VERSION ""

NS_ :

BS_:

BU_: ECM

BO_ 2566834691 DM1_s3: 22 Vector__XXX
 SG_ FailureModeIdentifier5 : 160|5@1+ (1,0) [0|0] "" Vector__XXX
 SG_ FailureModeIdentifier4 : 128|5@1+ (1,0) [0|0] "" Vector__XXX
 SG_ FailureModeIdentifier3 : 96|5@1+ (1,0) [0|0] "" Vector__XXX
 SG_ FailureModeIdentifier2 : 64|5@1+ (1,0) [0|0] "" Vector__XXX
 SG_ FailureModeIdentifier1 : 32|5@1+ (1,0) [0|0] "" Vector__XXX
 SG_ SPN5 : 144|16@1+ (1,0) [0|65536] "" Vector__XXX
 SG_ SPN4 : 112|16@1+ (1,0) [0|65536] "" Vector__XXX
 SG_ SPN3 : 80|16@1+ (1,0) [0|65536] "" Vector__XXX
 SG_ SPN2 : 48|16@1+ (1,0) [0|65536] "" Vector__XXX
 SG_ SPN1 : 16|16@1+ (1,0) [0|65536] "" Vector__XXX
 SG_ RedStopLampStatus : 4|2@1+ (1,0) [0|3] "" Vector__XXX
 SG_ ProtectLampStatus : 0|2@1+ (1,0) [0|3] "" Vector__XXX
 SG_ AmberWarningLampStatus : 2|2@1+ (1,0) [0|3] "" Vector__XXX
 SG_ MalfunctionIndicatorLampStatus : 6|2@1+ (1,0) [0|3] "" Vector__XXX
 SG_ FlashRedStopLamp : 12|2@1+ (1,0) [0|3] "" Vector__XXX
 SG_ FlashProtectLamp : 8|2@1+ (1,0) [0|3] "" Vector__XXX
 SG_ FlashMalfuncIndicatorLamp : 14|2@1+ (1,0) [0|3] "" Vector__XXX
 SG_ FlashAmberWarningLamp : 10|2@1+ (1,0) [0|3] "" Vector__XXX
 SG_ OccurenceCount1 : 40|7@1+ (1,0) [0|126] "" Vector__XXX
 SG_ SPNConversionMethod1 : 47|1@1+ (1,0) [0|1] "" Vector__XXX
 SG_ SPNConversionMethod5 : 175|1@1+ (1,0) [0|1] "" Vector__XXX
 SG_ SPNConversionMethod4 : 143|1@1+ (1,0) [0|1] "" Vector__XXX
 SG_ SPNConversionMethod3 : 111|1@1+ (1,0) [0|1] "" Vector__XXX
 SG_ SPNConversionMethod2 : 79|1@1+ (1,0) [0|1] "" Vector__XXX
 SG_ OccurenceCount5 : 168|7@1+ (1,0) [0|126] "" Vector__XXX
 SG_ OccurenceCount4 : 136|7@1+ (1,0) [0|126] "" Vector__XXX
 SG_ OccurenceCount3 : 104|7@1+ (1,0) [0|126] "" Vector__XXX
 SG_ OccurenceCount2 : 72|7@1+ (1,0) [0|126] "" Vector__XXX
 SG_ SPN5High : 165|3@1+ (1,0) [0|7] "" Vector__XXX
 SG_ SPN4High : 133|3@1+ (1,0) [0|7] "" Vector__XXX
 SG_ SPN3High : 101|3@1+ (1,0) [0|7] "" Vector__XXX
 SG_ SPN2High : 69|3@1+ (1,0) [0|7] "" Vector__XXX
 SG_ SPN1High : 37|3@1+ (1,0) [0|7] "" Vector__XXX

BO_ 2566834711 DM1_s23: 22 Vector__XXX
 SG_ FailureModeIdentifier5 : 160|5@1+ (1,0) [0|0] "" Vector__XXX
 SG_ FailureModeIdentifier4 : 128|5@1+ (1,0) [0|0] "" Vector__XXX
 SG_ FailureModeIdentifier3 : 96|5@1+ (1,0) [0|0] "" Vector__XXX
 SG_ FailureModeIdentifier2 : 64|5@1+ (1,0) [0|0] "" Vector__XXX
 SG_ FailureModeIdentifier1 : 32|5@1+ (1,0) [0|0] "" Vector__XXX
 SG_ SPN5 : 144|16@1+ (1,0) [0|65536] "" Vector__XXX
 SG_ SPN4 : 112|16@1+ (1,0) [0|65536] "" Vector__XXX
 SG_ SPN3 : 80|16@1+ (1,0) [0|65536] "" Vector__XXX
 SG_ SPN2 : 48|16@1+ (1,0) [0|65536] "" Vector__XXX
 SG_ SPN1 : 16|16@1+ (1,0) [0|65536] "" Vector__XXX
 SG_ RedStopLampStatus : 4|2@1+ (1,0) [0|3] "" Vector__XXX
 SG_ ProtectLampStatus : 0|2@1+ (1,0) [0|3] "" Vector__XXX
 SG_ AmberWarningLampStatus : 2|2@1+ (1,0) [0|3] "" Vector__XXX
 SG_ MalfunctionIndicatorLampStatus : 6|2@1+ (1,0) [0|3] "" Vector__XXX
 SG_ FlashRedStopLamp : 12|2@1+ (1,0) [0|3] "" Vector__XXX
 SG_ FlashProtectLamp : 8|2@1+ (1,0) [0|3] "" Vector__XXX
 SG_ FlashMalfuncIndicatorLamp : 14|2@1+ (1,0) [0|3] "" Vector__XXX
 SG_ FlashAmberWarningLamp : 10|2@1+ (1,0) [0|3] "" Vector__XXX
 SG_ OccurenceCount1 : 40|7@1+ (1,0) [0|126] "" Vector__XXX
 SG_ SPNConversionMethod1 : 47|1@1+ (1,0) [0|1] "" Vector__XXX
 SG_ SPNConversionMethod5 : 175|1@1+ (1,0) [0|1] "" Vector__XXX
 SG_ SPNConversionMethod4 : 143|1@1+ (1,0) [0|1] "" Vector__XXX
 SG_ SPNConversionMethod3 : 111|1@1+ (1,0) [0|1] "" Vector__XXX
 SG_ SPNConversionMethod2 : 79|1@1+ (1,0) [0|1] "" Vector__XXX
 SG_ OccurenceCount5 : 168|7@1+ (1,0) [0|126] "" Vector__XXX
 SG_ OccurenceCount4 : 136|7@1+ (1,0) [0|126] "" Vector__XXX
 SG_ OccurenceCount3 : 104|7@1+ (1,0) [0|126] "" Vector__XXX
 SG_ OccurenceCount2 : 72|7@1+ (1,0) [0|126] "" Vector__XXX
 SG_ SPN5High : 165|3@1+ (1,0) [0|7] "" Vector__XXX
 SG_ SPN4High : 133|3@1+ (1,0) [0|7] "" Vector__XXX
 SG_ SPN3High : 101|3@1+ (1,0) [0|7] "" Vector__XXX
 SG_ SPN2High : 69|3@1+ (1,0) [0|7] "" Vector__XXX
 SG_ SPN1High : 37|3@1+ (1,0) [0|7] "" Vector__XXX

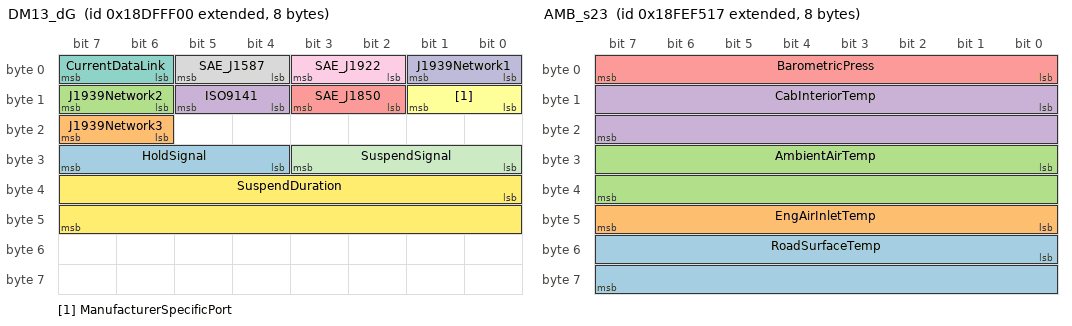
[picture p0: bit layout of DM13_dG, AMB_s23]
BO_ 2564816640 DM13_dG: 8 Vector__XXX
 SG_ HoldSignal : 28|4@1+ (1,0) [0|15] "" Vector__XXX
 SG_ J1939Network3 : 22|2@1+ (1,0) [0|3] "" Vector__XXX
 SG_ J1939Network2 : 14|2@1+ (1,0) [0|3] "" Vector__XXX
 SG_ ISO9141 : 12|2@1+ (1,0) [0|3] "" Vector__XXX
 SG_ SAE_J1850 : 10|2@1+ (1,0) [0|3] "" Vector__XXX
 SG_ ManufacturerSpecificPort : 8|2@1+ (1,0) [0|3] "" Vector__XXX
 SG_ CurrentDataLink : 6|2@1+ (1,0) [0|3] "" Vector__XXX
 SG_ SAE_J1587 : 4|2@1+ (1,0) [0|3] "" Vector__XXX
 SG_ SAE_J1922 : 2|2@1+ (1,0) [0|3] "" Vector__XXX
 SG_ J1939Network1 : 0|2@1+ (1,0) [0|3] "" Vector__XXX
 SG_ SuspendSignal : 24|4@1+ (1,0) [0|15] "" Vector__XXX
 SG_ SuspendDuration : 32|16@1+ (1,0) [0|64255] "seconds" Vector__XXX

BO_ 2566844705 CCVS_s33: 8 Vector__XXX
 SG_ EngIdleIncrementSwitch : 56|2@1+ (1,0) [0|3] "" Vector__XXX
 SG_ EngIdleDecrementSwitch : 58|2@1+ (1,0) [0|3] "" Vector__XXX
 SG_ EngShutdownOverrideSwitch : 62|2@1+ (1,0) [0|3] "" Vector__XXX
 SG_ EngTestModeSwitch : 60|2@1+ (1,0) [0|3] "" Vector__XXX
 SG_ CruiseCtrlStates : 53|3@1+ (1,0) [0|7] "" Vector__XXX
 SG_ PTOState : 48|5@1+ (1,0) [0|31] "" Vector__XXX
 SG_ CruiseCtrlSetSpeed : 40|8@1+ (1,0) [0|250] "km/h" Vector__XXX
 SG_ CruiseCtrlAccelerateSwitch : 38|2@1+ (1,0) [0|3] "" Vector__XXX
 SG_ CruiseCtrlResumeSwitch : 36|2@1+ (1,0) [0|3] "" Vector__XXX
 SG_ CruiseCtrlCoastSwitch : 34|2@1+ (1,0) [0|3] "" Vector__XXX
 SG_ CruiseCtrlSetSwitch : 32|2@1+ (1,0) [0|3] "" Vector__XXX
 SG_ ClutchSwitch : 30|2@1+ (1,0) [0|3] "" Vector__XXX
 SG_ BrakeSwitch : 28|2@1+ (1,0) [0|3] "" Vector__XXX
 SG_ CruiseCtrlEnableSwitch : 26|2@1+ (1,0) [0|3] "" Vector__XXX
 SG_ CruiseCtrlActive : 24|2@1+ (1,0) [0|3] "" Vector__XXX
 SG_ WheelBasedVehicleSpeed : 8|16@1+ (0.00390625,0) [0|250.996] "km/h" Vector__XXX
 SG_ CruiseCtrlPauseSwitch : 4|2@1+ (1,0) [0|3] "" Vector__XXX
 SG_ ParkingBrakeSwitch : 2|2@1+ (1,0) [0|3] "" Vector__XXX
 SG_ TwoSpeedAxleSwitch : 0|2@1+ (1,0) [0|3] "" Vector__XXX

BO_ 2566845719 AMB_s23: 8 Vector__XXX
 SG_ RoadSurfaceTemp : 48|16@1+ (0.03125,-273) [-273|1735] "°C" Vector__XXX
 SG_ EngAirInletTemp : 40|8@1+ (1,-40) [-40|210] "°C" Vector__XXX
 SG_ AmbientAirTemp : 24|16@1+ (0.03125,-273) [-273|1735] "°C" Vector__XXX
 SG_ CabInteriorTemp : 8|16@1+ (0.03125,-273) [-273|1735] "°C" Vector__XXX
 SG_ BarometricPress : 0|8@1+ (0.5,0) [0|125] "kPa" Vector__XXX

BO_ 2565347072 ACKM_d23: 8 Vector__XXX
 SG_ AddressBusy m3 : 32|8@1+ (1,0) [0|255] "" Vector__XXX
 SG_ ParameterGroupNumber : 40|24@1+ (1,0) [0|16777215] "" Vector__XXX
 SG_ GroupFunctionValue : 8|8@1+ (1,0) [0|255] "" Vector__XXX
 SG_ ControlByte M : 0|8@1+ (1,0) [0|255] "" Vector__XXX
 SG_ AddressAccessDenied m2 : 32|8@1+ (1,0) [0|255] "" Vector__XXX
 SG_ AddressNegativeAcknowledgement m1 : 32|8@1+ (1,0) [0|255] "" Vector__XXX
 SG_ AddressAcknowledged m0 : 32|8@1+ (1,0) [0|255] "" Vector__XXX

BO_ 2565480727 RQST_d33: 3 Vector__XXX
 SG_ ParameterGroupNumber : 0|24@1+ (1,0) [0|16777215] "" Vector__XXX

BO_ 2565537785 RQST_S249_dall: 3 Vector__XXX
 SG_ ParameterGroupNumber : 0|24@1+ (1,0) [0|16777215] "" Vector__XXX

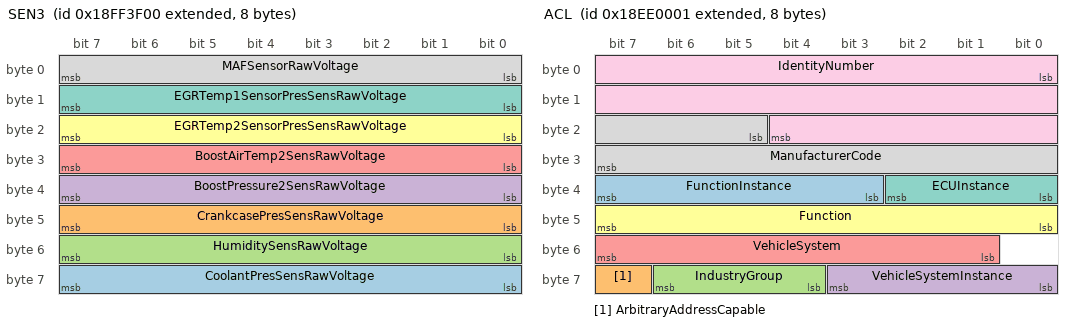
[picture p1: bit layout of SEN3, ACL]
BO_ 2566864640 SEN3: 8 Vector__XXX
 SG_ CoolantPresSensRawVoltage : 56|8@1+ (20,0) [0|5000] "mV" Vector__XXX
 SG_ CrankcasePresSensRawVoltage : 40|8@1+ (20,0) [0|5000] "mV" Vector__XXX
 SG_ HumiditySensRawVoltage : 48|8@1+ (20,0) [0|5000] "mV" Vector__XXX
 SG_ BoostPressure2SensRawVoltage : 32|8@1+ (20,0) [0|5000] "mV" Vector__XXX
 SG_ BoostAirTemp2SensRawVoltage : 24|8@1+ (20,0) [0|5000] "mV" Vector__XXX
 SG_ EGRTemp2SensorPresSensRawVoltage : 16|8@1+ (20,0) [0|5000] "mV" Vector__XXX
 SG_ EGRTemp1SensorPresSensRawVoltage : 8|8@1+ (20,0) [0|5000] "mV" Vector__XXX
 SG_ MAFSensorRawVoltage : 0|8@1+ (20,0) [0|5000] "mV" Vector__XXX

BO_ 2566750208 DM28: 22 Vector__XXX
 SG_ FailureModeIdentifier5 : 160|5@1+ (1,0) [0|0] "" Vector__XXX
 SG_ FailureModeIdentifier4 : 128|5@1+ (1,0) [0|0] "" Vector__XXX
 SG_ FailureModeIdentifier3 : 96|5@1+ (1,0) [0|0] "" Vector__XXX
 SG_ FailureModeIdentifier2 : 64|5@1+ (1,0) [0|0] "" Vector__XXX
 SG_ FailureModeIdentifier1 : 32|5@1+ (1,0) [0|0] "" Vector__XXX
 SG_ FlashRedStopLamp : 12|2@1+ (1,0) [0|3] "" Vector__XXX
 SG_ FlashProtectLamp : 8|2@1+ (1,0) [0|3] "" Vector__XXX
 SG_ FlashMalfuncIndicatorLamp : 14|2@1+ (1,0) [0|3] "" Vector__XXX
 SG_ FlashAmberWarningLamp : 10|2@1+ (1,0) [0|3] "" Vector__XXX
 SG_ OccurenceCount5 : 168|7@1+ (1,0) [0|126] "" Vector__XXX
 SG_ OccurenceCount4 : 136|7@1+ (1,0) [0|126] "" Vector__XXX
 SG_ OccurenceCount3 : 104|7@1+ (1,0) [0|126] "" Vector__XXX
 SG_ OccurenceCount2 : 72|7@1+ (1,0) [0|126] "" Vector__XXX
 SG_ SPNConversionMethod5 : 175|1@1+ (1,0) [0|1] "" Vector__XXX
 SG_ SPNConversionMethod4 : 143|1@1+ (1,0) [0|1] "" Vector__XXX
 SG_ SPNConversionMethod3 : 111|1@1+ (1,0) [0|1] "" Vector__XXX
 SG_ SPNConversionMethod2 : 79|1@1+ (1,0) [0|1] "" Vector__XXX
 SG_ SPNConversionMethod1 : 47|1@1+ (1,0) [0|1] "" Vector__XXX
 SG_ SPN5High : 165|3@1+ (1,0) [0|7] "" Vector__XXX
 SG_ SPN5 : 144|16@1+ (1,0) [0|65536] "" Vector__XXX
 SG_ SPN4High : 133|3@1+ (1,0) [0|7] "" Vector__XXX
 SG_ SPN4 : 112|16@1+ (1,0) [0|65536] "" Vector__XXX
 SG_ SPN3High : 101|3@1+ (1,0) [0|7] "" Vector__XXX
 SG_ SPN3 : 80|16@1+ (1,0) [0|65536] "" Vector__XXX
 SG_ SPN2High : 69|3@1+ (1,0) [0|7] "" Vector__XXX
 SG_ SPN2 : 48|16@1+ (1,0) [0|65536] "" Vector__XXX
 SG_ SPN1High : 37|3@1+ (1,0) [0|7] "" Vector__XXX
 SG_ SPN1 : 16|16@1+ (1,0) [0|65536] "" Vector__XXX
 SG_ RedStopLampStatus : 4|2@1+ (1,0) [0|3] "" Vector__XXX
 SG_ ProtectLampStatus : 0|2@1+ (1,0) [0|3] "" Vector__XXX
 SG_ AmberWarningLampStatus : 2|2@1+ (1,0) [0|3] "" Vector__XXX
 SG_ MalfunctionIndicatorLampStatus : 6|2@1+ (1,0) [0|3] "" Vector__XXX
 SG_ OccurenceCount1 : 40|7@1+ (1,0) [0|126] "" Vector__XXX

BO_ 2566750720 DM27: 22 Vector__XXX
 SG_ OccurenceCount5 : 168|7@1+ (1,0) [0|126] "" Vector__XXX
 SG_ OccurenceCount4 : 136|7@1+ (1,0) [0|126] "" Vector__XXX
 SG_ OccurenceCount3 : 104|7@1+ (1,0) [0|126] "" Vector__XXX
 SG_ OccurenceCount2 : 72|7@1+ (1,0) [0|126] "" Vector__XXX
 SG_ SPNConversionMethod5 : 175|1@1+ (1,0) [0|1] "" Vector__XXX
 SG_ SPNConversionMethod4 : 143|1@1+ (1,0) [0|1] "" Vector__XXX
 SG_ SPNConversionMethod3 : 111|1@1+ (1,0) [0|1] "" Vector__XXX
 SG_ SPNConversionMethod2 : 79|1@1+ (1,0) [0|1] "" Vector__XXX
 SG_ SPN5High : 165|3@1+ (1,0) [0|7] "" Vector__XXX
 SG_ SPN5 : 144|16@1+ (1,0) [0|65536] "" Vector__XXX
 SG_ SPN4High : 133|3@1+ (1,0) [0|7] "" Vector__XXX
 SG_ SPN4 : 112|16@1+ (1,0) [0|65536] "" Vector__XXX
 SG_ SPN3High : 101|3@1+ (1,0) [0|7] "" Vector__XXX
 SG_ SPN3 : 80|16@1+ (1,0) [0|65536] "" Vector__XXX
 SG_ SPN2High : 69|3@1+ (1,0) [0|7] "" Vector__XXX
 SG_ SPN2 : 48|16@1+ (1,0) [0|65536] "" Vector__XXX
 SG_ SPN1High : 37|3@1+ (1,0) [0|7] "" Vector__XXX
 SG_ SPN1 : 16|16@1+ (1,0) [0|65536] "" Vector__XXX
 SG_ FailureModeIdentifier5 : 160|5@1+ (1,0) [0|0] "" Vector__XXX
 SG_ FailureModeIdentifier4 : 128|5@1+ (1,0) [0|0] "" Vector__XXX
 SG_ FailureModeIdentifier3 : 96|5@1+ (1,0) [0|0] "" Vector__XXX
 SG_ FailureModeIdentifier2 : 64|5@1+ (1,0) [0|0] "" Vector__XXX
 SG_ FailureModeIdentifier1 : 32|5@1+ (1,0) [0|0] "" Vector__XXX
 SG_ FlashRedStopLamp : 12|2@1+ (1,0) [0|3] "" Vector__XXX
 SG_ FlashProtectLamp : 8|2@1+ (1,0) [0|3] "" Vector__XXX
 SG_ FlashMalfuncIndicatorLamp : 14|2@1+ (1,0) [0|3] "" Vector__XXX
 SG_ FlashAmberWarningLamp : 10|2@1+ (1,0) [0|3] "" Vector__XXX
 SG_ RedStopLampStatus : 4|2@1+ (1,0) [0|3] "" Vector__XXX
 SG_ ProtectLampStatus : 0|2@1+ (1,0) [0|3] "" Vector__XXX
 SG_ AmberWarningLampStatus : 2|2@1+ (1,0) [0|3] "" Vector__XXX
 SG_ MalfunctionIndicatorLampStatus : 6|2@1+ (1,0) [0|3] "" Vector__XXX
 SG_ OccurenceCount1 : 40|7@1+ (1,0) [0|126] "" Vector__XXX
 SG_ SPNConversionMethod1 : 47|1@1+ (1,0) [0|1] "" Vector__XXX

BO_ 2566886393 DTHM: 8 Vector__XXX

BO_ 2565734401 ACL: 8 Vector__XXX
 SG_ FunctionInstance : 35|5@1- (1,0) [0|31] "" Vector__XXX
 SG_ ArbitraryAddressCapable : 63|1@1+ (1,0) [0|1] "" Vector__XXX
 SG_ IndustryGroup : 60|3@1+ (1,0) [0|7] "" Vector__XXX
 SG_ VehicleSystemInstance : 56|4@1+ (1,0) [0|15] "" Vector__XXX
 SG_ VehicleSystem : 49|7@1+ (1,0) [0|127] "" Vector__XXX
 SG_ Function : 40|8@1+ (1,0) [0|255] "" Vector__XXX
 SG_ ECUInstance : 32|3@1+ (1,0) [0|7] "" Vector__XXX
 SG_ ManufacturerCode : 21|11@1- (1,0) [0|2047] "" Vector__XXX
 SG_ IdentityNumber : 0|21@1- (1,0) [0|2097152] "" Vector__XXX

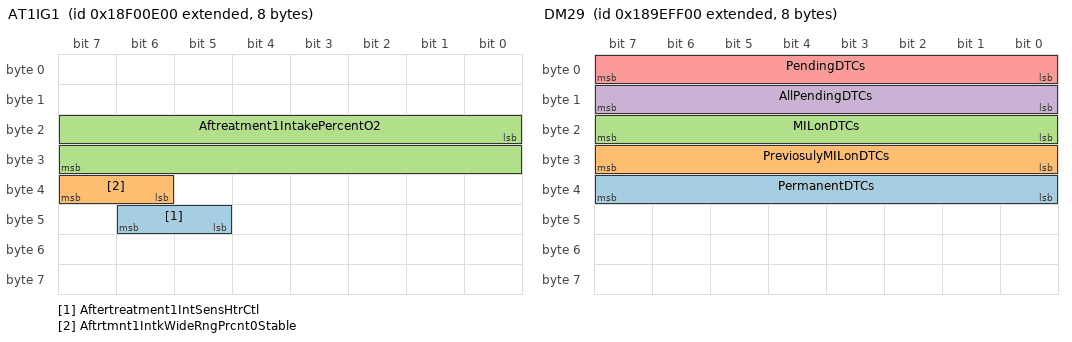
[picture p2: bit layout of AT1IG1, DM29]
BO_ 2565869056 AT1IG1: 8 Vector__XXX
 SG_ Aftertreatment1IntSensHtrCtl : 45|2@1+ (1,0) [0|3] "" Vector__XXX
 SG_ Aftrtmnt1IntkWideRngPrcnt0Stable : 38|2@1+ (1,0) [0|3] "" Vector__XXX
 SG_ Aftreatment1IntakePercentO2 : 16|16@1+ (0.000514,-12) [-12|21.68499] "%" Vector__XXX

BO_ 2566770688 IC2: 8 Vector__XXX
 SG_ EngineIntakeManifold1AbsPress : 32|8@1+ (2,0) [0|500] "kPa" Vector__XXX

BO_ 2560556800 DM29: 8 Vector__XXX
 SG_ PermanentDTCs : 32|8@1- (1,0) [0|250] "" Vector__XXX
 SG_ PreviosulyMILonDTCs : 24|8@1- (1,0) [0|250] "" Vector__XXX
 SG_ MILonDTCs : 16|8@1- (1,0) [0|250] "" Vector__XXX
 SG_ AllPendingDTCs : 8|8@1- (1,0) [0|250] "" Vector__XXX
 SG_ PendingDTCs : 0|8@1- (1,0) [0|250] "" Vector__XXX

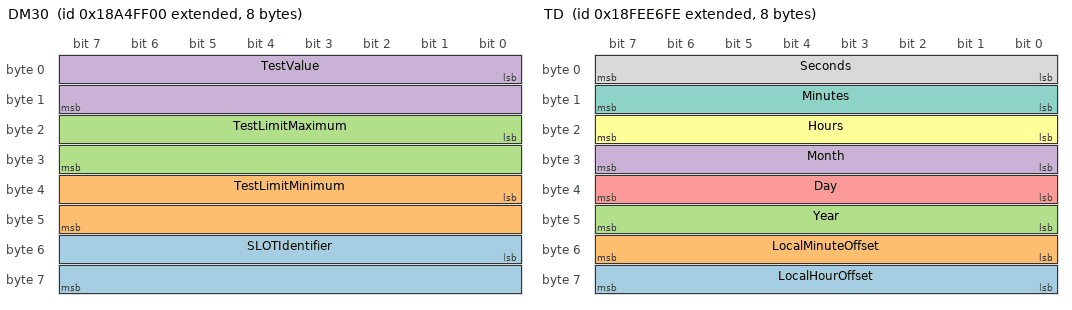
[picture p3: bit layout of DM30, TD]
BO_ 2560950016 DM30: 8 Vector__XXX
 SG_ SLOTIdentifier : 48|16@1+ (1,0) [0|64255] "" Vector__XXX
 SG_ TestLimitMinimum : 32|16@1+ (1,0) [0|64255] "" Vector__XXX
 SG_ TestLimitMaximum : 16|16@1+ (1,0) [0|64255] "" Vector__XXX
 SG_ TestValue : 0|16@1+ (1,0) [0|64255] "" Vector__XXX

BO_ 2566842110 TD: 8 Vector__XXX
 SG_ LocalHourOffset : 56|8@1- (1,-125) [-125|125] "hour" Vector__XXX
 SG_ LocalMinuteOffset : 48|8@1- (1,-125) [-125|125] "min" Vector__XXX
 SG_ Year : 40|8@1+ (1,1985) [1985|2240] "" Vector__XXX
 SG_ Month : 24|8@1+ (1,0) [0|250] "" Vector__XXX
 SG_ Day : 32|8@1+ (0.25,0) [0|62.5] "days" Vector__XXX
 SG_ Hours : 16|8@1+ (1,0) [0|255] "" Vector__XXX
 SG_ Minutes : 8|8@1+ (1,0) [0|256] "min" Vector__XXX
 SG_ Seconds : 0|8@1+ (0.25,0) [0|63.75] "sec" Vector__XXX

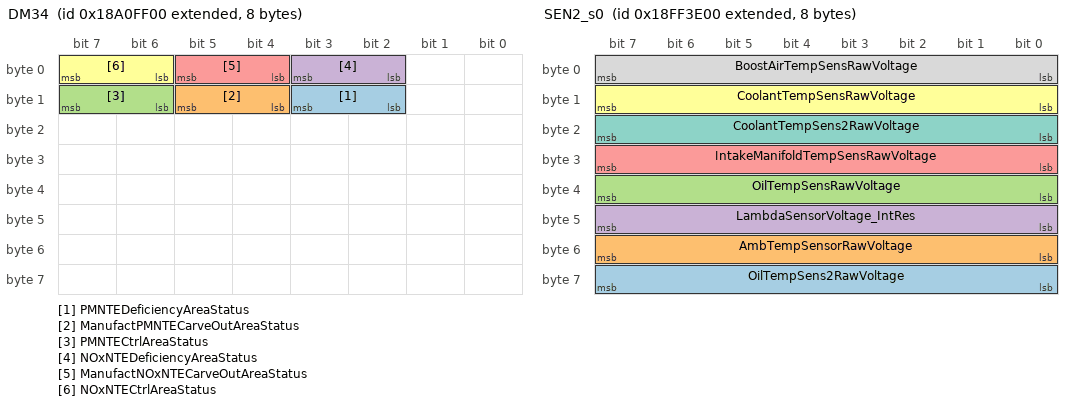
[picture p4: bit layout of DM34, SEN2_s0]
BO_ 2560687872 DM34: 8 Vector__XXX
 SG_ PMNTEDeficiencyAreaStatus : 10|2@1+ (1,0) [0|3] "" Vector__XXX
 SG_ ManufactPMNTECarveOutAreaStatus : 12|2@1+ (1,0) [0|3] "" Vector__XXX
 SG_ PMNTECtrlAreaStatus : 14|2@1+ (1,0) [0|3] "" Vector__XXX
 SG_ NOxNTEDeficiencyAreaStatus : 2|2@1+ (1,0) [0|3] "" Vector__XXX
 SG_ ManufactNOxNTECarveOutAreaStatus : 4|2@1+ (1,0) [0|3] "" Vector__XXX
 SG_ NOxNTECtrlAreaStatus : 6|2@1+ (1,0) [0|3] "" Vector__XXX

BO_ 2566755328 EEC7: 8 Vector__XXX
 SG_ Breather_Sep_Speed : 32|16@1+ (1,0) [0|64255] "rpm" Vector__XXX
 SG_ EGRVlvPosition : 0|16@1+ (0.0025,0) [0|160.6375] "%" Vector__XXX

BO_ 2566743552 ET4: 8 Vector__XXX
 SG_ EngCoolantTemp2 : 0|8@1+ (1,-40) [-40|210] "°C" Vector__XXX

BO_ 2566822144 TCI3: 8 Vector__XXX
 SG_ EngTurbo2CompressorInletPress : 16|16@1+ (0.0078125,-250) [-250|261.9921875] "kPa" Vector__XXX

BO_ 2566864384 SEN2_s0: 8 Vector__XXX
 SG_ OilTempSens2RawVoltage : 56|8@1+ (20,0) [0|5000] "mV" Vector__XXX
 SG_ AmbTempSensorRawVoltage : 48|8@1+ (19.608,0) [0|5000] "mV" Vector__XXX
 SG_ OilTempSensRawVoltage : 32|8@1+ (20,0) [0|5000] "mV" Vector__XXX
 SG_ LambdaSensorVoltage_IntRes : 40|8@1+ (20,0) [0|5000] "mV" Vector__XXX
 SG_ IntakeManifoldTempSensRawVoltage : 24|8@1+ (20,0) [0|5000] "mV" Vector__XXX
 SG_ CoolantTempSensRawVoltage : 8|8@1+ (20,0) [0|5000] "mV" Vector__XXX
 SG_ CoolantTempSens2RawVoltage : 16|8@1+ (20,0) [0|5000] "mV" Vector__XXX
 SG_ BoostAirTempSensRawVoltage : 0|8@1+ (20,0) [0|5000] "mV" Vector__XXX

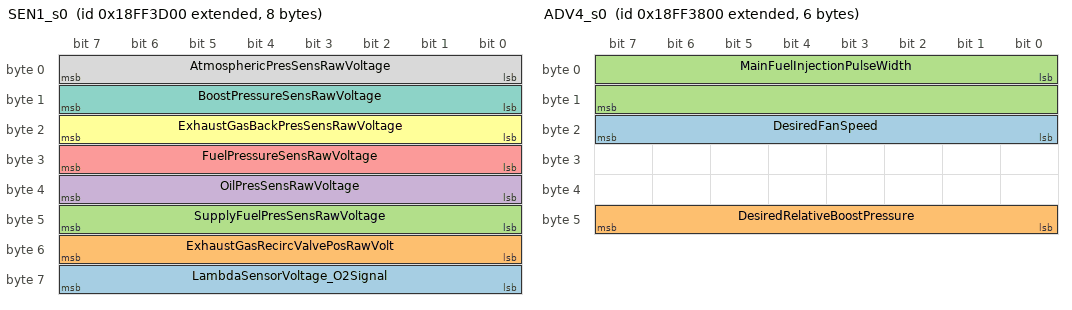
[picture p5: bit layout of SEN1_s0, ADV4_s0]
BO_ 2566864128 SEN1_s0: 8 Vector__XXX
 SG_ LambdaSensorVoltage_O2Signal : 56|8@1+ (20,0) [0|5000] "mV" Vector__XXX
 SG_ ExhaustGasRecircValvePosRawVolt : 48|8@1+ (20,0) [0|5000] "mV" Vector__XXX
 SG_ SupplyFuelPresSensRawVoltage : 40|8@1+ (20,0) [0|5000] "mV" Vector__XXX
 SG_ OilPresSensRawVoltage : 32|8@1+ (20,0) [0|5000] "mV" Vector__XXX
 SG_ FuelPressureSensRawVoltage : 24|8@1+ (20,0) [0|5000] "mV" Vector__XXX
 SG_ ExhaustGasBackPresSensRawVoltage : 16|8@1+ (20,0) [0|5000] "mV" Vector__XXX
 SG_ BoostPressureSensRawVoltage : 8|8@1+ (20,0) [0|5000] "mV" Vector__XXX
 SG_ AtmosphericPresSensRawVoltage : 0|8@1+ (20,0) [0|5000] "mV" Vector__XXX

BO_ 2566862848 ADV4_s0: 6 Vector__XXX
 SG_ DesiredFanSpeed : 16|8@1+ (14,0) [0|3570] "rpm" Vector__XXX
 SG_ DesiredRelativeBoostPressure : 40|8@1+ (2,0) [0|500] "kPa" Vector__XXX
 SG_ MainFuelInjectionPulseWidth : 0|16@1+ (0.58,0) [0|37448] "microsec" Vector__XXX

BO_ 2566862080 ADV1_s0: 8 Vector__XXX
 SG_ LambdaSensorMeasuredValue : 40|8@1+ (0.1,0) [0|25] "" Vector__XXX
 SG_ LambdaSensorTemperatureValue : 24|8@1+ (1,600) [600|850] "C" Vector__XXX

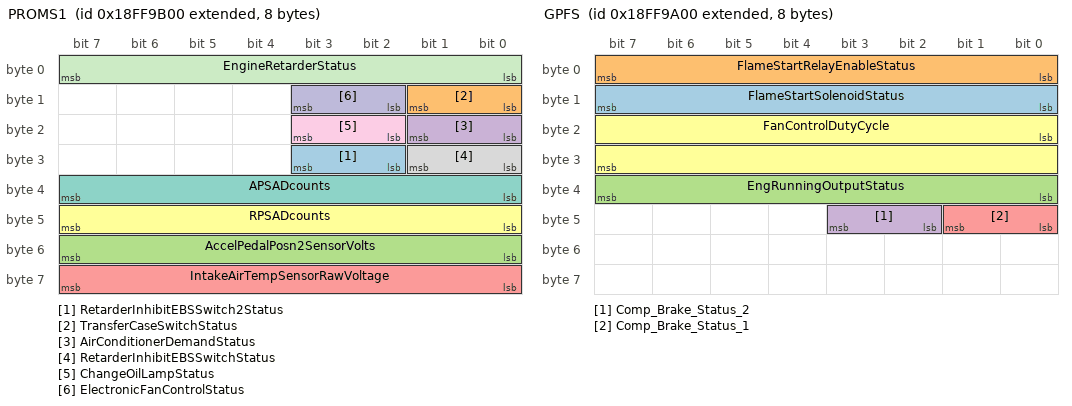
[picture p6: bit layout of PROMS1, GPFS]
BO_ 2566888192 PROMS1: 8 Vector__XXX
 SG_ RetarderInhibitEBSSwitch2Status : 26|2@1+ (1,0) [0|3] "flag" Vector__XXX
 SG_ TransferCaseSwitchStatus : 8|2@1+ (1,0) [0|3] "flag" Vector__XXX
 SG_ AccelPedalPosn2SensorVolts : 48|8@1+ (0.0196,0) [0|4.91764] "Volts" Vector__XXX
 SG_ AirConditionerDemandStatus : 16|2@1+ (1,0) [0|3] "flag" Vector__XXX
 SG_ IntakeAirTempSensorRawVoltage : 56|8@1+ (19.608,0) [0|5000] "mV" Vector__XXX
 SG_ RPSADcounts : 40|8@1+ (0.0196,0) [0|4.91764] "Volts" Vector__XXX
 SG_ APSADcounts : 32|8@1+ (0.0196,0) [0|4.91764] "Volts" Vector__XXX
 SG_ RetarderInhibitEBSSwitchStatus : 24|2@1+ (1,0) [0|3] "flag" Vector__XXX
 SG_ ChangeOilLampStatus : 18|2@1+ (1,0) [0|3] "flag" Vector__XXX
 SG_ ElectronicFanControlStatus : 10|2@1+ (1,0) [0|3] "flag" Vector__XXX
 SG_ EngineRetarderStatus : 0|8@1+ (1,0) [0|255] "flag" Vector__XXX

BO_ 2566887936 GPFS: 8 Vector__XXX
 SG_ FlameStartSolenoidStatus : 8|8@1+ (1,0) [0|255] "" Vector__XXX
 SG_ FlameStartRelayEnableStatus : 0|8@1+ (1,0) [0|255] "" Vector__XXX
 SG_ EngRunningOutputStatus : 32|8@1+ (1,0) [0|255] "" Vector__XXX
 SG_ Comp_Brake_Status_2 : 42|2@1+ (1,0) [0|3] "" Vector__XXX
 SG_ Comp_Brake_Status_1 : 40|2@1+ (1,0) [0|3] "" Vector__XXX
 SG_ FanControlDutyCycle : 16|16@1+ (1.556E-005,0) [0|1.0197246] "" Vector__XXX

BO_ 2566888448 PROID1: 70 Vector__XXX
 SG_ VEH_MOD_10 : 552|8@1+ (1,0) [0|255] "ASCII" Vector__XXX
 SG_ VEH_MOD_09 : 544|8@1+ (1,0) [0|255] "ASCII" Vector__XXX
 SG_ VEH_MOD_08 : 536|8@1+ (1,0) [0|255] "ASCII" Vector__XXX
 SG_ VEH_MOD_07 : 528|8@1+ (1,0) [0|255] "ASCII" Vector__XXX
 SG_ VEH_MOD_06 : 520|8@1+ (1,0) [0|255] "ASCII" Vector__XXX
 SG_ VEH_MOD_05 : 512|8@1+ (1,0) [0|255] "ASCII" Vector__XXX
 SG_ VEH_MOD_04 : 504|8@1+ (1,0) [0|255] "ASCII" Vector__XXX
 SG_ VEH_MOD_03 : 496|8@1+ (1,0) [0|255] "ASCII" Vector__XXX
 SG_ VEH_MOD_02 : 488|8@1+ (1,0) [0|255] "ASCII" Vector__XXX
 SG_ VEH_MOD_01 : 480|8@1+ (1,0) [0|255] "ASCII" Vector__XXX
 SG_ ENG_TYPE_ID_20 : 472|8@1+ (1,0) [0|255] "ASCII" Vector__XXX
 SG_ ENG_TYPE_ID_19 : 464|8@1+ (1,0) [0|255] "ASCII" Vector__XXX
 SG_ ENG_TYPE_ID_18 : 456|8@1+ (1,0) [0|255] "ASCII" Vector__XXX
 SG_ ENG_TYPE_ID_17 : 448|8@1+ (1,0) [0|255] "ASCII" Vector__XXX
 SG_ ENG_TYPE_ID_16 : 440|8@1+ (1,0) [0|255] "ASCII" Vector__XXX
 SG_ ENG_TYPE_ID_15 : 432|8@1+ (1,0) [0|255] "ASCII" Vector__XXX
 SG_ ENG_TYPE_ID_14 : 424|8@1+ (1,0) [0|255] "ASCII" Vector__XXX
 SG_ ENG_TYPE_ID_13 : 416|8@1+ (1,0) [0|255] "ASCII" Vector__XXX
 SG_ ENG_TYPE_ID_12 : 408|8@1+ (1,0) [0|255] "ASCII" Vector__XXX
 SG_ ENG_TYPE_ID_11 : 400|8@1+ (1,0) [0|255] "ASCII" Vector__XXX
 SG_ ENG_TYPE_ID_10 : 392|8@1+ (1,0) [0|255] "ASCII" Vector__XXX
 SG_ ENG_TYPE_ID_09 : 384|8@1+ (1,0) [0|255] "ASCII" Vector__XXX
 SG_ ENG_TYPE_ID_08 : 376|8@1+ (1,0) [0|255] "ASCII" Vector__XXX
 SG_ ENG_TYPE_ID_07 : 368|8@1+ (1,0) [0|255] "ASCII" Vector__XXX
 SG_ ENG_TYPE_ID_06 : 360|8@1+ (1,0) [0|255] "ASCII" Vector__XXX
 SG_ ENG_TYPE_ID_05 : 352|8@1+ (1,0) [0|255] "ASCII" Vector__XXX
 SG_ ENG_TYPE_ID_04 : 344|8@1+ (1,0) [0|255] "ASCII" Vector__XXX
 SG_ ENG_TYPE_ID_03 : 336|8@1+ (1,0) [0|255] "ASCII" Vector__XXX
 SG_ ENG_TYPE_ID_02 : 328|8@1+ (1,0) [0|255] "ASCII" Vector__XXX
 SG_ ENG_TYPE_ID_01 : 320|8@1+ (1,0) [0|255] "ASCII" Vector__XXX
 SG_ NRATED_APPL_ID_20 : 312|8@1+ (1,0) [0|255] "ASCII" Vector__XXX
 SG_ NRATED_APPL_ID_19 : 304|8@1+ (1,0) [0|255] "ASCII" Vector__XXX
 SG_ NRATED_APPL_ID_18 : 296|8@1+ (1,0) [0|255] "ASCII" Vector__XXX
 SG_ NRATED_APPL_ID_17 : 288|8@1+ (1,0) [0|255] "ASCII" Vector__XXX
 SG_ NRATED_APPL_ID_16 : 280|8@1+ (1,0) [0|255] "ASCII" Vector__XXX
 SG_ NRATED_APPL_ID_15 : 272|8@1+ (1,0) [0|255] "ASCII" Vector__XXX
 SG_ NRATED_APPL_ID_14 : 264|8@1+ (1,0) [0|255] "ASCII" Vector__XXX
 SG_ NRATED_APPL_ID_13 : 256|8@1+ (1,0) [0|255] "ASCII" Vector__XXX
 SG_ NRATED_APPL_ID_12 : 248|8@1+ (1,0) [0|255] "ASCII" Vector__XXX
 SG_ NRATED_APPL_ID_11 : 240|8@1+ (1,0) [0|255] "ASCII" Vector__XXX
 SG_ NRATED_APPL_ID_10 : 232|8@1+ (1,0) [0|255] "ASCII" Vector__XXX
 SG_ NRATED_APPL_ID_09 : 224|8@1+ (1,0) [0|255] "ASCII" Vector__XXX
 SG_ NRATED_APPL_ID_08 : 216|8@1+ (1,0) [0|255] "ASCII" Vector__XXX
 SG_ NRATED_APPL_ID_07 : 208|8@1+ (1,0) [0|255] "ASCII" Vector__XXX
 SG_ NRATED_APPL_ID_06 : 200|8@1+ (1,0) [0|255] "ASCII" Vector__XXX
 SG_ NRATED_APPL_ID_05 : 192|8@1+ (1,0) [0|255] "ASCII" Vector__XXX
 SG_ NRATED_APPL_ID_04 : 184|8@1+ (1,0) [0|255] "ASCII" Vector__XXX
 SG_ NRATED_APPL_ID_03 : 176|8@1+ (1,0) [0|255] "ASCII" Vector__XXX
 SG_ NRATED_APPL_ID_02 : 168|8@1+ (1,0) [0|255] "ASCII" Vector__XXX
 SG_ NRATED_APPL_ID_01 : 160|8@1+ (1,0) [0|255] "ASCII" Vector__XXX
 SG_ RATING_ID_20 : 152|8@1+ (1,0) [0|255] "ASCII" Vector__XXX
 SG_ RATING_ID_19 : 144|8@1+ (1,0) [0|255] "ASCII" Vector__XXX
 SG_ RATING_ID_18 : 136|8@1+ (1,0) [0|255] "ASCII" Vector__XXX
 SG_ RATING_ID_17 : 128|8@1+ (1,0) [0|255] "ASCII" Vector__XXX
 SG_ RATING_ID_16 : 120|8@1+ (1,0) [0|255] "ASCII" Vector__XXX
 SG_ RATING_ID_15 : 112|8@1+ (1,0) [0|255] "ASCII" Vector__XXX
 SG_ RATING_ID_14 : 104|8@1+ (1,0) [0|255] "ASCII" Vector__XXX
 SG_ RATING_ID_13 : 96|8@1+ (1,0) [0|255] "ASCII" Vector__XXX
 SG_ RATING_ID_12 : 88|8@1+ (1,0) [0|255] "ASCII" Vector__XXX
 SG_ RATING_ID_11 : 80|8@1+ (1,0) [0|255] "ASCII" Vector__XXX
 SG_ RATING_ID_10 : 72|8@1+ (1,0) [0|255] "ASCII" Vector__XXX
 SG_ RATING_ID_09 : 64|8@1+ (1,0) [0|255] "ASCII" Vector__XXX
 SG_ RATING_ID_08 : 56|8@1+ (1,0) [0|255] "ASCII" Vector__XXX
 SG_ RATING_ID_07 : 48|8@1+ (1,0) [0|255] "ASCII" Vector__XXX
 SG_ RATING_ID_06 : 40|8@1+ (1,0) [0|255] "ASCII" Vector__XXX
 SG_ RATING_ID_05 : 32|8@1+ (1,0) [0|255] "ASCII" Vector__XXX
 SG_ RATING_ID_04 : 24|8@1+ (1,0) [0|255] "ASCII" Vector__XXX
 SG_ RATING_ID_03 : 16|8@1+ (1,0) [0|255] "ASCII" Vector__XXX
 SG_ RATING_ID_02 : 8|8@1+ (1,0) [0|255] "ASCII" Vector__XXX
 SG_ RATING_ID_01 : 0|8@1+ (1,0) [0|255] "ASCII" Vector__XXX

CM_ BO_ 2566834691 "Active diagnostic trouble codes";
CM_ SG_ 2566834691 FailureModeIdentifier5 "The FMI defines the type of failure detected in the subsystem identified by an SPN.";
CM_ SG_ 2566834691 FailureModeIdentifier4 "The FMI defines the type of failure detected in the subsystem identified by an SPN.";
CM_ SG_ 2566834691 FailureModeIdentifier3 "The FMI defines the type of failure detected in the subsystem identified by an SPN.";
CM_ SG_ 2566834691 FailureModeIdentifier2 "The FMI defines the type of failure detected in the subsystem identified by an SPN.";
CM_ SG_ 2566834691 FailureModeIdentifier1 "The FMI defines the type of failure detected in the subsystem identified by an SPN.";
CM_ SG_ 2566834691 SPN5 "SPN #5 (Conversion Version 4)";
CM_ SG_ 2566834691 SPN4 "SPN #4 (Conversion Version 4)";
CM_ SG_ 2566834691 SPN3 "SPN #3 (Conversion Version 4)";
CM_ SG_ 2566834691 SPN2 "SPN #2 (Conversion Version 4)";
CM_ SG_ 2566834691 SPN1 "SPN #1 (Conversion Version 4)";
CM_ SG_ 2566834691 RedStopLampStatus "This lamp is uesed to relay trouble code information that is of a severe enought condition that it warrants stopping the vehicle.";
CM_ SG_ 2566834691 ProtectLampStatus "This lamp is used to relay trouble code informatio that is reporting a problem with a vehicle system that is most
probably not electronic subsystem related.";
CM_ SG_ 2566834691 AmberWarningLampStatus "This lamp is used to relay trouble code information that is reporting a problem with the vehicle system but the vehicle need
not be immediately stopped.";
CM_ SG_ 2566834691 MalfunctionIndicatorLampStatus "A lamp used to relay only emissions-related trouble code information.";
CM_ SG_ 2566834691 FlashRedStopLamp "This parameter provides the capability to flash the RSL (SPN 3039).";
CM_ SG_ 2566834691 FlashProtectLamp "This parameter provides the capability to flash the engine protect lamp (SPN 3041).";
CM_ SG_ 2566834691 FlashMalfuncIndicatorLamp "This parameter provides the capability to flash the MIL (SPN 3038).";
CM_ SG_ 2566834691 FlashAmberWarningLamp "This parameter provides the capability to flash the AWL (SPN 3040). ";
CM_ SG_ 2566834691 OccurenceCount1 "The 7 bit occurence count field contains the number of times a fault has gone from active to previously active.";
CM_ SG_ 2566834691 OccurenceCount5 "The 7 bit occurence count field contains the number of times a fault has gone from active to previously active.";
CM_ SG_ 2566834691 OccurenceCount4 "The 7 bit occurence count field contains the number of times a fault has gone from active to previously active.";
CM_ SG_ 2566834691 OccurenceCount3 "The 7 bit occurence count field contains the number of times a fault has gone from active to previously active.";
CM_ SG_ 2566834691 OccurenceCount2 "The 7 bit occurence count field contains the number of times a fault has gone from active to previously active.";
CM_ SG_ 2566834691 SPN5High "SPN #5 (Conversion Version 4)";
CM_ SG_ 2566834691 SPN4High "SPN #4 (Conversion Version 4)";
CM_ SG_ 2566834691 SPN3High "SPN #3 (Conversion Version 4)";
CM_ SG_ 2566834691 SPN2High "SPN #2 (Conversion Version 4)";
CM_ SG_ 2566834691 SPN1High "SPN #1 (Conversion Version 4)";
CM_ BO_ 2566834711 "Active diagnostic trouble codes
Added the message with a new SA in the db version2";
CM_ SG_ 2566834711 FailureModeIdentifier5 "The FMI defines the type of failure detected in the subsystem identified by an SPN.";
CM_ SG_ 2566834711 FailureModeIdentifier4 "The FMI defines the type of failure detected in the subsystem identified by an SPN.";
CM_ SG_ 2566834711 FailureModeIdentifier3 "The FMI defines the type of failure detected in the subsystem identified by an SPN.";
CM_ SG_ 2566834711 FailureModeIdentifier2 "The FMI defines the type of failure detected in the subsystem identified by an SPN.";
CM_ SG_ 2566834711 FailureModeIdentifier1 "The FMI defines the type of failure detected in the subsystem identified by an SPN.";
CM_ SG_ 2566834711 SPN5 "SPN #5 (Conversion Version 4)";
CM_ SG_ 2566834711 SPN4 "SPN #4 (Conversion Version 4)";
CM_ SG_ 2566834711 SPN3 "SPN #3 (Conversion Version 4)";
CM_ SG_ 2566834711 SPN2 "SPN #2 (Conversion Version 4)";
CM_ SG_ 2566834711 SPN1 "SPN #1 (Conversion Version 4)";
CM_ SG_ 2566834711 RedStopLampStatus "This lamp is uesed to relay trouble code information that is of a severe enought condition that it warrants stopping the vehicle.";
CM_ SG_ 2566834711 ProtectLampStatus "This lamp is used to relay trouble code informatio that is reporting a problem with a vehicle system that is most
probably not electronic subsystem related.";
CM_ SG_ 2566834711 AmberWarningLampStatus "This lamp is used to relay trouble code information that is reporting a problem with the vehicle system but the vehicle need
not be immediately stopped.";
CM_ SG_ 2566834711 MalfunctionIndicatorLampStatus "A lamp used to relay only emissions-related trouble code information.";
CM_ SG_ 2566834711 FlashRedStopLamp "This parameter provides the capability to flash the RSL (SPN 3039).";
CM_ SG_ 2566834711 FlashProtectLamp "This parameter provides the capability to flash the engine protect lamp (SPN 3041).";
CM_ SG_ 2566834711 FlashMalfuncIndicatorLamp "This parameter provides the capability to flash the MIL (SPN 3038).";
CM_ SG_ 2566834711 FlashAmberWarningLamp "This parameter provides the capability to flash the AWL (SPN 3040). ";
CM_ SG_ 2566834711 OccurenceCount1 "The 7 bit occurence count field contains the number of times a fault has gone from active to previously active.";
CM_ SG_ 2566834711 OccurenceCount5 "The 7 bit occurence count field contains the number of times a fault has gone from active to previously active.";
CM_ SG_ 2566834711 OccurenceCount4 "The 7 bit occurence count field contains the number of times a fault has gone from active to previously active.";
CM_ SG_ 2566834711 OccurenceCount3 "The 7 bit occurence count field contains the number of times a fault has gone from active to previously active.";
CM_ SG_ 2566834711 OccurenceCount2 "The 7 bit occurence count field contains the number of times a fault has gone from active to previously active.";
CM_ SG_ 2566834711 SPN5High "SPN #5 (Conversion Version 4)";
CM_ SG_ 2566834711 SPN4High "SPN #4 (Conversion Version 4)";
CM_ SG_ 2566834711 SPN3High "SPN #3 (Conversion Version 4)";
CM_ SG_ 2566834711 SPN2High "SPN #2 (Conversion Version 4)";
CM_ SG_ 2566834711 SPN1High "SPN #1 (Conversion Version 4)";
CM_ BO_ 2564816640 "Stop start broadcast
Added the message for a new DA(global) in the db version 2";
CM_ SG_ 2564816640 HoldSignal "Indicator to all nodes that the communication ports that have been acted upon by the 'Stop start broadcast'
PGN are remaining in the modified state.";
CM_ SG_ 2564816640 J1939Network3 "Identifies the action to be performed on the SAE J1939 Network #3.";
CM_ SG_ 2564816640 J1939Network2 "Identifies the action to be performed on the SAE J1939 Network #2.";
CM_ SG_ 2564816640 ISO9141 "Identifies the action to be performed on the ISO9141 communications port.";
CM_ SG_ 2564816640 SAE_J1850 "Identifies the action to be performed on the SAE J1850 communications port.";
CM_ SG_ 2564816640 ManufacturerSpecificPort "Identifies the action to be performed on 'Other, manufacturer specific port' communications port.";
CM_ SG_ 2564816640 CurrentDataLink "Identifies the action to be performed on the communications port that this parameter was received.";
CM_ SG_ 2564816640 SAE_J1587 "Identifies the action to be performed on the SAE J1587 communications port.";
CM_ SG_ 2564816640 SAE_J1922 "Identifies the action to be performed on the SAE J1922 communications port.";
CM_ SG_ 2564816640 J1939Network1 "Identifies the action to be performed on the SAE J1939 Network #1, Primary vehicle communications port.";
CM_ BO_ 2566844705 "Cruise Control/Vehicle Speed
Added the message with a new SA in the db version2";
CM_ SG_ 2566844705 EngIdleIncrementSwitch "Switch signal which indicates the position of the idle increment switch.";
CM_ SG_ 2566844705 EngIdleDecrementSwitch "Switch signal which indicates the position of the idle decrement switch.";
CM_ SG_ 2566844705 EngShutdownOverrideSwitch "Switch signal which indicates the position of the engine shutdown override switch.";
CM_ SG_ 2566844705 EngTestModeSwitch "Switch signal which indicates the position of the engine test mode switch.";
CM_ SG_ 2566844705 CruiseCtrlStates "This parameter is used to indicate the current state, or mode, of operation by the cruise control device.";
CM_ SG_ 2566844705 PTOState "This parameter is used to indicate the current state or mode of operation by the power takeoff (PTO) device.";
CM_ SG_ 2566844705 CruiseCtrlSetSpeed "Value of set (chosen) velocity of velocity control system.";
CM_ SG_ 2566844705 CruiseCtrlAccelerateSwitch "Switch signal of the cruise control activator which indicates that the activator is in the position “accelerate.";
CM_ SG_ 2566844705 CruiseCtrlResumeSwitch "Switch signal of the cruise control activator which indicates that the activator is in the position “resume.";
CM_ SG_ 2566844705 CruiseCtrlCoastSwitch "Switch signal of the cruise control activator which indicates that the activator is in the position “coast (decelerate).";
CM_ SG_ 2566844705 CruiseCtrlSetSwitch "Switch signal of the cruise control activator which indicates that the activator is in the position “set.";
CM_ SG_ 2566844705 ClutchSwitch "Switch signal which indicates that the clutch pedal is being pressed.";
CM_ SG_ 2566844705 BrakeSwitch "Switch signal which indicates that the driver operated brake foot pedal is being pressed.";
CM_ SG_ 2566844705 CruiseCtrlEnableSwitch "Switch signal which indicates that it is possible to manage the cruise control function.";
CM_ SG_ 2566844705 CruiseCtrlActive "Cruise control is switched on.";
CM_ SG_ 2566844705 WheelBasedVehicleSpeed "Speed of the vehicle as calculated from wheel or tailshaft speed.";
CM_ SG_ 2566844705 CruiseCtrlPauseSwitch "Switch signal which indicates the position of the Cruise Control Pause Switch used on Remote Cruise Control applications.";
CM_ SG_ 2566844705 ParkingBrakeSwitch "Switch signal which indicates when the parking brake is set.";
CM_ SG_ 2566844705 TwoSpeedAxleSwitch "Switch signal which indicates the current axle range.";
CM_ BO_ 2566845719 "Ambient Conditions
added the message for a new SA in the db ver2";
CM_ SG_ 2566845719 RoadSurfaceTemp "Indicated temperature of road surface over which vehicle is operating.";
CM_ SG_ 2566845719 EngAirInletTemp "Temperature of air entering vehicle air induction system.";
CM_ SG_ 2566845719 AmbientAirTemp "Temperature of air surrounding vehicle.";
CM_ SG_ 2566845719 CabInteriorTemp "Temperature of air inside the part of the vehicle that encloses the driver and vehicle operating controls.";
CM_ SG_ 2566845719 BarometricPress "Absolute air pressure of the atmosphere.";
CM_ BO_ 2565347072 "Acknowledgment Message
added the new message to accomdate the new destination address ";
CM_ SG_ 2565347072 ParameterGroupNumber "PGN which is requested by Request2 message";
CM_ SG_ 2565347072 GroupFunctionValue "Indicates the acknowledgement response.Indicates the acknowledgement response.Negative Acknowledgement Group Function valuePositive Acknowledgement Group Function value";
CM_ BO_ 2565480727 "Request
added the RQST message for a new SA and DA address in db ver2
";
CM_ SG_ 2565480727 ParameterGroupNumber "PGN which is requested by RQST
changed the spn from 2547 to 2540 in db vers2
";
CM_ BO_ 2565537785 "Request
added the RQST message for a new SA and DA address in db ver2
";
CM_ SG_ 2565537785 ParameterGroupNumber "PGN which is requested by RQST
changed the spn from 2547 to 2540 in db vers2
";
CM_ BO_ 2566864640 "The message has been newly added to accomodate the new sensors in the system.";
CM_ SG_ 2566864640 CoolantPresSensRawVoltage "Engine coolant pressure sensor raw voltage

";
CM_ SG_ 2566864640 CrankcasePresSensRawVoltage "
";
CM_ SG_ 2566864640 HumiditySensRawVoltage "Humidity sensor raw voltage

";
CM_ SG_ 2566864640 BoostPressure2SensRawVoltage "
Need to determine the spn 
newly added to dbver1
BoostPressure2SensRawVoltage	0	FF3F	521537

";
CM_ SG_ 2566864640 BoostAirTemp2SensRawVoltage "
Need to determine the spn
added the spn as a placeholder
BoostAirTemp2SensRawVoltage	0	FF3F	521536
";
CM_ SG_ 2566864640 EGRTemp2SensorPresSensRawVoltage "prop spn 
added to the db version1
The Spn would be determined.
EGRTemp2SensorPresSensRawVoltage	0	FF3F	521535
";
CM_ SG_ 2566864640 EGRTemp1SensorPresSensRawVoltage "prop spn 
added to the db version1
The Spn would be determined.
EGRTemp1SensorPresSensRawVoltage	0	FF3F	521534
";
CM_ SG_ 2566864640 MAFSensorRawVoltage "prop spn 
added to the db version1
The Spn would be determined.";
CM_ BO_ 2566750208 "Permanent DTCs that are present
Addded newly to the db version1";
CM_ SG_ 2566750208 FailureModeIdentifier5 "The FMI defines the type of failure detected in the subsystem identified by an SPN.";
CM_ SG_ 2566750208 FailureModeIdentifier4 "The FMI defines the type of failure detected in the subsystem identified by an SPN.";
CM_ SG_ 2566750208 FailureModeIdentifier3 "The FMI defines the type of failure detected in the subsystem identified by an SPN.";
CM_ SG_ 2566750208 FailureModeIdentifier2 "The FMI defines the type of failure detected in the subsystem identified by an SPN.";
CM_ SG_ 2566750208 FailureModeIdentifier1 "The FMI defines the type of failure detected in the subsystem identified by an SPN.";
CM_ SG_ 2566750208 FlashRedStopLamp "This parameter provides the capability to flash the RSL (SPN 3039).";
CM_ SG_ 2566750208 FlashProtectLamp "This parameter provides the capability to flash the engine protect lamp (SPN 3041).";
CM_ SG_ 2566750208 FlashMalfuncIndicatorLamp "This parameter provides the capability to flash the MIL (SPN 3038).";
CM_ SG_ 2566750208 FlashAmberWarningLamp "This parameter provides the capability to flash the AWL (SPN 3040). ";
CM_ SG_ 2566750208 OccurenceCount5 "The 7 bit occurence count field contains the number of times a fault has gone from active to previously active.";
CM_ SG_ 2566750208 OccurenceCount4 "The 7 bit occurence count field contains the number of times a fault has gone from active to previously active.";
CM_ SG_ 2566750208 OccurenceCount3 "The 7 bit occurence count field contains the number of times a fault has gone from active to previously active.";
CM_ SG_ 2566750208 OccurenceCount2 "The 7 bit occurence count field contains the number of times a fault has gone from active to previously active.";
CM_ SG_ 2566750208 SPN5High "SPN #5 (Conversion Version 4)";
CM_ SG_ 2566750208 SPN5 "SPN #5 (Conversion Version 4)";
CM_ SG_ 2566750208 SPN4High "SPN #4 (Conversion Version 4)";
CM_ SG_ 2566750208 SPN4 "SPN #4 (Conversion Version 4)";
CM_ SG_ 2566750208 SPN3High "SPN #3 (Conversion Version 4)";
CM_ SG_ 2566750208 SPN3 "SPN #3 (Conversion Version 4)";
CM_ SG_ 2566750208 SPN2High "SPN #2 (Conversion Version 4)";
CM_ SG_ 2566750208 SPN2 "SPN #2 (Conversion Version 4)";
CM_ SG_ 2566750208 SPN1High "SPN #1 (Conversion Version 4)";
CM_ SG_ 2566750208 SPN1 "SPN #1 (Conversion Version 4)";
CM_ SG_ 2566750208 RedStopLampStatus "This lamp is uesed to relay trouble code information that is of a severe enought condition that it warrants stopping the vehicle.";
CM_ SG_ 2566750208 ProtectLampStatus "This lamp is used to relay trouble code informatio that is reporting a problem with a vehicle system that is most
probably not electronic subsystem related.";
CM_ SG_ 2566750208 AmberWarningLampStatus "This lamp is used to relay trouble code information that is reporting a problem with the vehicle system but the vehicle need
not be immediately stopped.";
CM_ SG_ 2566750208 MalfunctionIndicatorLampStatus "A lamp used to relay only emissions-related trouble code information.";
CM_ SG_ 2566750208 OccurenceCount1 "The 7 bit occurence count field contains the number of times a fault has gone from active to previously active.";
CM_ BO_ 2566750720 "All pending DTCs.";
CM_ SG_ 2566750720 OccurenceCount5 "The 7 bit occurence count field contains the number of times a fault has gone from active to previously active.";
CM_ SG_ 2566750720 OccurenceCount4 "The 7 bit occurence count field contains the number of times a fault has gone from active to previously active.";
CM_ SG_ 2566750720 OccurenceCount3 "The 7 bit occurence count field contains the number of times a fault has gone from active to previously active.";
CM_ SG_ 2566750720 OccurenceCount2 "The 7 bit occurence count field contains the number of times a fault has gone from active to previously active.";
CM_ SG_ 2566750720 SPN5High "SPN #5 (Conversion Version 4)";
CM_ SG_ 2566750720 SPN5 "SPN #5 (Conversion Version 4)";
CM_ SG_ 2566750720 SPN4High "SPN #4 (Conversion Version 4)";
CM_ SG_ 2566750720 SPN4 "SPN #4 (Conversion Version 4)";
CM_ SG_ 2566750720 SPN3High "SPN #3 (Conversion Version 4)";
CM_ SG_ 2566750720 SPN3 "SPN #3 (Conversion Version 4)";
CM_ SG_ 2566750720 SPN2High "SPN #2 (Conversion Version 4)";
CM_ SG_ 2566750720 SPN2 "SPN #2 (Conversion Version 4)";
CM_ SG_ 2566750720 SPN1High "SPN #1 (Conversion Version 4)";
CM_ SG_ 2566750720 SPN1 "SPN #1 (Conversion Version 4)";
CM_ SG_ 2566750720 FailureModeIdentifier5 "The FMI defines the type of failure detected in the subsystem identified by an SPN.";
CM_ SG_ 2566750720 FailureModeIdentifier4 "The FMI defines the type of failure detected in the subsystem identified by an SPN.";
CM_ SG_ 2566750720 FailureModeIdentifier3 "The FMI defines the type of failure detected in the subsystem identified by an SPN.";
CM_ SG_ 2566750720 FailureModeIdentifier2 "The FMI defines the type of failure detected in the subsystem identified by an SPN.";
CM_ SG_ 2566750720 FailureModeIdentifier1 "The FMI defines the type of failure detected in the subsystem identified by an SPN.";
CM_ SG_ 2566750720 FlashRedStopLamp "This parameter provides the capability to flash the RSL (SPN 3039).";
CM_ SG_ 2566750720 FlashProtectLamp "This parameter provides the capability to flash the engine protect lamp (SPN 3041).";
CM_ SG_ 2566750720 FlashMalfuncIndicatorLamp "This parameter provides the capability to flash the MIL (SPN 3038).";
CM_ SG_ 2566750720 FlashAmberWarningLamp "This parameter provides the capability to flash the AWL (SPN 3040). ";
CM_ SG_ 2566750720 RedStopLampStatus "This lamp is uesed to relay trouble code information that is of a severe enought condition that it warrants stopping the vehicle.";
CM_ SG_ 2566750720 ProtectLampStatus "This lamp is used to relay trouble code informatio that is reporting a problem with a vehicle system that is most
probably not electronic subsystem related.";
CM_ SG_ 2566750720 AmberWarningLampStatus "This lamp is used to relay trouble code information that is reporting a problem with the vehicle system but the vehicle need
not be immediately stopped.";
CM_ SG_ 2566750720 MalfunctionIndicatorLampStatus "A lamp used to relay only emissions-related trouble code information.";
CM_ SG_ 2566750720 OccurenceCount1 "The 7 bit occurence count field contains the number of times a fault has gone from active to previously active.";
CM_ BO_ 2566886393 "

added the message to the db ver1
Removed the SPN: measured time up baseline  in db ver4
check cdrif for specs";
CM_ BO_ 2565734401 "Newly added to db ver1 
";
CM_ SG_ 2565734401 ArbitraryAddressCapable "Newly added the parameter to the db ver1";
CM_ SG_ 2565734401 IndustryGroup "Newly added the ver db 1";
CM_ SG_ 2565734401 VehicleSystemInstance "Added the spn to the db ver1";
CM_ SG_ 2565734401 VehicleSystem "Newly added to db ver1";
CM_ SG_ 2565734401 ECUInstance "newly added the spn to the db ver1";
CM_ SG_ 2565734401 ManufacturerCode "Newly added to the db";
CM_ SG_ 2565734401 IdentityNumber "Newly added to the db version 1";
CM_ BO_ 2565869056 "The purpose of this PGN is to group the aftrtrtmnt intake sensor data for bank 1.These values include the Nox %02 ,sdtatus of the sensros w.r.t the pwr being supplied and the heating element errors and stability.
New db ver1  changed the SA to db ver2.
";
CM_ SG_ 2565869056 Aftertreatment1IntSensHtrCtl "Aftertreatment 1 Intake Gas Sensor Heater Control";
CM_ SG_ 2565869056 Aftrtmnt1IntkWideRngPrcnt0Stable "Added newly to db ver1";
CM_ SG_ 2565869056 Aftreatment1IntakePercentO2 "Added newly to db ver1";
CM_ BO_ 2566770688 "Inlet/exhaust conditions 2 is a second PGN conveying this type of engine information.
Newly added to the db ver1";
CM_ SG_ 2566770688 EngineIntakeManifold1AbsPress "The absolute pressure measurement of the air intake manifold . If there are multiple air pressure sensors in the intake stream this is the last one in flow direction before entering the combustion chamber
Newly added to the db version1.";
CM_ BO_ 2560556800 "Identify the number of DTCs in each category. The categories are pending all pending MIL-on, previosuly MIL-on and permanent DTCs.
Added PGN to the db ver1

";
CM_ SG_ 2560556800 PermanentDTCs "Identifies the current number of permanent DTCs.
added to the db ver 1";
CM_ SG_ 2560556800 PreviosulyMILonDTCs "Identifies the current number of previously MIL-on DTCs";
CM_ SG_ 2560556800 MILonDTCs "Identifies the current number of MIL-on DTCs";
CM_ SG_ 2560556800 AllPendingDTCs "Identifies the current total number of pending DTCs including emission related ones.
added new message to the db ver1";
CM_ SG_ 2560556800 PendingDTCs "Identifies the current number of emission related pending DTCs(DM6)";
CM_ BO_ 2560950016 "Scaled Test Results 
Added PGN to the db ver1

";
CM_ SG_ 2560950016 SLOTIdentifier "The test is used to determine the multiplier and offset to be used to scale the test value,test limit max and test limit min so that the results are displaubable in engineering units
added to the db ver1";
CM_ SG_ 2560950016 TestLimitMinimum "The threshold which the test value must be above to pass the test.";
CM_ SG_ 2560950016 TestLimitMaximum "The threshold which the test value must be below to pass the test.";
CM_ SG_ 2560950016 TestValue "The test value collected during the test.";
CM_ BO_ 2566842110 "Newly added to the db per IF37
changed the SA to 0 db version2";
CM_ SG_ 2566842110 LocalHourOffset "newly added to the db1 ";
CM_ SG_ 2566842110 LocalMinuteOffset "newly added to the db1 ";
CM_ SG_ 2566842110 Year "Part of a parameter used to represent a calendar date.";
CM_ SG_ 2566842110 Month "Part of a parameter used to represent a calendar date.";
CM_ SG_ 2566842110 Day "Part of a parameter used to represent a calendar date.
added new to the db";
CM_ SG_ 2566842110 Hours "added to the db to 65254";
CM_ SG_ 2566842110 Minutes "minutes in the pgn 65254";
CM_ BO_ 2560687872 "The status of enginer operating in the NTE Control areas for given pollutants.
changed the SA to 0 in the db version2";
CM_ SG_ 2560687872 PMNTEDeficiencyAreaStatus "Eng Opt in the PM NTE Deficiency Area.";
CM_ SG_ 2560687872 ManufactPMNTECarveOutAreaStatus "Eng Opt within the manufacturer specific PM  NTE Carve out area. ";
CM_ SG_ 2560687872 PMNTECtrlAreaStatus "Eng Opt in the bounded region of trq and spd map where emissions must not exceed a specific emission cap for PM under NTE requirement.";
CM_ SG_ 2560687872 NOxNTEDeficiencyAreaStatus "Eng Opt in the Nox NTE Deficiency Area.";
CM_ SG_ 2560687872 ManufactNOxNTECarveOutAreaStatus "Eng Opt within the manufacturer specific NOx NTE Carve out area. ";
CM_ SG_ 2560687872 NOxNTECtrlAreaStatus "Eng Opt in the bounded region of trq and spd map where emissions must not exceed a specific emission cap for NOx under NTE requirement.";
CM_ BO_ 2566755328 "Engine Related Parameters 
EGR Valve Position
Newly added version1 db";
CM_ SG_ 2566755328 EGRVlvPosition "Newly added SPN to ver 1 db";
CM_ BO_ 2566743552 "Engine Temperature 4
Newly added : version1 db
included Engine Coolant temp2";
CM_ SG_ 2566743552 EngCoolantTemp2 "Second temperature of the liquid found in the engine cooling system.";
CM_ BO_ 2566822144 "Turbocharger 2 Comp. Inlet Pressure
added the message in version1 db
DM4 spn 1177 has been added

TCI3 PGN number has been coded incorrect in ver3
Changed to PGN 65177 in Db ver4";
CM_ SG_ 2566822144 EngTurbo2CompressorInletPress "Temperature of the air entering the compressor side of the turbocharger.
added to the db version 1 dm4 freeze frame parameter
";
CM_ SG_ 2566864384 OilTempSens2RawVoltage "
";
CM_ SG_ 2566864384 AmbTempSensorRawVoltage "corrected the spn from 0 to spn 8479 in ver1 db
IntakeAirTempSensorRawVoltage	8479	FF9B	521538
";
CM_ SG_ 2566864384 OilTempSensRawVoltage "corrected the spn from 0 to 8466 db version1
OilTempSensRawVoltage	8474	FF3E	521532
";
CM_ SG_ 2566864384 LambdaSensorVoltage_IntRes "Lambda sensor voltage across internal resistance

LambdaSensorVoltage_IntRes	8475	FF3E	521533
";
CM_ SG_ 2566864384 IntakeManifoldTempSensRawVoltage "corrected the spn from 0 to spn 8473 in ver1 db
IntakeManifoldTempSensRawVoltage	8473	FF3E	521531
";
CM_ SG_ 2566864384 CoolantTempSensRawVoltage "corrected the spn from 0 to spn 8471 in ver1 db
CoolantTempSensRawVoltage	8471	FF3E	521529
";
CM_ SG_ 2566864384 CoolantTempSens2RawVoltage "corrected the spn from 0 to spn 8472  in ver1 db
CoolantTempSens2RawVoltage	8472	FF3E	521530
";
CM_ SG_ 2566864384 BoostAirTempSensRawVoltage "corrected the spn from 0 to spn 8470  in ver1 db
BoostAirTempSensRawVoltage	8470	FF3E	521528
";
CM_ SG_ 2566864128 LambdaSensorVoltage_O2Signal "Lambda sensor O2 signal voltage
LambdaSensorVoltage_O2Signal	8469	FF3D	521527
";
CM_ SG_ 2566864128 ExhaustGasRecircValvePosRawVolt "ExhaustGasRecircValvePosRawVolt	8468	FF3D	521526
";
CM_ SG_ 2566864128 SupplyFuelPresSensRawVoltage "corrected the spn from 0 to 8466 db version1
SupplyFuelPresSensRawVoltage	8467	FF3D	521525
";
CM_ SG_ 2566864128 OilPresSensRawVoltage "corrected the spn from 0 to 8466 db version1
\OilPresSensRawVoltage	8466	FF3D	521524
";
CM_ SG_ 2566864128 FuelPressureSensRawVoltage "corrected the spn from 0 to spn 8465 in ver1 db
FuelPressureSensRawVoltage	8465	FF3D	521523
";
CM_ SG_ 2566864128 ExhaustGasBackPresSensRawVoltage "corrected the spn from 0 to spn 8464 in ver1 db
ExhaustGasBackPresSensRawVoltage	8464	FF3D	521522
";
CM_ SG_ 2566864128 BoostPressureSensRawVoltage "corrected the spn from 0 to spn 8463  in ver1 db
BoostPressureSensRawVoltage	8463	FF3D	521521
";
CM_ SG_ 2566864128 AtmosphericPresSensRawVoltage "prop spn 
added to the db version1
AtmosphericPresSensRawVoltage	8462	FF3D	521520
";
CM_ SG_ 2566862848 DesiredFanSpeed "added back the spn to the db (prop)
DesiredFanSpeed	7335	FEBD	522247
";
CM_ SG_ 2566862848 DesiredRelativeBoostPressure "Desired Boost Pressure (relative to ambient)
";
CM_ SG_ 2566862848 MainFuelInjectionPulseWidth "corrected the db ver1 spn from 0 to 8478
MainFuelInjectionPulseWidth	8478	FF38	522248
";
CM_ SG_ 2566862080 LambdaSensorMeasuredValue "LambdaSensorMeasuredValue	8444	FF35	521519
";
CM_ SG_ 2566862080 LambdaSensorTemperatureValue "LambdaSensorTemperatureValue	8442	FF35	521518
";
CM_ SG_ 2566888192 AccelPedalPosn2SensorVolts "Accelerator Pedal Position 2 Sensor Voltage

15-Aug-2008: Needs SPN
";
CM_ SG_ 2566888192 AirConditionerDemandStatus "changed the spn to 7267 db version1
AirConditionerDemandStatus	7267	FF9B	522244
";
CM_ SG_ 2566888192 IntakeAirTempSensorRawVoltage "corrected the spn from 0 to spn 8479 in ver1 db
IntakeAirTempSensorRawVoltage	8479	FF9B	521538
";
CM_ SG_ 2566888192 RPSADcounts "corrected the spn from 0 to 7008 db version1
RPSADcounts	7008	FF9B	521517
";
CM_ SG_ 2566888192 APSADcounts "changed the spn to 7007 db version1
APSADcounts	7007	FF9B	521516
";
CM_ SG_ 2566888192 RetarderInhibitEBSSwitchStatus "corrected the spn from 0 to 7062 db version1
RetarderInhibitEBSSwitchStatus	7062	FF9B	522242
";
CM_ SG_ 2566888192 ChangeOilLampStatus "corrected the spn from 0 to spn 7270 in ver1 db
ChangeOilLampStatus	7270	FF9B	522245
";
CM_ SG_ 2566888192 ElectronicFanControlStatus "ElectronicFanControlStatus	7272	FF9B	522246
";
CM_ SG_ 2566888192 EngineRetarderStatus "EngineRetarderStatus	7121	FF9B	522243
";
CM_ SG_ 2566887936 Comp_Brake_Status_2 "Compression brake actuator 2 status
";
CM_ SG_ 2566887936 Comp_Brake_Status_1 "Compression brake actuator 1 status
";
CM_ SG_ 2566887936 FanControlDutyCycle "continue with the prop message per the requirement db vers1
FanControlDutyCycle	7024	FF9A	522241
";
BA_DEF_ SG_  "Status" STRING ;
BA_DEF_ SG_  "Variable" STRING ;
BA_DEF_ SG_  "SigType" STRING ;
BA_DEF_ SG_  "SPN" INT 0 524287;
BA_DEF_ SG_  "DDI" INT 0 65535;
BA_DEF_ SG_  "SAEDocument" STRING ;
BA_DEF_ BO_  "GenMsgRequestable" INT 0 1;
BA_DEF_ BO_  "GenMsgSendType" ENUM  "cyclic","reserved","cyclicIfActive","reserved","reserved","reserved","reserved","On Request","noMsgSendType";
BA_DEF_ BO_  "VFrameFormat" ENUM  "StandardCAN","ExtendedCAN","reserved","J1939PG";
BA_DEF_ BO_  "SingleFrame" INT 0 1;
BA_DEF_ BO_  "GenMsgCycleTime" INT 0 3600000;
BA_DEF_ BO_  "SAE_Document" STRING ;
BA_DEF_DEF_  "Status" "";
BA_DEF_DEF_  "Variable" "";
BA_DEF_DEF_  "SigType" "";
BA_DEF_DEF_  "SPN" 0;
BA_DEF_DEF_  "DDI" 0;
BA_DEF_DEF_  "SAEDocument" "";
BA_DEF_DEF_  "GenMsgRequestable" 1;
BA_DEF_DEF_  "GenMsgSendType" "noMsgSendType";
BA_DEF_DEF_  "VFrameFormat" "J1939PG";
BA_DEF_DEF_  "SingleFrame" 1;
BA_DEF_DEF_  "GenMsgCycleTime" 0;
BA_DEF_DEF_  "SAE_Document" "";
BA_ "SAE_Document" BO_ 2566834691 "J1939-73";
BA_ "SAE_Document" BO_ 2566834711 "J1939-73";
BA_ "SAE_Document" BO_ 2564816640 "J1939-73";
BA_ "GenMsgSendType" BO_ 2566844705 0;
BA_ "GenMsgCycleTime" BO_ 2566844705 100;
BA_ "SAE_Document" BO_ 2566844705 "J1939-71";
BA_ "GenMsgSendType" BO_ 2566845719 0;
BA_ "GenMsgCycleTime" BO_ 2566845719 1000;
BA_ "SAE_Document" BO_ 2566845719 "J1939-71";
BA_ "SAE_Document" BO_ 2565347072 "J1939-21";
BA_ "SAE_Document" BO_ 2565480727 "J1939-21";
BA_ "SAE_Document" BO_ 2565537785 "J1939-21";
BA_ "GenMsgSendType" BO_ 2566864640 7;
BA_ "SAE_Document" BO_ 2566750208 "J1939-73";
BA_ "SAE_Document" BO_ 2566750720 "J1939-73";
BA_ "SAE_Document" BO_ 2566886393 "Prop";
BA_ "SAE_Document" BO_ 2565734401 "J1939_81";
BA_ "GenMsgSendType" BO_ 2565869056 0;
BA_ "GenMsgCycleTime" BO_ 2565869056 50;
BA_ "SAE_Document" BO_ 2565869056 "J1939_71";
BA_ "GenMsgSendType" BO_ 2566770688 0;
BA_ "GenMsgCycleTime" BO_ 2566770688 500;
BA_ "SAE_Document" BO_ 2566770688 "J1939-71";
BA_ "SAE_Document" BO_ 2560556800 "J1939-73";
BA_ "SAE_Document" BO_ 2560950016 "J1939-73";
BA_ "GenMsgSendType" BO_ 2566842110 7;
BA_ "SAE_Document" BO_ 2566842110 "J1939-71";
BA_ "SAE_Document" BO_ 2560687872 "J1939-73";
BA_ "GenMsgSendType" BO_ 2566755328 0;
BA_ "GenMsgCycleTime" BO_ 2566755328 100;
BA_ "SAE_Document" BO_ 2566755328 "J1939-71";
BA_ "GenMsgSendType" BO_ 2566743552 0;
BA_ "GenMsgCycleTime" BO_ 2566743552 1000;
BA_ "SAE_Document" BO_ 2566743552 "J1939-71";
BA_ "GenMsgSendType" BO_ 2566822144 0;
BA_ "GenMsgCycleTime" BO_ 2566822144 1000;
BA_ "GenMsgSendType" BO_ 2566864384 7;
BA_ "GenMsgSendType" BO_ 2566864128 7;
BA_ "GenMsgCycleTime" BO_ 2566862848 1000;
BA_ "GenMsgSendType" BO_ 2566862848 0;
BA_ "GenMsgCycleTime" BO_ 2566862080 100;
BA_ "GenMsgSendType" BO_ 2566862080 0;
BA_ "GenMsgCycleTime" BO_ 2566888192 500;
BA_ "GenMsgSendType" BO_ 2566888192 0;
BA_ "GenMsgSendType" BO_ 2566887936 0;
BA_ "GenMsgCycleTime" BO_ 2566887936 1000;
BA_ "GenMsgSendType" BO_ 2566888448 7;
BA_ "SAEDocument" SG_ 2566834691 FailureModeIdentifier5 "J1939-73";
BA_ "Variable" SG_ 2566834691 FailureModeIdentifier5 "N/A";
BA_ "Status" SG_ 2566834691 FailureModeIdentifier5 "Ok";
BA_ "SPN" SG_ 2566834691 FailureModeIdentifier5 1215;
BA_ "SAEDocument" SG_ 2566834691 FailureModeIdentifier4 "J1939-73";
BA_ "Variable" SG_ 2566834691 FailureModeIdentifier4 "N/A";
BA_ "Status" SG_ 2566834691 FailureModeIdentifier4 "Ok";
BA_ "SPN" SG_ 2566834691 FailureModeIdentifier4 1215;
BA_ "SAEDocument" SG_ 2566834691 FailureModeIdentifier3 "J1939-73";
BA_ "Variable" SG_ 2566834691 FailureModeIdentifier3 "N/A";
BA_ "Status" SG_ 2566834691 FailureModeIdentifier3 "Ok";
BA_ "SPN" SG_ 2566834691 FailureModeIdentifier3 1215;
BA_ "Status" SG_ 2566834691 FailureModeIdentifier2 "Ok";
BA_ "SAEDocument" SG_ 2566834691 FailureModeIdentifier2 "J1939-73";
BA_ "Variable" SG_ 2566834691 FailureModeIdentifier2 "N/A";
BA_ "SPN" SG_ 2566834691 FailureModeIdentifier2 1215;
BA_ "SPN" SG_ 2566834691 FailureModeIdentifier1 1215;
BA_ "SAEDocument" SG_ 2566834691 FailureModeIdentifier1 "J1939-73";
BA_ "Variable" SG_ 2566834691 FailureModeIdentifier1 "N/A";
BA_ "Status" SG_ 2566834691 FailureModeIdentifier1 "Ok";
BA_ "SAEDocument" SG_ 2566834691 SPN5 "J1939-73";
BA_ "Variable" SG_ 2566834691 SPN5 "N/A";
BA_ "Status" SG_ 2566834691 SPN5 "Ok";
BA_ "SPN" SG_ 2566834691 SPN5 1214;
BA_ "SAEDocument" SG_ 2566834691 SPN4 "J1939-73";
BA_ "Variable" SG_ 2566834691 SPN4 "N/A";
BA_ "Status" SG_ 2566834691 SPN4 "Ok";
BA_ "SPN" SG_ 2566834691 SPN4 1214;
BA_ "SAEDocument" SG_ 2566834691 SPN3 "J1939-73";
BA_ "Variable" SG_ 2566834691 SPN3 "N/A";
BA_ "Status" SG_ 2566834691 SPN3 "Ok";
BA_ "SPN" SG_ 2566834691 SPN3 1214;
BA_ "SAEDocument" SG_ 2566834691 SPN2 "J1939-73";
BA_ "Variable" SG_ 2566834691 SPN2 "N/A";
BA_ "Status" SG_ 2566834691 SPN2 "Ok";
BA_ "SPN" SG_ 2566834691 SPN2 1214;
BA_ "SPN" SG_ 2566834691 SPN1 1214;
BA_ "SAEDocument" SG_ 2566834691 SPN1 "J1939-73";
BA_ "Variable" SG_ 2566834691 SPN1 "N/A";
BA_ "Status" SG_ 2566834691 SPN1 "Ok";
BA_ "SigType" SG_ 2566834691 RedStopLampStatus "DISCRETE";
BA_ "SPN" SG_ 2566834691 RedStopLampStatus 623;
BA_ "SAEDocument" SG_ 2566834691 RedStopLampStatus "J1939-73";
BA_ "Variable" SG_ 2566834691 RedStopLampStatus "N/A";
BA_ "Status" SG_ 2566834691 RedStopLampStatus "Ok";
BA_ "SigType" SG_ 2566834691 ProtectLampStatus "DISCRETE";
BA_ "SPN" SG_ 2566834691 ProtectLampStatus 987;
BA_ "SAEDocument" SG_ 2566834691 ProtectLampStatus "J1939-73";
BA_ "Variable" SG_ 2566834691 ProtectLampStatus "N/A";
BA_ "Status" SG_ 2566834691 ProtectLampStatus "Ok";
BA_ "SigType" SG_ 2566834691 AmberWarningLampStatus "DISCRETE";
BA_ "SPN" SG_ 2566834691 AmberWarningLampStatus 624;
BA_ "SAEDocument" SG_ 2566834691 AmberWarningLampStatus "J1939-73";
BA_ "Variable" SG_ 2566834691 AmberWarningLampStatus "N/A";
BA_ "Status" SG_ 2566834691 AmberWarningLampStatus "Ok";
BA_ "SigType" SG_ 2566834691 MalfunctionIndicatorLampStatus "DISCRETE";
BA_ "SPN" SG_ 2566834691 MalfunctionIndicatorLampStatus 1213;
BA_ "SAEDocument" SG_ 2566834691 MalfunctionIndicatorLampStatus "J1939-73";
BA_ "Variable" SG_ 2566834691 MalfunctionIndicatorLampStatus "N/A";
BA_ "Status" SG_ 2566834691 MalfunctionIndicatorLampStatus "Ok";
BA_ "SPN" SG_ 2566834691 FlashRedStopLamp 3039;
BA_ "SAEDocument" SG_ 2566834691 FlashRedStopLamp "J1939-73";
BA_ "Variable" SG_ 2566834691 FlashRedStopLamp "N/A";
BA_ "Status" SG_ 2566834691 FlashRedStopLamp "Ok";
BA_ "SPN" SG_ 2566834691 FlashProtectLamp 3041;
BA_ "SAEDocument" SG_ 2566834691 FlashProtectLamp "J1939-73";
BA_ "Variable" SG_ 2566834691 FlashProtectLamp "N/A";
BA_ "Status" SG_ 2566834691 FlashProtectLamp "Ok";
BA_ "SigType" SG_ 2566834691 FlashMalfuncIndicatorLamp "DISCRETE";
BA_ "SPN" SG_ 2566834691 FlashMalfuncIndicatorLamp 3038;
BA_ "SAEDocument" SG_ 2566834691 FlashMalfuncIndicatorLamp "J1939-73";
BA_ "Variable" SG_ 2566834691 FlashMalfuncIndicatorLamp "N/A";
BA_ "Status" SG_ 2566834691 FlashMalfuncIndicatorLamp "Ok";
BA_ "SPN" SG_ 2566834691 FlashAmberWarningLamp 3040;
BA_ "SAEDocument" SG_ 2566834691 FlashAmberWarningLamp "J1939-73";
BA_ "Variable" SG_ 2566834691 FlashAmberWarningLamp "N/A";
BA_ "Status" SG_ 2566834691 FlashAmberWarningLamp "Ok";
BA_ "SigType" SG_ 2566834691 OccurenceCount1 "RANGE";
BA_ "SPN" SG_ 2566834691 OccurenceCount1 1216;
BA_ "SAEDocument" SG_ 2566834691 OccurenceCount1 "J1939-73";
BA_ "Variable" SG_ 2566834691 OccurenceCount1 "N/A";
BA_ "Status" SG_ 2566834691 OccurenceCount1 "Ok";
BA_ "SPN" SG_ 2566834691 SPNConversionMethod1 1706;
BA_ "SAEDocument" SG_ 2566834691 SPNConversionMethod1 "J1939-73";
BA_ "Variable" SG_ 2566834691 SPNConversionMethod1 "N/A";
BA_ "Status" SG_ 2566834691 SPNConversionMethod1 "Ok";
BA_ "SAEDocument" SG_ 2566834691 SPNConversionMethod5 "J1939-73";
BA_ "Variable" SG_ 2566834691 SPNConversionMethod5 "N/A";
BA_ "Status" SG_ 2566834691 SPNConversionMethod5 "Ok";
BA_ "SPN" SG_ 2566834691 SPNConversionMethod5 1706;
BA_ "SAEDocument" SG_ 2566834691 SPNConversionMethod4 "J1939-73";
BA_ "Variable" SG_ 2566834691 SPNConversionMethod4 "N/A";
BA_ "Status" SG_ 2566834691 SPNConversionMethod4 "Ok";
BA_ "SPN" SG_ 2566834691 SPNConversionMethod4 1706;
BA_ "SAEDocument" SG_ 2566834691 SPNConversionMethod3 "J1939-73";
BA_ "Variable" SG_ 2566834691 SPNConversionMethod3 "N/A";
BA_ "Status" SG_ 2566834691 SPNConversionMethod3 "Ok";
BA_ "SPN" SG_ 2566834691 SPNConversionMethod3 1706;
BA_ "SAEDocument" SG_ 2566834691 SPNConversionMethod2 "J1939-73";
BA_ "Variable" SG_ 2566834691 SPNConversionMethod2 "N/A";
BA_ "Status" SG_ 2566834691 SPNConversionMethod2 "Ok";
BA_ "SPN" SG_ 2566834691 SPNConversionMethod2 1706;
BA_ "SigType" SG_ 2566834691 OccurenceCount5 "RANGE";
BA_ "SAEDocument" SG_ 2566834691 OccurenceCount5 "J1939-73";
BA_ "Variable" SG_ 2566834691 OccurenceCount5 "N/A";
BA_ "Status" SG_ 2566834691 OccurenceCount5 "Ok";
BA_ "SPN" SG_ 2566834691 OccurenceCount5 1216;
BA_ "SigType" SG_ 2566834691 OccurenceCount4 "RANGE";
BA_ "SAEDocument" SG_ 2566834691 OccurenceCount4 "J1939-73";
BA_ "Variable" SG_ 2566834691 OccurenceCount4 "N/A";
BA_ "Status" SG_ 2566834691 OccurenceCount4 "Ok";
BA_ "SPN" SG_ 2566834691 OccurenceCount4 1216;
BA_ "SigType" SG_ 2566834691 OccurenceCount3 "RANGE";
BA_ "SAEDocument" SG_ 2566834691 OccurenceCount3 "J1939-73";
BA_ "Variable" SG_ 2566834691 OccurenceCount3 "N/A";
BA_ "Status" SG_ 2566834691 OccurenceCount3 "Ok";
BA_ "SPN" SG_ 2566834691 OccurenceCount3 1216;
BA_ "SigType" SG_ 2566834691 OccurenceCount2 "RANGE";
BA_ "SAEDocument" SG_ 2566834691 OccurenceCount2 "J1939-73";
BA_ "Variable" SG_ 2566834691 OccurenceCount2 "N/A";
BA_ "Status" SG_ 2566834691 OccurenceCount2 "Ok";
BA_ "SPN" SG_ 2566834691 OccurenceCount2 1216;
BA_ "SAEDocument" SG_ 2566834691 SPN5High "J1939-73";
BA_ "Variable" SG_ 2566834691 SPN5High "N/A";
BA_ "Status" SG_ 2566834691 SPN5High "Ok";
BA_ "SPN" SG_ 2566834691 SPN5High 1214;
BA_ "SAEDocument" SG_ 2566834691 SPN4High "J1939-73";
BA_ "Variable" SG_ 2566834691 SPN4High "N/A";
BA_ "Status" SG_ 2566834691 SPN4High "Ok";
BA_ "SPN" SG_ 2566834691 SPN4High 1214;
BA_ "SAEDocument" SG_ 2566834691 SPN3High "J1939-73";
BA_ "Variable" SG_ 2566834691 SPN3High "N/A";
BA_ "Status" SG_ 2566834691 SPN3High "Ok";
BA_ "SPN" SG_ 2566834691 SPN3High 1214;
BA_ "SAEDocument" SG_ 2566834691 SPN2High "J1939-73";
BA_ "Variable" SG_ 2566834691 SPN2High "N/A";
BA_ "Status" SG_ 2566834691 SPN2High "Ok";
BA_ "SPN" SG_ 2566834691 SPN2High 1214;
BA_ "SPN" SG_ 2566834691 SPN1High 1214;
BA_ "SAEDocument" SG_ 2566834691 SPN1High "J1939-73";
BA_ "Variable" SG_ 2566834691 SPN1High "N/A";
BA_ "Status" SG_ 2566834691 SPN1High "Ok";
BA_ "SAEDocument" SG_ 2566834711 FailureModeIdentifier5 "J1939-73";
BA_ "Variable" SG_ 2566834711 FailureModeIdentifier5 "N/A";
BA_ "Status" SG_ 2566834711 FailureModeIdentifier5 "Ok";
BA_ "SPN" SG_ 2566834711 FailureModeIdentifier5 1215;
BA_ "SAEDocument" SG_ 2566834711 FailureModeIdentifier4 "J1939-73";
BA_ "Variable" SG_ 2566834711 FailureModeIdentifier4 "N/A";
BA_ "Status" SG_ 2566834711 FailureModeIdentifier4 "Ok";
BA_ "SPN" SG_ 2566834711 FailureModeIdentifier4 1215;
BA_ "SAEDocument" SG_ 2566834711 FailureModeIdentifier3 "J1939-73";
BA_ "Variable" SG_ 2566834711 FailureModeIdentifier3 "N/A";
BA_ "Status" SG_ 2566834711 FailureModeIdentifier3 "Ok";
BA_ "SPN" SG_ 2566834711 FailureModeIdentifier3 1215;
BA_ "Status" SG_ 2566834711 FailureModeIdentifier2 "Ok";
BA_ "SAEDocument" SG_ 2566834711 FailureModeIdentifier2 "J1939-73";
BA_ "Variable" SG_ 2566834711 FailureModeIdentifier2 "N/A";
BA_ "SPN" SG_ 2566834711 FailureModeIdentifier2 1215;
BA_ "SPN" SG_ 2566834711 FailureModeIdentifier1 1215;
BA_ "SAEDocument" SG_ 2566834711 FailureModeIdentifier1 "J1939-73";
BA_ "Variable" SG_ 2566834711 FailureModeIdentifier1 "N/A";
BA_ "Status" SG_ 2566834711 FailureModeIdentifier1 "Ok";
BA_ "SAEDocument" SG_ 2566834711 SPN5 "J1939-73";
BA_ "Variable" SG_ 2566834711 SPN5 "N/A";
BA_ "Status" SG_ 2566834711 SPN5 "Ok";
BA_ "SPN" SG_ 2566834711 SPN5 1214;
BA_ "SAEDocument" SG_ 2566834711 SPN4 "J1939-73";
BA_ "Variable" SG_ 2566834711 SPN4 "N/A";
BA_ "Status" SG_ 2566834711 SPN4 "Ok";
BA_ "SPN" SG_ 2566834711 SPN4 1214;
BA_ "SAEDocument" SG_ 2566834711 SPN3 "J1939-73";
BA_ "Variable" SG_ 2566834711 SPN3 "N/A";
BA_ "Status" SG_ 2566834711 SPN3 "Ok";
BA_ "SPN" SG_ 2566834711 SPN3 1214;
BA_ "SAEDocument" SG_ 2566834711 SPN2 "J1939-73";
BA_ "Variable" SG_ 2566834711 SPN2 "N/A";
BA_ "Status" SG_ 2566834711 SPN2 "Ok";
BA_ "SPN" SG_ 2566834711 SPN2 1214;
BA_ "SPN" SG_ 2566834711 SPN1 1214;
BA_ "SAEDocument" SG_ 2566834711 SPN1 "J1939-73";
BA_ "Variable" SG_ 2566834711 SPN1 "N/A";
BA_ "Status" SG_ 2566834711 SPN1 "Ok";
BA_ "SigType" SG_ 2566834711 RedStopLampStatus "DISCRETE";
BA_ "SPN" SG_ 2566834711 RedStopLampStatus 623;
BA_ "SAEDocument" SG_ 2566834711 RedStopLampStatus "J1939-73";
BA_ "Variable" SG_ 2566834711 RedStopLampStatus "N/A";
BA_ "Status" SG_ 2566834711 RedStopLampStatus "Ok";
BA_ "SigType" SG_ 2566834711 ProtectLampStatus "DISCRETE";
BA_ "SPN" SG_ 2566834711 ProtectLampStatus 987;
BA_ "SAEDocument" SG_ 2566834711 ProtectLampStatus "J1939-73";
BA_ "Variable" SG_ 2566834711 ProtectLampStatus "N/A";
BA_ "Status" SG_ 2566834711 ProtectLampStatus "Ok";
BA_ "SigType" SG_ 2566834711 AmberWarningLampStatus "DISCRETE";
BA_ "SPN" SG_ 2566834711 AmberWarningLampStatus 624;
BA_ "SAEDocument" SG_ 2566834711 AmberWarningLampStatus "J1939-73";
BA_ "Variable" SG_ 2566834711 AmberWarningLampStatus "N/A";
BA_ "Status" SG_ 2566834711 AmberWarningLampStatus "Ok";
BA_ "SigType" SG_ 2566834711 MalfunctionIndicatorLampStatus "DISCRETE";
BA_ "SPN" SG_ 2566834711 MalfunctionIndicatorLampStatus 1213;
BA_ "SAEDocument" SG_ 2566834711 MalfunctionIndicatorLampStatus "J1939-73";
BA_ "Variable" SG_ 2566834711 MalfunctionIndicatorLampStatus "N/A";
BA_ "Status" SG_ 2566834711 MalfunctionIndicatorLampStatus "Ok";
BA_ "SPN" SG_ 2566834711 FlashRedStopLamp 3039;
BA_ "SAEDocument" SG_ 2566834711 FlashRedStopLamp "J1939-73";
BA_ "Variable" SG_ 2566834711 FlashRedStopLamp "N/A";
BA_ "Status" SG_ 2566834711 FlashRedStopLamp "Ok";
BA_ "SPN" SG_ 2566834711 FlashProtectLamp 3041;
BA_ "SAEDocument" SG_ 2566834711 FlashProtectLamp "J1939-73";
BA_ "Variable" SG_ 2566834711 FlashProtectLamp "N/A";
BA_ "Status" SG_ 2566834711 FlashProtectLamp "Ok";
BA_ "SigType" SG_ 2566834711 FlashMalfuncIndicatorLamp "DISCRETE";
BA_ "SPN" SG_ 2566834711 FlashMalfuncIndicatorLamp 3038;
BA_ "SAEDocument" SG_ 2566834711 FlashMalfuncIndicatorLamp "J1939-73";
BA_ "Variable" SG_ 2566834711 FlashMalfuncIndicatorLamp "N/A";
BA_ "Status" SG_ 2566834711 FlashMalfuncIndicatorLamp "Ok";
BA_ "SPN" SG_ 2566834711 FlashAmberWarningLamp 3040;
BA_ "SAEDocument" SG_ 2566834711 FlashAmberWarningLamp "J1939-73";
BA_ "Variable" SG_ 2566834711 FlashAmberWarningLamp "N/A";
BA_ "Status" SG_ 2566834711 FlashAmberWarningLamp "Ok";
BA_ "SigType" SG_ 2566834711 OccurenceCount1 "RANGE";
BA_ "SPN" SG_ 2566834711 OccurenceCount1 1216;
BA_ "SAEDocument" SG_ 2566834711 OccurenceCount1 "J1939-73";
BA_ "Variable" SG_ 2566834711 OccurenceCount1 "N/A";
BA_ "Status" SG_ 2566834711 OccurenceCount1 "Ok";
BA_ "SPN" SG_ 2566834711 SPNConversionMethod1 1706;
BA_ "SAEDocument" SG_ 2566834711 SPNConversionMethod1 "J1939-73";
BA_ "Variable" SG_ 2566834711 SPNConversionMethod1 "N/A";
BA_ "Status" SG_ 2566834711 SPNConversionMethod1 "Ok";
BA_ "SAEDocument" SG_ 2566834711 SPNConversionMethod5 "J1939-73";
BA_ "Variable" SG_ 2566834711 SPNConversionMethod5 "N/A";
BA_ "Status" SG_ 2566834711 SPNConversionMethod5 "Ok";
BA_ "SPN" SG_ 2566834711 SPNConversionMethod5 1706;
BA_ "SAEDocument" SG_ 2566834711 SPNConversionMethod4 "J1939-73";
BA_ "Variable" SG_ 2566834711 SPNConversionMethod4 "N/A";
BA_ "Status" SG_ 2566834711 SPNConversionMethod4 "Ok";
BA_ "SPN" SG_ 2566834711 SPNConversionMethod4 1706;
BA_ "SAEDocument" SG_ 2566834711 SPNConversionMethod3 "J1939-73";
BA_ "Variable" SG_ 2566834711 SPNConversionMethod3 "N/A";
BA_ "Status" SG_ 2566834711 SPNConversionMethod3 "Ok";
BA_ "SPN" SG_ 2566834711 SPNConversionMethod3 1706;
BA_ "SAEDocument" SG_ 2566834711 SPNConversionMethod2 "J1939-73";
BA_ "Variable" SG_ 2566834711 SPNConversionMethod2 "N/A";
BA_ "Status" SG_ 2566834711 SPNConversionMethod2 "Ok";
BA_ "SPN" SG_ 2566834711 SPNConversionMethod2 1706;
BA_ "SigType" SG_ 2566834711 OccurenceCount5 "RANGE";
BA_ "SAEDocument" SG_ 2566834711 OccurenceCount5 "J1939-73";
BA_ "Variable" SG_ 2566834711 OccurenceCount5 "N/A";
BA_ "Status" SG_ 2566834711 OccurenceCount5 "Ok";
BA_ "SPN" SG_ 2566834711 OccurenceCount5 1216;
BA_ "SigType" SG_ 2566834711 OccurenceCount4 "RANGE";
BA_ "SAEDocument" SG_ 2566834711 OccurenceCount4 "J1939-73";
BA_ "Variable" SG_ 2566834711 OccurenceCount4 "N/A";
BA_ "Status" SG_ 2566834711 OccurenceCount4 "Ok";
BA_ "SPN" SG_ 2566834711 OccurenceCount4 1216;
BA_ "SigType" SG_ 2566834711 OccurenceCount3 "RANGE";
BA_ "SAEDocument" SG_ 2566834711 OccurenceCount3 "J1939-73";
BA_ "Variable" SG_ 2566834711 OccurenceCount3 "N/A";
BA_ "Status" SG_ 2566834711 OccurenceCount3 "Ok";
BA_ "SPN" SG_ 2566834711 OccurenceCount3 1216;
BA_ "SigType" SG_ 2566834711 OccurenceCount2 "RANGE";
BA_ "SAEDocument" SG_ 2566834711 OccurenceCount2 "J1939-73";
BA_ "Variable" SG_ 2566834711 OccurenceCount2 "N/A";
BA_ "Status" SG_ 2566834711 OccurenceCount2 "Ok";
BA_ "SPN" SG_ 2566834711 OccurenceCount2 1216;
BA_ "SAEDocument" SG_ 2566834711 SPN5High "J1939-73";
BA_ "Variable" SG_ 2566834711 SPN5High "N/A";
BA_ "Status" SG_ 2566834711 SPN5High "Ok";
BA_ "SPN" SG_ 2566834711 SPN5High 1214;
BA_ "SAEDocument" SG_ 2566834711 SPN4High "J1939-73";
BA_ "Variable" SG_ 2566834711 SPN4High "N/A";
BA_ "Status" SG_ 2566834711 SPN4High "Ok";
BA_ "SPN" SG_ 2566834711 SPN4High 1214;
BA_ "SAEDocument" SG_ 2566834711 SPN3High "J1939-73";
BA_ "Variable" SG_ 2566834711 SPN3High "N/A";
BA_ "Status" SG_ 2566834711 SPN3High "Ok";
BA_ "SPN" SG_ 2566834711 SPN3High 1214;
BA_ "SAEDocument" SG_ 2566834711 SPN2High "J1939-73";
BA_ "Variable" SG_ 2566834711 SPN2High "N/A";
BA_ "Status" SG_ 2566834711 SPN2High "Ok";
BA_ "SPN" SG_ 2566834711 SPN2High 1214;
BA_ "SPN" SG_ 2566834711 SPN1High 1214;
BA_ "SAEDocument" SG_ 2566834711 SPN1High "J1939-73";
BA_ "Variable" SG_ 2566834711 SPN1High "N/A";
BA_ "Status" SG_ 2566834711 SPN1High "Ok";
BA_ "Status" SG_ 2564816640 HoldSignal "2.1.0";
BA_ "SigType" SG_ 2564816640 HoldSignal "DISCRETE";
BA_ "SPN" SG_ 2564816640 HoldSignal 1236;
BA_ "SAEDocument" SG_ 2564816640 HoldSignal "J1939-73";
BA_ "Variable" SG_ 2564816640 HoldSignal "N/A";
BA_ "Status" SG_ 2564816640 J1939Network3 "2.1.0";
BA_ "SigType" SG_ 2564816640 J1939Network3 "DISCRETE";
BA_ "SPN" SG_ 2564816640 J1939Network3 1235;
BA_ "SAEDocument" SG_ 2564816640 J1939Network3 "J1939-73";
BA_ "Variable" SG_ 2564816640 J1939Network3 "N/A";
BA_ "Status" SG_ 2564816640 J1939Network2 "2.1.0";
BA_ "SigType" SG_ 2564816640 J1939Network2 "DISCRETE";
BA_ "SPN" SG_ 2564816640 J1939Network2 1231;
BA_ "SAEDocument" SG_ 2564816640 J1939Network2 "J1939-73";
BA_ "Variable" SG_ 2564816640 J1939Network2 "N/A";
BA_ "Status" SG_ 2564816640 ISO9141 "2.1.0";
BA_ "SigType" SG_ 2564816640 ISO9141 "DISCRETE";
BA_ "SPN" SG_ 2564816640 ISO9141 1232;
BA_ "SAEDocument" SG_ 2564816640 ISO9141 "J1939-73";
BA_ "Variable" SG_ 2564816640 ISO9141 "N/A";
BA_ "Status" SG_ 2564816640 SAE_J1850 "2.1.0";
BA_ "SigType" SG_ 2564816640 SAE_J1850 "DISCRETE";
BA_ "SPN" SG_ 2564816640 SAE_J1850 1233;
BA_ "SAEDocument" SG_ 2564816640 SAE_J1850 "J1939-73";
BA_ "Variable" SG_ 2564816640 SAE_J1850 "N/A";
BA_ "Status" SG_ 2564816640 ManufacturerSpecificPort "2.1.0";
BA_ "SigType" SG_ 2564816640 ManufacturerSpecificPort "DISCRETE";
BA_ "SPN" SG_ 2564816640 ManufacturerSpecificPort 1234;
BA_ "SAEDocument" SG_ 2564816640 ManufacturerSpecificPort "J1939-73";
BA_ "Variable" SG_ 2564816640 ManufacturerSpecificPort "N/A";
BA_ "Status" SG_ 2564816640 CurrentDataLink "2.1.0";
BA_ "SigType" SG_ 2564816640 CurrentDataLink "DISCRETE";
BA_ "SPN" SG_ 2564816640 CurrentDataLink 1230;
BA_ "SAEDocument" SG_ 2564816640 CurrentDataLink "J1939-73";
BA_ "Variable" SG_ 2564816640 CurrentDataLink "N/A";
BA_ "Status" SG_ 2564816640 SAE_J1587 "2.1.0";
BA_ "SigType" SG_ 2564816640 SAE_J1587 "DISCRETE";
BA_ "SPN" SG_ 2564816640 SAE_J1587 608;
BA_ "SAEDocument" SG_ 2564816640 SAE_J1587 "J1939-73";
BA_ "Variable" SG_ 2564816640 SAE_J1587 "N/A";
BA_ "Status" SG_ 2564816640 SAE_J1922 "2.1.0";
BA_ "SigType" SG_ 2564816640 SAE_J1922 "DISCRETE";
BA_ "SPN" SG_ 2564816640 SAE_J1922 622;
BA_ "SAEDocument" SG_ 2564816640 SAE_J1922 "J1939-73";
BA_ "Variable" SG_ 2564816640 SAE_J1922 "N/A";
BA_ "Status" SG_ 2564816640 J1939Network1 "2.1.0";
BA_ "SigType" SG_ 2564816640 J1939Network1 "DISCRETE";
BA_ "SPN" SG_ 2564816640 J1939Network1 639;
BA_ "SAEDocument" SG_ 2564816640 J1939Network1 "J1939-73";
BA_ "Variable" SG_ 2564816640 J1939Network1 "N/A";
BA_ "Status" SG_ 2564816640 SuspendSignal "2.1.0";
BA_ "SPN" SG_ 2564816640 SuspendSignal 2618;
BA_ "SAEDocument" SG_ 2564816640 SuspendSignal "J1939-73";
BA_ "Variable" SG_ 2564816640 SuspendSignal "N/A";
BA_ "Status" SG_ 2564816640 SuspendDuration "2.1.0";
BA_ "SPN" SG_ 2564816640 SuspendDuration 2619;
BA_ "SAEDocument" SG_ 2564816640 SuspendDuration "J1939-73";
BA_ "Variable" SG_ 2564816640 SuspendDuration "N/A";
BA_ "Variable" SG_ 2566844705 EngIdleIncrementSwitch "Com_stEngIdlIncSwt";
BA_ "Status" SG_ 2566844705 EngIdleIncrementSwitch "3.1.0";
BA_ "SigType" SG_ 2566844705 EngIdleIncrementSwitch "DISCRETE";
BA_ "SPN" SG_ 2566844705 EngIdleIncrementSwitch 968;
BA_ "SAEDocument" SG_ 2566844705 EngIdleIncrementSwitch "J1939-71";
BA_ "Variable" SG_ 2566844705 EngIdleDecrementSwitch "Com_stEngIdlDecSwt";
BA_ "Status" SG_ 2566844705 EngIdleDecrementSwitch "3.1.0";
BA_ "SigType" SG_ 2566844705 EngIdleDecrementSwitch "DISCRETE";
BA_ "SPN" SG_ 2566844705 EngIdleDecrementSwitch 967;
BA_ "SAEDocument" SG_ 2566844705 EngIdleDecrementSwitch "J1939-71";
BA_ "Variable" SG_ 2566844705 EngShutdownOverrideSwitch "Com_stShOffOvrdSwt";
BA_ "Status" SG_ 2566844705 EngShutdownOverrideSwitch "3.1.0";
BA_ "SigType" SG_ 2566844705 EngShutdownOverrideSwitch "DISCRETE";
BA_ "SPN" SG_ 2566844705 EngShutdownOverrideSwitch 1237;
BA_ "SAEDocument" SG_ 2566844705 EngShutdownOverrideSwitch "J1939-71";
BA_ "Variable" SG_ 2566844705 EngTestModeSwitch "Com_stEngTstModeSwt";
BA_ "Status" SG_ 2566844705 EngTestModeSwitch "3.1.0";
BA_ "SigType" SG_ 2566844705 EngTestModeSwitch "DISCRETE";
BA_ "SPN" SG_ 2566844705 EngTestModeSwitch 966;
BA_ "SAEDocument" SG_ 2566844705 EngTestModeSwitch "J1939-71";
BA_ "SigType" SG_ 2566844705 CruiseCtrlStates "DISCRETE";
BA_ "SPN" SG_ 2566844705 CruiseCtrlStates 527;
BA_ "SAEDocument" SG_ 2566844705 CruiseCtrlStates "J1939-71";
BA_ "Status" SG_ 2566844705 CruiseCtrlStates "Not needed";
BA_ "Variable" SG_ 2566844705 PTOState "TSC_stPTO";
BA_ "SigType" SG_ 2566844705 PTOState "DISCRETE";
BA_ "SPN" SG_ 2566844705 PTOState 976;
BA_ "SAEDocument" SG_ 2566844705 PTOState "J1939-71";
BA_ "Status" SG_ 2566844705 PTOState "Not needed";
BA_ "SigType" SG_ 2566844705 CruiseCtrlSetSpeed "RANGE";
BA_ "SPN" SG_ 2566844705 CruiseCtrlSetSpeed 86;
BA_ "SAEDocument" SG_ 2566844705 CruiseCtrlSetSpeed "J1939-71";
BA_ "Status" SG_ 2566844705 CruiseCtrlSetSpeed "Not needed";
BA_ "Variable" SG_ 2566844705 CruiseCtrlAccelerateSwitch "Com_RxCCVSCrCBtn";
BA_ "SigType" SG_ 2566844705 CruiseCtrlAccelerateSwitch "DISCRETE";
BA_ "SPN" SG_ 2566844705 CruiseCtrlAccelerateSwitch 602;
BA_ "SAEDocument" SG_ 2566844705 CruiseCtrlAccelerateSwitch "J1939-71";
BA_ "Status" SG_ 2566844705 CruiseCtrlAccelerateSwitch "2.1.0";
BA_ "Variable" SG_ 2566844705 CruiseCtrlResumeSwitch "Com_RxCCVSCrCBtn";
BA_ "SigType" SG_ 2566844705 CruiseCtrlResumeSwitch "DISCRETE";
BA_ "SPN" SG_ 2566844705 CruiseCtrlResumeSwitch 601;
BA_ "SAEDocument" SG_ 2566844705 CruiseCtrlResumeSwitch "J1939-71";
BA_ "Status" SG_ 2566844705 CruiseCtrlResumeSwitch "2.1.0";
BA_ "Variable" SG_ 2566844705 CruiseCtrlCoastSwitch "Com_RxCCVSCrCBtn";
BA_ "SigType" SG_ 2566844705 CruiseCtrlCoastSwitch "DISCRETE";
BA_ "SPN" SG_ 2566844705 CruiseCtrlCoastSwitch 600;
BA_ "SAEDocument" SG_ 2566844705 CruiseCtrlCoastSwitch "J1939-71";
BA_ "Status" SG_ 2566844705 CruiseCtrlCoastSwitch "2.1.0";
BA_ "Variable" SG_ 2566844705 CruiseCtrlSetSwitch "Com_RxCCVSCrCBtn";
BA_ "SigType" SG_ 2566844705 CruiseCtrlSetSwitch "DISCRETE";
BA_ "SPN" SG_ 2566844705 CruiseCtrlSetSwitch 599;
BA_ "SAEDocument" SG_ 2566844705 CruiseCtrlSetSwitch "J1939-71";
BA_ "Status" SG_ 2566844705 CruiseCtrlSetSwitch "2.1.0";
BA_ "Variable" SG_ 2566844705 ClutchSwitch "Com_stClthSwt";
BA_ "SigType" SG_ 2566844705 ClutchSwitch "DISCRETE";
BA_ "SPN" SG_ 2566844705 ClutchSwitch 598;
BA_ "SAEDocument" SG_ 2566844705 ClutchSwitch "J1939-71";
BA_ "Status" SG_ 2566844705 ClutchSwitch "2.1.0";
BA_ "Variable" SG_ 2566844705 BrakeSwitch "Com_stBrkSwt";
BA_ "SigType" SG_ 2566844705 BrakeSwitch "DISCRETE";
BA_ "SPN" SG_ 2566844705 BrakeSwitch 597;
BA_ "SAEDocument" SG_ 2566844705 BrakeSwitch "J1939-71";
BA_ "Status" SG_ 2566844705 BrakeSwitch "2.1.0";
BA_ "Variable" SG_ 2566844705 CruiseCtrlEnableSwitch "Com_stRxCrCtlEn";
BA_ "Status" SG_ 2566844705 CruiseCtrlEnableSwitch "3.1.0";
BA_ "SigType" SG_ 2566844705 CruiseCtrlEnableSwitch "DISCRETE";
BA_ "SPN" SG_ 2566844705 CruiseCtrlEnableSwitch 596;
BA_ "SAEDocument" SG_ 2566844705 CruiseCtrlEnableSwitch "J1939-71";
BA_ "Variable" SG_ 2566844705 CruiseCtrlActive "VehV_stCrCtlActv";
BA_ "SigType" SG_ 2566844705 CruiseCtrlActive "DISCRETE";
BA_ "SPN" SG_ 2566844705 CruiseCtrlActive 595;
BA_ "SAEDocument" SG_ 2566844705 CruiseCtrlActive "J1939-71";
BA_ "Status" SG_ 2566844705 CruiseCtrlActive "2.1.0";
BA_ "SigType" SG_ 2566844705 WheelBasedVehicleSpeed "RANGE";
BA_ "SPN" SG_ 2566844705 WheelBasedVehicleSpeed 84;
BA_ "SAEDocument" SG_ 2566844705 WheelBasedVehicleSpeed "J1939-71";
BA_ "Status" SG_ 2566844705 WheelBasedVehicleSpeed "Not needed";
BA_ "SigType" SG_ 2566844705 CruiseCtrlPauseSwitch "DISCRETE";
BA_ "SPN" SG_ 2566844705 CruiseCtrlPauseSwitch 1633;
BA_ "SAEDocument" SG_ 2566844705 CruiseCtrlPauseSwitch "J1939-71";
BA_ "Status" SG_ 2566844705 CruiseCtrlPauseSwitch "Not needed";
BA_ "Variable" SG_ 2566844705 ParkingBrakeSwitch "Com_stParkBrkSwt";
BA_ "SigType" SG_ 2566844705 ParkingBrakeSwitch "DISCRETE";
BA_ "SPN" SG_ 2566844705 ParkingBrakeSwitch 70;
BA_ "SAEDocument" SG_ 2566844705 ParkingBrakeSwitch "J1939-71";
BA_ "Status" SG_ 2566844705 ParkingBrakeSwitch "2.1.0";
BA_ "Variable" SG_ 2566844705 TwoSpeedAxleSwitch "Com_stTwoSpdAxlSwt";
BA_ "Status" SG_ 2566844705 TwoSpeedAxleSwitch "3.1.0";
BA_ "SigType" SG_ 2566844705 TwoSpeedAxleSwitch "DISCRETE";
BA_ "SPN" SG_ 2566844705 TwoSpeedAxleSwitch 69;
BA_ "SAEDocument" SG_ 2566844705 TwoSpeedAxleSwitch "J1939-71";
BA_ "SigType" SG_ 2566845719 RoadSurfaceTemp "RANGE";
BA_ "SPN" SG_ 2566845719 RoadSurfaceTemp 79;
BA_ "SAEDocument" SG_ 2566845719 RoadSurfaceTemp "J1939-71";
BA_ "Status" SG_ 2566845719 RoadSurfaceTemp "Not needed";
BA_ "SigType" SG_ 2566845719 EngAirInletTemp "RANGE";
BA_ "SPN" SG_ 2566845719 EngAirInletTemp 172;
BA_ "SAEDocument" SG_ 2566845719 EngAirInletTemp "J1939-71";
BA_ "Status" SG_ 2566845719 EngAirInletTemp "Not needed";
BA_ "SigType" SG_ 2566845719 AmbientAirTemp "RANGE";
BA_ "SPN" SG_ 2566845719 AmbientAirTemp 171;
BA_ "SAEDocument" SG_ 2566845719 AmbientAirTemp "J1939-71";
BA_ "Variable" SG_ 2566845719 AmbientAirTemp "Com_tEnvT";
BA_ "Status" SG_ 2566845719 AmbientAirTemp "2.1.0";
BA_ "SigType" SG_ 2566845719 CabInteriorTemp "RANGE";
BA_ "SPN" SG_ 2566845719 CabInteriorTemp 170;
BA_ "SAEDocument" SG_ 2566845719 CabInteriorTemp "J1939-71";
BA_ "Status" SG_ 2566845719 CabInteriorTemp "Not needed";
BA_ "SigType" SG_ 2566845719 BarometricPress "RANGE";
BA_ "SPN" SG_ 2566845719 BarometricPress 108;
BA_ "SAEDocument" SG_ 2566845719 BarometricPress "J1939-71";
BA_ "Status" SG_ 2566845719 BarometricPress "Not needed";
BA_ "Status" SG_ 2565347072 AddressBusy "Ok";
BA_ "Variable" SG_ 2565347072 AddressBusy "N/A";
BA_ "SPN" SG_ 2565347072 AddressBusy 3293;
BA_ "SAEDocument" SG_ 2565347072 AddressBusy "J1939-21";
BA_ "Status" SG_ 2565347072 ParameterGroupNumber "Ok";
BA_ "Variable" SG_ 2565347072 ParameterGroupNumber "N/A";
BA_ "SigType" SG_ 2565347072 ParameterGroupNumber "RANGE";
BA_ "SPN" SG_ 2565347072 ParameterGroupNumber 2574;
BA_ "SAEDocument" SG_ 2565347072 ParameterGroupNumber "J1939-21";
BA_ "Status" SG_ 2565347072 GroupFunctionValue "Ok";
BA_ "Variable" SG_ 2565347072 GroupFunctionValue "N/A";
BA_ "SigType" SG_ 2565347072 GroupFunctionValue "RANGE";
BA_ "SPN" SG_ 2565347072 GroupFunctionValue 2542;
BA_ "SAEDocument" SG_ 2565347072 GroupFunctionValue "J1939-21";
BA_ "Status" SG_ 2565347072 ControlByte "Ok";
BA_ "Variable" SG_ 2565347072 ControlByte "N/A";
BA_ "SPN" SG_ 2565347072 ControlByte 2556;
BA_ "SAEDocument" SG_ 2565347072 ControlByte "J1939-21";
BA_ "Status" SG_ 2565347072 AddressAccessDenied "Ok";
BA_ "Variable" SG_ 2565347072 AddressAccessDenied "N/A";
BA_ "SPN" SG_ 2565347072 AddressAccessDenied 3292;
BA_ "SAEDocument" SG_ 2565347072 AddressAccessDenied "J1939-21";
BA_ "Status" SG_ 2565347072 AddressNegativeAcknowledgement "Ok";
BA_ "Variable" SG_ 2565347072 AddressNegativeAcknowledgement "N/A";
BA_ "SPN" SG_ 2565347072 AddressNegativeAcknowledgement 3291;
BA_ "SAEDocument" SG_ 2565347072 AddressNegativeAcknowledgement "J1939-21";
BA_ "Status" SG_ 2565347072 AddressAcknowledged "Ok";
BA_ "Variable" SG_ 2565347072 AddressAcknowledged "N/A";
BA_ "SPN" SG_ 2565347072 AddressAcknowledged 3290;
BA_ "SAEDocument" SG_ 2565347072 AddressAcknowledged "J1939-21";
BA_ "Status" SG_ 2565480727 ParameterGroupNumber "Ok";
BA_ "Variable" SG_ 2565480727 ParameterGroupNumber "N/A";
BA_ "SigType" SG_ 2565480727 ParameterGroupNumber "RANGE";
BA_ "SPN" SG_ 2565480727 ParameterGroupNumber 2540;
BA_ "SAEDocument" SG_ 2565480727 ParameterGroupNumber "J1939-21";
BA_ "Status" SG_ 2565537785 ParameterGroupNumber "Ok";
BA_ "Variable" SG_ 2565537785 ParameterGroupNumber "N/A";
BA_ "SigType" SG_ 2565537785 ParameterGroupNumber "RANGE";
BA_ "SPN" SG_ 2565537785 ParameterGroupNumber 2540;
BA_ "SAEDocument" SG_ 2565537785 ParameterGroupNumber "J1939-21";
BA_ "SPN" SG_ 2566864640 CoolantPresSensRawVoltage 521611;
BA_ "Variable" SG_ 2566864640 CoolantPresSensRawVoltage "CEngP_uRaw";
BA_ "Status" SG_ 2566864640 CoolantPresSensRawVoltage "Requested 3.7.0";
BA_ "Status" SG_ 2566864640 CrankcasePresSensRawVoltage "3.5.0";
BA_ "Variable" SG_ 2566864640 CrankcasePresSensRawVoltage "CrCsP_uRaw";
BA_ "SPN" SG_ 2566864640 CrankcasePresSensRawVoltage 521544;
BA_ "SPN" SG_ 2566864640 HumiditySensRawVoltage 521539;
BA_ "Status" SG_ 2566864640 HumiditySensRawVoltage "3.2.0";
BA_ "Variable" SG_ 2566864640 HumiditySensRawVoltage "ATHEval_uHmdRaw";
BA_ "SPN" SG_ 2566864640 BoostPressure2SensRawVoltage 521537;
BA_ "Variable" SG_ 2566864640 BoostPressure2SensRawVoltage "Air_uRawCACDsPLP";
BA_ "Status" SG_ 2566864640 BoostPressure2SensRawVoltage "2.3.0";
BA_ "SPN" SG_ 2566864640 BoostAirTemp2SensRawVoltage 521536;
BA_ "Variable" SG_ 2566864640 BoostAirTemp2SensRawVoltage "Air_uRawCACDsTLP";
BA_ "Status" SG_ 2566864640 BoostAirTemp2SensRawVoltage "2.4.0";
BA_ "SPN" SG_ 2566864640 EGRTemp2SensorPresSensRawVoltage 521535;
BA_ "Variable" SG_ 2566864640 EGRTemp2SensorPresSensRawVoltage "Air_uRawTEGRClr2Ds";
BA_ "Status" SG_ 2566864640 EGRTemp2SensorPresSensRawVoltage "2.3.0";
BA_ "SPN" SG_ 2566864640 EGRTemp1SensorPresSensRawVoltage 521534;
BA_ "Variable" SG_ 2566864640 EGRTemp1SensorPresSensRawVoltage "Air_uRawTEGRClrDs";
BA_ "Status" SG_ 2566864640 EGRTemp1SensorPresSensRawVoltage "2.3.0";
BA_ "Status" SG_ 2566750208 FailureModeIdentifier5 "2.1.0";
BA_ "SAEDocument" SG_ 2566750208 FailureModeIdentifier5 "J1939-73";
BA_ "Variable" SG_ 2566750208 FailureModeIdentifier5 "N/A";
BA_ "SPN" SG_ 2566750208 FailureModeIdentifier5 1215;
BA_ "Status" SG_ 2566750208 FailureModeIdentifier4 "2.1.0";
BA_ "SAEDocument" SG_ 2566750208 FailureModeIdentifier4 "J1939-73";
BA_ "Variable" SG_ 2566750208 FailureModeIdentifier4 "N/A";
BA_ "SPN" SG_ 2566750208 FailureModeIdentifier4 1215;
BA_ "Status" SG_ 2566750208 FailureModeIdentifier3 "2.1.0";
BA_ "SAEDocument" SG_ 2566750208 FailureModeIdentifier3 "J1939-73";
BA_ "Variable" SG_ 2566750208 FailureModeIdentifier3 "N/A";
BA_ "SPN" SG_ 2566750208 FailureModeIdentifier3 1215;
BA_ "Status" SG_ 2566750208 FailureModeIdentifier2 "2.1.0";
BA_ "SAEDocument" SG_ 2566750208 FailureModeIdentifier2 "J1939-73";
BA_ "Variable" SG_ 2566750208 FailureModeIdentifier2 "N/A";
BA_ "SPN" SG_ 2566750208 FailureModeIdentifier2 1215;
BA_ "Status" SG_ 2566750208 FailureModeIdentifier1 "2.1.0";
BA_ "SPN" SG_ 2566750208 FailureModeIdentifier1 1215;
BA_ "SAEDocument" SG_ 2566750208 FailureModeIdentifier1 "J1939-73";
BA_ "Variable" SG_ 2566750208 FailureModeIdentifier1 "N/A";
BA_ "Status" SG_ 2566750208 FlashRedStopLamp "2.1.0";
BA_ "SPN" SG_ 2566750208 FlashRedStopLamp 3039;
BA_ "SAEDocument" SG_ 2566750208 FlashRedStopLamp "J1939-73";
BA_ "Variable" SG_ 2566750208 FlashRedStopLamp "N/A";
BA_ "Status" SG_ 2566750208 FlashProtectLamp "2.1.0";
BA_ "SPN" SG_ 2566750208 FlashProtectLamp 3041;
BA_ "SAEDocument" SG_ 2566750208 FlashProtectLamp "J1939-73";
BA_ "Variable" SG_ 2566750208 FlashProtectLamp "N/A";
BA_ "Status" SG_ 2566750208 FlashMalfuncIndicatorLamp "2.1.0";
BA_ "SigType" SG_ 2566750208 FlashMalfuncIndicatorLamp "DISCRETE";
BA_ "SPN" SG_ 2566750208 FlashMalfuncIndicatorLamp 3038;
BA_ "SAEDocument" SG_ 2566750208 FlashMalfuncIndicatorLamp "J1939-73";
BA_ "Variable" SG_ 2566750208 FlashMalfuncIndicatorLamp "N/A";
BA_ "Status" SG_ 2566750208 FlashAmberWarningLamp "2.1.0";
BA_ "SPN" SG_ 2566750208 FlashAmberWarningLamp 3040;
BA_ "SAEDocument" SG_ 2566750208 FlashAmberWarningLamp "J1939-73";
BA_ "Variable" SG_ 2566750208 FlashAmberWarningLamp "N/A";
BA_ "Status" SG_ 2566750208 OccurenceCount5 "2.1.0";
BA_ "SigType" SG_ 2566750208 OccurenceCount5 "RANGE";
BA_ "SAEDocument" SG_ 2566750208 OccurenceCount5 "J1939-73";
BA_ "Variable" SG_ 2566750208 OccurenceCount5 "N/A";
BA_ "SPN" SG_ 2566750208 OccurenceCount5 1216;
BA_ "Status" SG_ 2566750208 OccurenceCount4 "2.1.0";
BA_ "SigType" SG_ 2566750208 OccurenceCount4 "RANGE";
BA_ "SAEDocument" SG_ 2566750208 OccurenceCount4 "J1939-73";
BA_ "Variable" SG_ 2566750208 OccurenceCount4 "N/A";
BA_ "SPN" SG_ 2566750208 OccurenceCount4 1216;
BA_ "Status" SG_ 2566750208 OccurenceCount3 "2.1.0";
BA_ "SigType" SG_ 2566750208 OccurenceCount3 "RANGE";
BA_ "SAEDocument" SG_ 2566750208 OccurenceCount3 "J1939-73";
BA_ "Variable" SG_ 2566750208 OccurenceCount3 "N/A";
BA_ "SPN" SG_ 2566750208 OccurenceCount3 1216;
BA_ "Status" SG_ 2566750208 OccurenceCount2 "2.1.0";
BA_ "SigType" SG_ 2566750208 OccurenceCount2 "RANGE";
BA_ "SAEDocument" SG_ 2566750208 OccurenceCount2 "J1939-73";
BA_ "Variable" SG_ 2566750208 OccurenceCount2 "N/A";
BA_ "SPN" SG_ 2566750208 OccurenceCount2 1216;
BA_ "Status" SG_ 2566750208 SPNConversionMethod5 "2.1.0";
BA_ "SAEDocument" SG_ 2566750208 SPNConversionMethod5 "J1939-73";
BA_ "Variable" SG_ 2566750208 SPNConversionMethod5 "N/A";
BA_ "SPN" SG_ 2566750208 SPNConversionMethod5 1706;
BA_ "Status" SG_ 2566750208 SPNConversionMethod4 "2.1.0";
BA_ "SAEDocument" SG_ 2566750208 SPNConversionMethod4 "J1939-73";
BA_ "Variable" SG_ 2566750208 SPNConversionMethod4 "N/A";
BA_ "SPN" SG_ 2566750208 SPNConversionMethod4 1706;
BA_ "Status" SG_ 2566750208 SPNConversionMethod3 "2.1.0";
BA_ "SAEDocument" SG_ 2566750208 SPNConversionMethod3 "J1939-73";
BA_ "Variable" SG_ 2566750208 SPNConversionMethod3 "N/A";
BA_ "SPN" SG_ 2566750208 SPNConversionMethod3 1706;
BA_ "Status" SG_ 2566750208 SPNConversionMethod2 "2.1.0";
BA_ "SAEDocument" SG_ 2566750208 SPNConversionMethod2 "J1939-73";
BA_ "Variable" SG_ 2566750208 SPNConversionMethod2 "N/A";
BA_ "SPN" SG_ 2566750208 SPNConversionMethod2 1706;
BA_ "Status" SG_ 2566750208 SPNConversionMethod1 "2.1.0";
BA_ "SPN" SG_ 2566750208 SPNConversionMethod1 1706;
BA_ "SAEDocument" SG_ 2566750208 SPNConversionMethod1 "J1939-73";
BA_ "Variable" SG_ 2566750208 SPNConversionMethod1 "N/A";
BA_ "Status" SG_ 2566750208 SPN5High "2.1.0";
BA_ "SAEDocument" SG_ 2566750208 SPN5High "J1939-73";
BA_ "Variable" SG_ 2566750208 SPN5High "N/A";
BA_ "SPN" SG_ 2566750208 SPN5High 1214;
BA_ "Status" SG_ 2566750208 SPN5 "2.1.0";
BA_ "SAEDocument" SG_ 2566750208 SPN5 "J1939-73";
BA_ "Variable" SG_ 2566750208 SPN5 "N/A";
BA_ "SPN" SG_ 2566750208 SPN5 1214;
BA_ "Status" SG_ 2566750208 SPN4High "2.1.0";
BA_ "SAEDocument" SG_ 2566750208 SPN4High "J1939-73";
BA_ "Variable" SG_ 2566750208 SPN4High "N/A";
BA_ "SPN" SG_ 2566750208 SPN4High 1214;
BA_ "Status" SG_ 2566750208 SPN4 "2.1.0";
BA_ "SAEDocument" SG_ 2566750208 SPN4 "J1939-73";
BA_ "Variable" SG_ 2566750208 SPN4 "N/A";
BA_ "SPN" SG_ 2566750208 SPN4 1214;
BA_ "Status" SG_ 2566750208 SPN3High "2.1.0";
BA_ "SAEDocument" SG_ 2566750208 SPN3High "J1939-73";
BA_ "Variable" SG_ 2566750208 SPN3High "N/A";
BA_ "SPN" SG_ 2566750208 SPN3High 1214;
BA_ "Status" SG_ 2566750208 SPN3 "2.1.0";
BA_ "SAEDocument" SG_ 2566750208 SPN3 "J1939-73";
BA_ "Variable" SG_ 2566750208 SPN3 "N/A";
BA_ "SPN" SG_ 2566750208 SPN3 1214;
BA_ "Status" SG_ 2566750208 SPN2High "2.1.0";
BA_ "SAEDocument" SG_ 2566750208 SPN2High "J1939-73";
BA_ "Variable" SG_ 2566750208 SPN2High "N/A";
BA_ "SPN" SG_ 2566750208 SPN2High 1214;
BA_ "Status" SG_ 2566750208 SPN2 "2.1.0";
BA_ "SAEDocument" SG_ 2566750208 SPN2 "J1939-73";
BA_ "Variable" SG_ 2566750208 SPN2 "N/A";
BA_ "SPN" SG_ 2566750208 SPN2 1214;
BA_ "Status" SG_ 2566750208 SPN1High "2.1.0";
BA_ "SPN" SG_ 2566750208 SPN1High 1214;
BA_ "SAEDocument" SG_ 2566750208 SPN1High "J1939-73";
BA_ "Variable" SG_ 2566750208 SPN1High "N/A";
BA_ "Status" SG_ 2566750208 SPN1 "2.1.0";
BA_ "SPN" SG_ 2566750208 SPN1 1214;
BA_ "SAEDocument" SG_ 2566750208 SPN1 "J1939-73";
BA_ "Variable" SG_ 2566750208 SPN1 "N/A";
BA_ "Status" SG_ 2566750208 RedStopLampStatus "2.1.0";
BA_ "SigType" SG_ 2566750208 RedStopLampStatus "DISCRETE";
BA_ "SPN" SG_ 2566750208 RedStopLampStatus 623;
BA_ "SAEDocument" SG_ 2566750208 RedStopLampStatus "J1939-73";
BA_ "Variable" SG_ 2566750208 RedStopLampStatus "N/A";
BA_ "Status" SG_ 2566750208 ProtectLampStatus "2.1.0";
BA_ "SigType" SG_ 2566750208 ProtectLampStatus "DISCRETE";
BA_ "SPN" SG_ 2566750208 ProtectLampStatus 987;
BA_ "SAEDocument" SG_ 2566750208 ProtectLampStatus "J1939-73";
BA_ "Variable" SG_ 2566750208 ProtectLampStatus "N/A";
BA_ "Status" SG_ 2566750208 AmberWarningLampStatus "2.1.0";
BA_ "SigType" SG_ 2566750208 AmberWarningLampStatus "DISCRETE";
BA_ "SPN" SG_ 2566750208 AmberWarningLampStatus 624;
BA_ "SAEDocument" SG_ 2566750208 AmberWarningLampStatus "J1939-73";
BA_ "Variable" SG_ 2566750208 AmberWarningLampStatus "N/A";
BA_ "Status" SG_ 2566750208 MalfunctionIndicatorLampStatus "2.1.0";
BA_ "SigType" SG_ 2566750208 MalfunctionIndicatorLampStatus "DISCRETE";
BA_ "SPN" SG_ 2566750208 MalfunctionIndicatorLampStatus 1213;
BA_ "SAEDocument" SG_ 2566750208 MalfunctionIndicatorLampStatus "J1939-73";
BA_ "Variable" SG_ 2566750208 MalfunctionIndicatorLampStatus "N/A";
BA_ "Status" SG_ 2566750208 OccurenceCount1 "2.1.0";
BA_ "SigType" SG_ 2566750208 OccurenceCount1 "RANGE";
BA_ "SPN" SG_ 2566750208 OccurenceCount1 1216;
BA_ "SAEDocument" SG_ 2566750208 OccurenceCount1 "J1939-73";
BA_ "Variable" SG_ 2566750208 OccurenceCount1 "N/A";
BA_ "Status" SG_ 2566750720 OccurenceCount5 "2.1.0";
BA_ "SigType" SG_ 2566750720 OccurenceCount5 "RANGE";
BA_ "SAEDocument" SG_ 2566750720 OccurenceCount5 "J1939-73";
BA_ "Variable" SG_ 2566750720 OccurenceCount5 "N/A";
BA_ "SPN" SG_ 2566750720 OccurenceCount5 1216;
BA_ "Status" SG_ 2566750720 OccurenceCount4 "2.1.0";
BA_ "SigType" SG_ 2566750720 OccurenceCount4 "RANGE";
BA_ "SAEDocument" SG_ 2566750720 OccurenceCount4 "J1939-73";
BA_ "Variable" SG_ 2566750720 OccurenceCount4 "N/A";
BA_ "SPN" SG_ 2566750720 OccurenceCount4 1216;
BA_ "Status" SG_ 2566750720 OccurenceCount3 "2.1.0";
BA_ "SigType" SG_ 2566750720 OccurenceCount3 "RANGE";
BA_ "SAEDocument" SG_ 2566750720 OccurenceCount3 "J1939-73";
BA_ "Variable" SG_ 2566750720 OccurenceCount3 "N/A";
BA_ "SPN" SG_ 2566750720 OccurenceCount3 1216;
BA_ "Status" SG_ 2566750720 OccurenceCount2 "2.1.0";
BA_ "SigType" SG_ 2566750720 OccurenceCount2 "RANGE";
BA_ "SAEDocument" SG_ 2566750720 OccurenceCount2 "J1939-73";
BA_ "Variable" SG_ 2566750720 OccurenceCount2 "N/A";
BA_ "SPN" SG_ 2566750720 OccurenceCount2 1216;
BA_ "Status" SG_ 2566750720 SPNConversionMethod5 "2.1.0";
BA_ "SAEDocument" SG_ 2566750720 SPNConversionMethod5 "J1939-73";
BA_ "Variable" SG_ 2566750720 SPNConversionMethod5 "N/A";
BA_ "SPN" SG_ 2566750720 SPNConversionMethod5 1706;
BA_ "Status" SG_ 2566750720 SPNConversionMethod4 "2.1.0";
BA_ "SAEDocument" SG_ 2566750720 SPNConversionMethod4 "J1939-73";
BA_ "Variable" SG_ 2566750720 SPNConversionMethod4 "N/A";
BA_ "SPN" SG_ 2566750720 SPNConversionMethod4 1706;
BA_ "Status" SG_ 2566750720 SPNConversionMethod3 "2.1.0";
BA_ "SAEDocument" SG_ 2566750720 SPNConversionMethod3 "J1939-73";
BA_ "Variable" SG_ 2566750720 SPNConversionMethod3 "N/A";
BA_ "SPN" SG_ 2566750720 SPNConversionMethod3 1706;
BA_ "Status" SG_ 2566750720 SPNConversionMethod2 "2.1.0";
BA_ "SAEDocument" SG_ 2566750720 SPNConversionMethod2 "J1939-73";
BA_ "Variable" SG_ 2566750720 SPNConversionMethod2 "N/A";
BA_ "SPN" SG_ 2566750720 SPNConversionMethod2 1706;
BA_ "Status" SG_ 2566750720 SPN5High "2.1.0";
BA_ "SAEDocument" SG_ 2566750720 SPN5High "J1939-73";
BA_ "Variable" SG_ 2566750720 SPN5High "N/A";
BA_ "SPN" SG_ 2566750720 SPN5High 1214;
BA_ "Status" SG_ 2566750720 SPN5 "2.1.0";
BA_ "SAEDocument" SG_ 2566750720 SPN5 "J1939-73";
BA_ "Variable" SG_ 2566750720 SPN5 "N/A";
BA_ "SPN" SG_ 2566750720 SPN5 1214;
BA_ "Status" SG_ 2566750720 SPN4High "2.1.0";
BA_ "SAEDocument" SG_ 2566750720 SPN4High "J1939-73";
BA_ "Variable" SG_ 2566750720 SPN4High "N/A";
BA_ "SPN" SG_ 2566750720 SPN4High 1214;
BA_ "Status" SG_ 2566750720 SPN4 "2.1.0";
BA_ "SAEDocument" SG_ 2566750720 SPN4 "J1939-73";
BA_ "Variable" SG_ 2566750720 SPN4 "N/A";
BA_ "SPN" SG_ 2566750720 SPN4 1214;
BA_ "Status" SG_ 2566750720 SPN3High "2.1.0";
BA_ "SAEDocument" SG_ 2566750720 SPN3High "J1939-73";
BA_ "Variable" SG_ 2566750720 SPN3High "N/A";
BA_ "SPN" SG_ 2566750720 SPN3High 1214;
BA_ "Status" SG_ 2566750720 SPN3 "2.1.0";
BA_ "SAEDocument" SG_ 2566750720 SPN3 "J1939-73";
BA_ "Variable" SG_ 2566750720 SPN3 "N/A";
BA_ "SPN" SG_ 2566750720 SPN3 1214;
BA_ "Status" SG_ 2566750720 SPN2High "2.1.0";
BA_ "SAEDocument" SG_ 2566750720 SPN2High "J1939-73";
BA_ "Variable" SG_ 2566750720 SPN2High "N/A";
BA_ "SPN" SG_ 2566750720 SPN2High 1214;
BA_ "Status" SG_ 2566750720 SPN2 "2.1.0";
BA_ "SAEDocument" SG_ 2566750720 SPN2 "J1939-73";
BA_ "Variable" SG_ 2566750720 SPN2 "N/A";
BA_ "SPN" SG_ 2566750720 SPN2 1214;
BA_ "Status" SG_ 2566750720 SPN1High "2.1.0";
BA_ "SPN" SG_ 2566750720 SPN1High 1214;
BA_ "SAEDocument" SG_ 2566750720 SPN1High "J1939-73";
BA_ "Variable" SG_ 2566750720 SPN1High "N/A";
BA_ "Status" SG_ 2566750720 SPN1 "2.1.0";
BA_ "SPN" SG_ 2566750720 SPN1 1214;
BA_ "SAEDocument" SG_ 2566750720 SPN1 "J1939-73";
BA_ "Variable" SG_ 2566750720 SPN1 "N/A";
BA_ "Status" SG_ 2566750720 FailureModeIdentifier5 "2.1.0";
BA_ "SAEDocument" SG_ 2566750720 FailureModeIdentifier5 "J1939-73";
BA_ "Variable" SG_ 2566750720 FailureModeIdentifier5 "N/A";
BA_ "SPN" SG_ 2566750720 FailureModeIdentifier5 1215;
BA_ "Status" SG_ 2566750720 FailureModeIdentifier4 "2.1.0";
BA_ "SAEDocument" SG_ 2566750720 FailureModeIdentifier4 "J1939-73";
BA_ "Variable" SG_ 2566750720 FailureModeIdentifier4 "N/A";
BA_ "SPN" SG_ 2566750720 FailureModeIdentifier4 1215;
BA_ "Status" SG_ 2566750720 FailureModeIdentifier3 "2.1.0";
BA_ "SAEDocument" SG_ 2566750720 FailureModeIdentifier3 "J1939-73";
BA_ "Variable" SG_ 2566750720 FailureModeIdentifier3 "N/A";
BA_ "SPN" SG_ 2566750720 FailureModeIdentifier3 1215;
BA_ "Status" SG_ 2566750720 FailureModeIdentifier2 "2.1.0";
BA_ "SAEDocument" SG_ 2566750720 FailureModeIdentifier2 "J1939-73";
BA_ "Variable" SG_ 2566750720 FailureModeIdentifier2 "N/A";
BA_ "SPN" SG_ 2566750720 FailureModeIdentifier2 1215;
BA_ "Status" SG_ 2566750720 FailureModeIdentifier1 "2.1.0";
BA_ "SPN" SG_ 2566750720 FailureModeIdentifier1 1215;
BA_ "SAEDocument" SG_ 2566750720 FailureModeIdentifier1 "J1939-73";
BA_ "Variable" SG_ 2566750720 FailureModeIdentifier1 "N/A";
BA_ "Status" SG_ 2566750720 FlashRedStopLamp "2.1.0";
BA_ "SPN" SG_ 2566750720 FlashRedStopLamp 3039;
BA_ "SAEDocument" SG_ 2566750720 FlashRedStopLamp "J1939-73";
BA_ "Variable" SG_ 2566750720 FlashRedStopLamp "N/A";
BA_ "Status" SG_ 2566750720 FlashProtectLamp "2.1.0";
BA_ "SPN" SG_ 2566750720 FlashProtectLamp 3041;
BA_ "SAEDocument" SG_ 2566750720 FlashProtectLamp "J1939-73";
BA_ "Variable" SG_ 2566750720 FlashProtectLamp "N/A";
BA_ "Status" SG_ 2566750720 FlashMalfuncIndicatorLamp "2.1.0";
BA_ "SigType" SG_ 2566750720 FlashMalfuncIndicatorLamp "DISCRETE";
BA_ "SPN" SG_ 2566750720 FlashMalfuncIndicatorLamp 3038;
BA_ "SAEDocument" SG_ 2566750720 FlashMalfuncIndicatorLamp "J1939-73";
BA_ "Variable" SG_ 2566750720 FlashMalfuncIndicatorLamp "N/A";
BA_ "Status" SG_ 2566750720 FlashAmberWarningLamp "2.1.0";
BA_ "SPN" SG_ 2566750720 FlashAmberWarningLamp 3040;
BA_ "SAEDocument" SG_ 2566750720 FlashAmberWarningLamp "J1939-73";
BA_ "Variable" SG_ 2566750720 FlashAmberWarningLamp "N/A";
BA_ "Status" SG_ 2566750720 RedStopLampStatus "2.1.0";
BA_ "SigType" SG_ 2566750720 RedStopLampStatus "DISCRETE";
BA_ "SPN" SG_ 2566750720 RedStopLampStatus 623;
BA_ "SAEDocument" SG_ 2566750720 RedStopLampStatus "J1939-73";
BA_ "Variable" SG_ 2566750720 RedStopLampStatus "N/A";
BA_ "Status" SG_ 2566750720 ProtectLampStatus "2.1.0";
BA_ "SigType" SG_ 2566750720 ProtectLampStatus "DISCRETE";
BA_ "SPN" SG_ 2566750720 ProtectLampStatus 987;
BA_ "SAEDocument" SG_ 2566750720 ProtectLampStatus "J1939-73";
BA_ "Variable" SG_ 2566750720 ProtectLampStatus "N/A";
BA_ "Status" SG_ 2566750720 AmberWarningLampStatus "2.1.0";
BA_ "SigType" SG_ 2566750720 AmberWarningLampStatus "DISCRETE";
BA_ "SPN" SG_ 2566750720 AmberWarningLampStatus 624;
BA_ "SAEDocument" SG_ 2566750720 AmberWarningLampStatus "J1939-73";
BA_ "Variable" SG_ 2566750720 AmberWarningLampStatus "N/A";
BA_ "Status" SG_ 2566750720 MalfunctionIndicatorLampStatus "2.1.0";
BA_ "SigType" SG_ 2566750720 MalfunctionIndicatorLampStatus "DISCRETE";
BA_ "SPN" SG_ 2566750720 MalfunctionIndicatorLampStatus 1213;
BA_ "SAEDocument" SG_ 2566750720 MalfunctionIndicatorLampStatus "J1939-73";
BA_ "Variable" SG_ 2566750720 MalfunctionIndicatorLampStatus "N/A";
BA_ "Status" SG_ 2566750720 OccurenceCount1 "2.1.0";
BA_ "SigType" SG_ 2566750720 OccurenceCount1 "RANGE";
BA_ "SPN" SG_ 2566750720 OccurenceCount1 1216;
BA_ "SAEDocument" SG_ 2566750720 OccurenceCount1 "J1939-73";
BA_ "Variable" SG_ 2566750720 OccurenceCount1 "N/A";
BA_ "Status" SG_ 2566750720 SPNConversionMethod1 "2.1.0";
BA_ "SPN" SG_ 2566750720 SPNConversionMethod1 1706;
BA_ "SAEDocument" SG_ 2566750720 SPNConversionMethod1 "J1939-73";
BA_ "Variable" SG_ 2566750720 SPNConversionMethod1 "N/A";
BA_ "SPN" SG_ 2565734401 FunctionInstance 2848;
BA_ "SAEDocument" SG_ 2565734401 FunctionInstance "J1939-81";
BA_ "Status" SG_ 2565734401 FunctionInstance "2.5.0";
BA_ "SPN" SG_ 2565734401 ArbitraryAddressCapable 2848;
BA_ "SAEDocument" SG_ 2565734401 ArbitraryAddressCapable "J1939-81";
BA_ "Status" SG_ 2565734401 ArbitraryAddressCapable "2.5.0";
BA_ "SPN" SG_ 2565734401 IndustryGroup 2848;
BA_ "SAEDocument" SG_ 2565734401 IndustryGroup "J1939-81";
BA_ "Status" SG_ 2565734401 IndustryGroup "2.5.0";
BA_ "SPN" SG_ 2565734401 VehicleSystemInstance 2848;
BA_ "SigType" SG_ 2565734401 VehicleSystemInstance "J1939-81";
BA_ "Status" SG_ 2565734401 VehicleSystemInstance "2.5.0";
BA_ "SPN" SG_ 2565734401 VehicleSystem 2848;
BA_ "SAEDocument" SG_ 2565734401 VehicleSystem "J1939-81";
BA_ "Status" SG_ 2565734401 VehicleSystem "2.5.0";
BA_ "SPN" SG_ 2565734401 Function 2848;
BA_ "SAEDocument" SG_ 2565734401 Function "J1939-81";
BA_ "Status" SG_ 2565734401 Function "2.5.0";
BA_ "SPN" SG_ 2565734401 ECUInstance 2848;
BA_ "SAEDocument" SG_ 2565734401 ECUInstance "J1939-81";
BA_ "Status" SG_ 2565734401 ECUInstance "2.5.0";
BA_ "SPN" SG_ 2565734401 ManufacturerCode 2848;
BA_ "SAEDocument" SG_ 2565734401 ManufacturerCode "J1939-81";
BA_ "Status" SG_ 2565734401 ManufacturerCode "2.5.0";
BA_ "SAEDocument" SG_ 2565734401 IdentityNumber "J1939-81";
BA_ "SPN" SG_ 2565734401 IdentityNumber 2848;
BA_ "Status" SG_ 2565734401 IdentityNumber "2.5.0";
BA_ "SPN" SG_ 2565869056 Aftertreatment1IntSensHtrCtl 3223;
BA_ "SAEDocument" SG_ 2565869056 Aftertreatment1IntSensHtrCtl "J1939-71";
BA_ "Variable" SG_ 2565869056 Aftertreatment1IntSensHtrCtl "LSU_dcycHtcor[0]";
BA_ "Status" SG_ 2565869056 Aftertreatment1IntSensHtrCtl "3.4.11";
BA_ "SAEDocument" SG_ 2565869056 Aftrtmnt1IntkWideRngPrcnt0Stable "SAE J1939_71";
BA_ "SPN" SG_ 2565869056 Aftrtmnt1IntkWideRngPrcnt0Stable 3221;
BA_ "SigType" SG_ 2565869056 Aftrtmnt1IntkWideRngPrcnt0Stable "DISCREET";
BA_ "Status" SG_ 2565869056 Aftrtmnt1IntkWideRngPrcnt0Stable "Not needed";
BA_ "SigType" SG_ 2565869056 Aftreatment1IntakePercentO2 "RANGE";
BA_ "SAEDocument" SG_ 2565869056 Aftreatment1IntakePercentO2 "SAE J1939_71";
BA_ "SPN" SG_ 2565869056 Aftreatment1IntakePercentO2 3217;
BA_ "Variable" SG_ 2565869056 Aftreatment1IntakePercentO2 "LSU_rO2Act[0]";
BA_ "Status" SG_ 2565869056 Aftreatment1IntakePercentO2 "2.4.0";
BA_ "Status" SG_ 2566770688 EngineIntakeManifold1AbsPress "2.4.0";
BA_ "SigType" SG_ 2566770688 EngineIntakeManifold1AbsPress "RANGE";
BA_ "SPN" SG_ 2566770688 EngineIntakeManifold1AbsPress 3563;
BA_ "SAEDocument" SG_ 2566770688 EngineIntakeManifold1AbsPress "J1939-71";
BA_ "Variable" SG_ 2566770688 EngineIntakeManifold1AbsPress "Air_pSensPCACDs";
BA_ "Status" SG_ 2560556800 PermanentDTCs "2.1.0";
BA_ "SPN" SG_ 2560556800 PermanentDTCs 4108;
BA_ "SAEDocument" SG_ 2560556800 PermanentDTCs "J1939_73";
BA_ "Variable" SG_ 2560556800 PermanentDTCs "N/A";
BA_ "Status" SG_ 2560556800 PreviosulyMILonDTCs "2.1.0";
BA_ "SPN" SG_ 2560556800 PreviosulyMILonDTCs 4107;
BA_ "SAEDocument" SG_ 2560556800 PreviosulyMILonDTCs "J1939_73";
BA_ "Variable" SG_ 2560556800 PreviosulyMILonDTCs "N/A";
BA_ "Status" SG_ 2560556800 MILonDTCs "2.1.0";
BA_ "SPN" SG_ 2560556800 MILonDTCs 4106;
BA_ "SAEDocument" SG_ 2560556800 MILonDTCs "SAE J1939_73";
BA_ "Variable" SG_ 2560556800 MILonDTCs "N/A";
BA_ "Status" SG_ 2560556800 AllPendingDTCs "2.1.0";
BA_ "SPN" SG_ 2560556800 AllPendingDTCs 4105;
BA_ "SAEDocument" SG_ 2560556800 AllPendingDTCs "J1939_73";
BA_ "Variable" SG_ 2560556800 AllPendingDTCs "N/A";
BA_ "Status" SG_ 2560556800 PendingDTCs "2.1.0";
BA_ "SPN" SG_ 2560556800 PendingDTCs 4104;
BA_ "SAEDocument" SG_ 2560556800 PendingDTCs "J1939_73";
BA_ "Variable" SG_ 2560556800 PendingDTCs "N/A";
BA_ "Status" SG_ 2560950016 SLOTIdentifier "Ok";
BA_ "SigType" SG_ 2560950016 SLOTIdentifier "RANGE";
BA_ "SPN" SG_ 2560950016 SLOTIdentifier 4109;
BA_ "SAEDocument" SG_ 2560950016 SLOTIdentifier "J1939-73";
BA_ "Variable" SG_ 2560950016 SLOTIdentifier "N/A";
BA_ "Status" SG_ 2560950016 TestLimitMinimum "Ok";
BA_ "SigType" SG_ 2560950016 TestLimitMinimum "RANGE";
BA_ "SPN" SG_ 2560950016 TestLimitMinimum 4112;
BA_ "SAEDocument" SG_ 2560950016 TestLimitMinimum "J1939-73";
BA_ "Variable" SG_ 2560950016 TestLimitMinimum "N/A";
BA_ "Status" SG_ 2560950016 TestLimitMaximum "Ok";
BA_ "SigType" SG_ 2560950016 TestLimitMaximum "RANGE";
BA_ "SPN" SG_ 2560950016 TestLimitMaximum 4111;
BA_ "SAEDocument" SG_ 2560950016 TestLimitMaximum "J1939-73";
BA_ "Variable" SG_ 2560950016 TestLimitMaximum "N/A";
BA_ "Status" SG_ 2560950016 TestValue "Ok";
BA_ "SigType" SG_ 2560950016 TestValue "RANGE";
BA_ "SPN" SG_ 2560950016 TestValue 4110;
BA_ "SAEDocument" SG_ 2560950016 TestValue "J1939-73";
BA_ "Variable" SG_ 2560950016 TestValue "N/A";
BA_ "Status" SG_ 2566842110 LocalHourOffset "2.4.0";
BA_ "SigType" SG_ 2566842110 LocalHourOffset "RANGE";
BA_ "SPN" SG_ 2566842110 LocalHourOffset 1602;
BA_ "SAEDocument" SG_ 2566842110 LocalHourOffset "J1939_71";
BA_ "Variable" SG_ 2566842110 LocalHourOffset "Com_TimeDateLocHrs";
BA_ "Status" SG_ 2566842110 LocalMinuteOffset "2.4.0";
BA_ "SigType" SG_ 2566842110 LocalMinuteOffset "RANGE";
BA_ "SPN" SG_ 2566842110 LocalMinuteOffset 1601;
BA_ "SAEDocument" SG_ 2566842110 LocalMinuteOffset "J1939_71";
BA_ "Variable" SG_ 2566842110 LocalMinuteOffset "Com_TimeDateLocMnts";
BA_ "Status" SG_ 2566842110 Year "2.4.0";
BA_ "SAEDocument" SG_ 2566842110 Year "J1939_71";
BA_ "SPN" SG_ 2566842110 Year 964;
BA_ "SigType" SG_ 2566842110 Year "RANGE";
BA_ "Variable" SG_ 2566842110 Year "Com_TimeDateYr";
BA_ "Status" SG_ 2566842110 Month "2.4.0";
BA_ "SigType" SG_ 2566842110 Month "RANGE";
BA_ "SPN" SG_ 2566842110 Month 963;
BA_ "SAEDocument" SG_ 2566842110 Month "J1939_71";
BA_ "Variable" SG_ 2566842110 Month "Com_TimeDateMnth";
BA_ "Status" SG_ 2566842110 Day "2.4.0";
BA_ "SAEDocument" SG_ 2566842110 Day "J1939_71";
BA_ "SPN" SG_ 2566842110 Day 962;
BA_ "SigType" SG_ 2566842110 Day "RANGE";
BA_ "Variable" SG_ 2566842110 Day "Com_TimeDateDay";
BA_ "Status" SG_ 2566842110 Hours "2.4.0";
BA_ "SPN" SG_ 2566842110 Hours 961;
BA_ "SigType" SG_ 2566842110 Hours "RANGE";
BA_ "SAEDocument" SG_ 2566842110 Hours "J1939_71";
BA_ "Variable" SG_ 2566842110 Hours "Com_TimeDateHrs";
BA_ "Status" SG_ 2566842110 Minutes "2.4.0";
BA_ "SPN" SG_ 2566842110 Minutes 960;
BA_ "Variable" SG_ 2566842110 Minutes "Com_TimeDateMnts";
BA_ "Status" SG_ 2566842110 Seconds "2.4.0";
BA_ "SPN" SG_ 2566842110 Seconds 959;
BA_ "Variable" SG_ 2566842110 Seconds "Com_TimeDateSec";
BA_ "Status" SG_ 2560687872 PMNTEDeficiencyAreaStatus "2.1.0";
BA_ "SPN" SG_ 2560687872 PMNTEDeficiencyAreaStatus 4132;
BA_ "SAEDocument" SG_ 2560687872 PMNTEDeficiencyAreaStatus "J1939-73";
BA_ "Status" SG_ 2560687872 ManufactPMNTECarveOutAreaStatus "2.1.0";
BA_ "SPN" SG_ 2560687872 ManufactPMNTECarveOutAreaStatus 4131;
BA_ "SAEDocument" SG_ 2560687872 ManufactPMNTECarveOutAreaStatus "J1939-73";
BA_ "Status" SG_ 2560687872 PMNTECtrlAreaStatus "2.1.0";
BA_ "SPN" SG_ 2560687872 PMNTECtrlAreaStatus 4130;
BA_ "SAEDocument" SG_ 2560687872 PMNTECtrlAreaStatus "J1939-73";
BA_ "Status" SG_ 2560687872 NOxNTEDeficiencyAreaStatus "2.1.0";
BA_ "SPN" SG_ 2560687872 NOxNTEDeficiencyAreaStatus 4129;
BA_ "SAEDocument" SG_ 2560687872 NOxNTEDeficiencyAreaStatus "J1939-73";
BA_ "Status" SG_ 2560687872 ManufactNOxNTECarveOutAreaStatus "2.1.0";
BA_ "SPN" SG_ 2560687872 ManufactNOxNTECarveOutAreaStatus 4128;
BA_ "SAEDocument" SG_ 2560687872 ManufactNOxNTECarveOutAreaStatus "J1939-73";
BA_ "Status" SG_ 2560687872 NOxNTECtrlAreaStatus "2.1.0";
BA_ "SPN" SG_ 2560687872 NOxNTECtrlAreaStatus 4127;
BA_ "SAEDocument" SG_ 2560687872 NOxNTECtrlAreaStatus "J1939-73";
BA_ "Status" SG_ 2566755328 Breather_Sep_Speed "3.1.0";
BA_ "Variable" SG_ 2566755328 Breather_Sep_Speed "BrtrFan_nSens";
BA_ "SAEDocument" SG_ 2566755328 Breather_Sep_Speed "J1939-71";
BA_ "SPN" SG_ 2566755328 Breather_Sep_Speed 5444;
BA_ "SigType" SG_ 2566755328 Breather_Sep_Speed "RANGE";
BA_ "SigType" SG_ 2566755328 EGRVlvPosition "RANGE";
BA_ "SPN" SG_ 2566755328 EGRVlvPosition 27;
BA_ "SAEDocument" SG_ 2566755328 EGRVlvPosition "J1939-71";
BA_ "Variable" SG_ 2566755328 EGRVlvPosition "EGRVlv_rSens";
BA_ "Status" SG_ 2566755328 EGRVlvPosition "2.3.0";
BA_ "Variable" SG_ 2566743552 EngCoolantTemp2 "CEngUsT_tSens";
BA_ "SigType" SG_ 2566743552 EngCoolantTemp2 "RANGE";
BA_ "SPN" SG_ 2566743552 EngCoolantTemp2 4076;
BA_ "SAEDocument" SG_ 2566743552 EngCoolantTemp2 "J1939-71";
BA_ "Status" SG_ 2566743552 EngCoolantTemp2 "2.1.0";
BA_ "Status" SG_ 2566822144 EngTurbo2CompressorInletPress "2.5.0";
BA_ "SAEDocument" SG_ 2566822144 EngTurbo2CompressorInletPress "J1939-71";
BA_ "SPN" SG_ 2566822144 EngTurbo2CompressorInletPress 1177;
BA_ "SigType" SG_ 2566822144 EngTurbo2CompressorInletPress "RANGE";
BA_ "Variable" SG_ 2566822144 EngTurbo2CompressorInletPress "(Air_pSensCACDsPLP - EnvP_pSens)";
BA_ "Status" SG_ 2566864384 OilTempSens2RawVoltage "3.4.6";
BA_ "Variable" SG_ 2566864384 OilTempSens2RawVoltage "OilTSmp_uRaw";
BA_ "SPN" SG_ 2566864384 OilTempSens2RawVoltage 521543;
BA_ "SPN" SG_ 2566864384 AmbTempSensorRawVoltage 521542;
BA_ "Status" SG_ 2566864384 AmbTempSensorRawVoltage "3.4.0";
BA_ "Variable" SG_ 2566864384 AmbTempSensorRawVoltage "EnvT_uRaw";
BA_ "Variable" SG_ 2566864384 OilTempSensRawVoltage "Oil_uRawTSwmp";
BA_ "SPN" SG_ 2566864384 OilTempSensRawVoltage 521532;
BA_ "Status" SG_ 2566864384 OilTempSensRawVoltage "2.1.0";
BA_ "Variable" SG_ 2566864384 LambdaSensorVoltage_IntRes "LSU_uRiFlt[Com_numLamInResRaw_C]";
BA_ "SPN" SG_ 2566864384 LambdaSensorVoltage_IntRes 521533;
BA_ "Status" SG_ 2566864384 LambdaSensorVoltage_IntRes "2.1.0";
BA_ "Status" SG_ 2566864384 IntakeManifoldTempSensRawVoltage "2.3.0";
BA_ "SPN" SG_ 2566864384 IntakeManifoldTempSensRawVoltage 521531;
BA_ "Variable" SG_ 2566864384 IntakeManifoldTempSensRawVoltage "Air_uRawTIntkVUs";
BA_ "Variable" SG_ 2566864384 CoolantTempSensRawVoltage "CEngDsT_uRaw";
BA_ "SPN" SG_ 2566864384 CoolantTempSensRawVoltage 521529;
BA_ "Status" SG_ 2566864384 CoolantTempSensRawVoltage "2.1.0";
BA_ "Status" SG_ 2566864384 CoolantTempSens2RawVoltage "2.3.0";
BA_ "SPN" SG_ 2566864384 CoolantTempSens2RawVoltage 521530;
BA_ "Variable" SG_ 2566864384 CoolantTempSens2RawVoltage "CEngUsT_uRaw";
BA_ "Variable" SG_ 2566864384 BoostAirTempSensRawVoltage "Air_uRawTCACDs";
BA_ "SPN" SG_ 2566864384 BoostAirTempSensRawVoltage 521528;
BA_ "Status" SG_ 2566864384 BoostAirTempSensRawVoltage "2.1.0";
BA_ "Variable" SG_ 2566864128 LambdaSensorVoltage_O2Signal "LSU_uO2RawAdcDirect[Com_numLamOxRaw_C]";
BA_ "SPN" SG_ 2566864128 LambdaSensorVoltage_O2Signal 521527;
BA_ "Status" SG_ 2566864128 LambdaSensorVoltage_O2Signal "2.1.0";
BA_ "SPN" SG_ 2566864128 ExhaustGasRecircValvePosRawVolt 521526;
BA_ "Variable" SG_ 2566864128 ExhaustGasRecircValvePosRawVolt "EGRVlv_uRaw";
BA_ "Status" SG_ 2566864128 ExhaustGasRecircValvePosRawVolt "2.3.0";
BA_ "SPN" SG_ 2566864128 SupplyFuelPresSensRawVoltage 521525;
BA_ "Variable" SG_ 2566864128 SupplyFuelPresSensRawVoltage "Fl_uRawFuelP";
BA_ "Status" SG_ 2566864128 SupplyFuelPresSensRawVoltage "2.3.0";
BA_ "Status" SG_ 2566864128 OilPresSensRawVoltage "2.2.0";
BA_ "Variable" SG_ 2566864128 OilPresSensRawVoltage "Oil_uRawPSwmp";
BA_ "SPN" SG_ 2566864128 OilPresSensRawVoltage 521524;
BA_ "Variable" SG_ 2566864128 FuelPressureSensRawVoltage "RailP_uRaw";
BA_ "SPN" SG_ 2566864128 FuelPressureSensRawVoltage 521523;
BA_ "Status" SG_ 2566864128 FuelPressureSensRawVoltage "2.1.0";
BA_ "Variable" SG_ 2566864128 ExhaustGasBackPresSensRawVoltage "Exh_uRawPTrbnDs";
BA_ "SPN" SG_ 2566864128 ExhaustGasBackPresSensRawVoltage 521522;
BA_ "Status" SG_ 2566864128 ExhaustGasBackPresSensRawVoltage "2.4.0";
BA_ "Variable" SG_ 2566864128 BoostPressureSensRawVoltage "Air_uRawPCACDs";
BA_ "SPN" SG_ 2566864128 BoostPressureSensRawVoltage 521521;
BA_ "Status" SG_ 2566864128 BoostPressureSensRawVoltage "2.1.0";
BA_ "Variable" SG_ 2566864128 AtmosphericPresSensRawVoltage "EnvP_uRaw";
BA_ "SPN" SG_ 2566864128 AtmosphericPresSensRawVoltage 521520;
BA_ "Status" SG_ 2566864128 AtmosphericPresSensRawVoltage "2.1.0";
BA_ "Variable" SG_ 2566862848 DesiredFanSpeed "Com_nDesFanSpd";
BA_ "SPN" SG_ 2566862848 DesiredFanSpeed 522247;
BA_ "SigType" SG_ 2566862848 DesiredFanSpeed "RANGE";
BA_ "Status" SG_ 2566862848 DesiredFanSpeed "3.4.9";
BA_ "SPN" SG_ 2566862848 DesiredRelativeBoostPressure 521540;
BA_ "Variable" SG_ 2566862848 DesiredRelativeBoostPressure "Com_pDesBstPres";
BA_ "Status" SG_ 2566862848 DesiredRelativeBoostPressure "2.3.0";
BA_ "Variable" SG_ 2566862848 MainFuelInjectionPulseWidth "InjVlv_tiET_mp[3]";
BA_ "SPN" SG_ 2566862848 MainFuelInjectionPulseWidth 522248;
BA_ "Status" SG_ 2566862848 MainFuelInjectionPulseWidth "2.1.0";
BA_ "SPN" SG_ 2566862080 LambdaSensorMeasuredValue 521519;
BA_ "Status" SG_ 2566862080 LambdaSensorMeasuredValue "2.3.0";
BA_ "Variable" SG_ 2566862080 LambdaSensorMeasuredValue "LSU_rLamRec[0]";
BA_ "SPN" SG_ 2566862080 LambdaSensorTemperatureValue 521518;
BA_ "Status" SG_ 2566862080 LambdaSensorTemperatureValue "2.1.0";
BA_ "Variable" SG_ 2566862080 LambdaSensorTemperatureValue "LSU_tRi[0]";
BA_ "Status" SG_ 2566888192 RetarderInhibitEBSSwitch2Status "3.4.0";
BA_ "Variable" SG_ 2566888192 RetarderInhibitEBSSwitch2Status "EBrk_stSwtDeb[1]";
BA_ "SPN" SG_ 2566888192 RetarderInhibitEBSSwitch2Status 522260;
BA_ "SPN" SG_ 2566888192 TransferCaseSwitchStatus 522259;
BA_ "Status" SG_ 2566888192 TransferCaseSwitchStatus "3.4.0";
BA_ "Variable" SG_ 2566888192 TransferCaseSwitchStatus "TCSwt_st";
BA_ "SPN" SG_ 2566888192 AccelPedalPosn2SensorVolts 521541;
BA_ "Status" SG_ 2566888192 AccelPedalPosn2SensorVolts "2.3.0";
BA_ "Variable" SG_ 2566888192 AccelPedalPosn2SensorVolts "APP_uRaw2unLim";
BA_ "SPN" SG_ 2566888192 AirConditionerDemandStatus 522244;
BA_ "Variable" SG_ 2566888192 AirConditionerDemandStatus "AirC_stSwt";
BA_ "Status" SG_ 2566888192 AirConditionerDemandStatus "3.4.0";
BA_ "SPN" SG_ 2566888192 IntakeAirTempSensorRawVoltage 521538;
BA_ "Status" SG_ 2566888192 IntakeAirTempSensorRawVoltage "2.3.0";
BA_ "Variable" SG_ 2566888192 IntakeAirTempSensorRawVoltage "ATHEval_uRawTemp";
BA_ "Variable" SG_ 2566888192 RPSADcounts "RmtAPP_uRaw";
BA_ "Status" SG_ 2566888192 RPSADcounts "3.4.0";
BA_ "SPN" SG_ 2566888192 RPSADcounts 521517;
BA_ "SPN" SG_ 2566888192 APSADcounts 521516;
BA_ "Status" SG_ 2566888192 APSADcounts "2.3.0";
BA_ "Variable" SG_ 2566888192 APSADcounts "APP_uRaw1unLim";
BA_ "SPN" SG_ 2566888192 RetarderInhibitEBSSwitchStatus 522242;
BA_ "Variable" SG_ 2566888192 RetarderInhibitEBSSwitchStatus "EBrk_stSwtDeb[0]";
BA_ "Status" SG_ 2566888192 RetarderInhibitEBSSwitchStatus "3.4.0";
BA_ "SPN" SG_ 2566888192 ChangeOilLampStatus 522245;
BA_ "Variable" SG_ 2566888192 ChangeOilLampStatus "SLmpCtl_st";
BA_ "Status" SG_ 2566888192 ChangeOilLampStatus "2.3.0";
BA_ "SPN" SG_ 2566888192 ElectronicFanControlStatus 522246;
BA_ "Status" SG_ 2566888192 ElectronicFanControlStatus "3.4.0";
BA_ "Variable" SG_ 2566888192 ElectronicFanControlStatus "Fan_r";
BA_ "SPN" SG_ 2566888192 EngineRetarderStatus 522243;
BA_ "Variable" SG_ 2566887936 FlameStartSolenoidStatus "FlmeStrt_st";
BA_ "SigType" SG_ 2566887936 FlameStartSolenoidStatus "DISCRETE";
BA_ "SAEDocument" SG_ 2566887936 FlameStartSolenoidStatus "J1939-71";
BA_ "Variable" SG_ 2566887936 FlameStartRelayEnableStatus "GlwPlg_stOn";
BA_ "SigType" SG_ 2566887936 FlameStartRelayEnableStatus "DISCRETE";
BA_ "SAEDocument" SG_ 2566887936 FlameStartRelayEnableStatus "J1939-71";
BA_ "Variable" SG_ 2566887936 EngRunningOutputStatus "Com_stEngRun (EngSt_stEngRun)";
BA_ "SAEDocument" SG_ 2566887936 EngRunningOutputStatus "J1939-71";
BA_ "SPN" SG_ 2566887936 EngRunningOutputStatus 522262;
BA_ "SigType" SG_ 2566887936 EngRunningOutputStatus "DISCRETE";
BA_ "Status" SG_ 2566887936 EngRunningOutputStatus "3.5.0";
BA_ "SPN" SG_ 2566887936 Comp_Brake_Status_2 522250;
BA_ "Variable" SG_ 2566887936 Comp_Brake_Status_2 "ECRVlv_stActr1Out";
BA_ "Status" SG_ 2566887936 Comp_Brake_Status_2 "3.4.x";
BA_ "SPN" SG_ 2566887936 Comp_Brake_Status_1 522249;
BA_ "Variable" SG_ 2566887936 Comp_Brake_Status_1 "ECRVlv_stActr0Out";
BA_ "Status" SG_ 2566887936 Comp_Brake_Status_1 "3.4.x";
BA_ "Status" SG_ 2566887936 FanControlDutyCycle "2.2.0";
BA_ "Variable" SG_ 2566887936 FanControlDutyCycle "Fan_rPs[0]";
BA_ "SPN" SG_ 2566887936 FanControlDutyCycle 522241;
VAL_ 2566834691 FailureModeIdentifier5 31 "Not available" 19 "Received network data in error" 18 "Below normal (moderatels severe)" 17 "Below normal (least severe)" 16 "Above normal (moderately severe)" 15 "Above normal (least severe)" 14 "Special intstructions" 13 "Out of calibration" 12 "Bad intelligent device" 11 "Root cause not known" 10 "Abnormal rate of change" 9 "Abnormal update rate" 8 "Abnormal frequency" 7 "Mechanical system not responding" 6 "Current above normal" 5 "Current below normal" 4 "Voltage below normal" 3 "Voltage above normal" 2 "Data erratic" 1 "Below normal (most severe)" 0 "Above normal (most severe)" ;
VAL_ 2566834691 FailureModeIdentifier4 31 "Not available" 19 "Received network data in error" 18 "Below normal (moderatels severe)" 17 "Below normal (least severe)" 16 "Above normal (moderately severe)" 15 "Above normal (least severe)" 14 "Special intstructions" 13 "Out of calibration" 12 "Bad intelligent device" 11 "Root cause not known" 10 "Abnormal rate of change" 9 "Abnormal update rate" 8 "Abnormal frequency" 7 "Mechanical system not responding" 6 "Current above normal" 5 "Current below normal" 4 "Voltage below normal" 3 "Voltage above normal" 2 "Data erratic" 1 "Below normal (most severe)" 0 "Above normal (most severe)" ;
VAL_ 2566834691 FailureModeIdentifier3 31 "Not available" 19 "Received network data in error" 18 "Below normal (moderatels severe)" 17 "Below normal (least severe)" 16 "Above normal (moderately severe)" 15 "Above normal (least severe)" 14 "Special intstructions" 13 "Out of calibration" 12 "Bad intelligent device" 11 "Root cause not known" 10 "Abnormal rate of change" 9 "Abnormal update rate" 8 "Abnormal frequency" 7 "Mechanical system not responding" 6 "Current above normal" 5 "Current below normal" 4 "Voltage below normal" 3 "Voltage above normal" 2 "Data erratic" 1 "Below normal (most severe)" 0 "Above normal (most severe)" ;
VAL_ 2566834691 FailureModeIdentifier2 31 "Not available" 19 "Received network data in error" 18 "Below normal (moderatels severe)" 17 "Below normal (least severe)" 16 "Above normal (moderately severe)" 15 "Above normal (least severe)" 14 "Special intstructions" 13 "Out of calibration" 12 "Bad intelligent device" 11 "Root cause not known" 10 "Abnormal rate of change" 9 "Abnormal update rate" 8 "Abnormal frequency" 7 "Mechanical system not responding" 6 "Current above normal" 5 "Current below normal" 4 "Voltage below normal" 3 "Voltage above normal" 2 "Data erratic" 1 "Below normal (most severe)" 0 "Above normal (most severe)" ;
VAL_ 2566834691 FailureModeIdentifier1 31 "Not available" 19 "Received network data in error" 18 "Below normal (moderatels severe)" 17 "Below normal (least severe)" 16 "Above normal (moderately severe)" 15 "Above normal (least severe)" 14 "Special intstructions" 13 "Out of calibration" 12 "Bad intelligent device" 11 "Root cause not known" 10 "Abnormal rate of change" 9 "Abnormal update rate" 8 "Abnormal frequency" 7 "Mechanical system not responding" 6 "Current above normal" 5 "Current below normal" 4 "Voltage below normal" 3 "Voltage above normal" 2 "Data erratic" 1 "Below normal (most severe)" 0 "Above normal (most severe)" ;
VAL_ 2566834691 RedStopLampStatus 3 "Not available" 2 "Reserved" 1 "Lamp on" 0 "Lamp off" ;
VAL_ 2566834691 ProtectLampStatus 3 "Not available" 2 "Reserved" 1 "Lamp on" 0 "Lamp off" ;
VAL_ 2566834691 AmberWarningLampStatus 3 "Not available" 2 "Reserved" 1 "Lamp on" 0 "Lamp off" ;
VAL_ 2566834691 MalfunctionIndicatorLampStatus 3 "Not available" 2 "Reserved" 1 "Lamp on" 0 "Lamp off" ;
VAL_ 2566834691 FlashRedStopLamp 3 "Unavailable / Do Not Flash" 2 "Reserved" 1 "Fast Flash" 0 "Slow Flash" ;
VAL_ 2566834691 FlashProtectLamp 3 "Unavailable / Do Not Flash" 2 "Reserved" 1 "Fast Flash" 0 "Slow Flash" ;
VAL_ 2566834691 FlashMalfuncIndicatorLamp 3 "Unavailable / Do Not Flash" 2 "Reserved" 1 "Fast Flash" 0 "Slow Flash" ;
VAL_ 2566834691 FlashAmberWarningLamp 3 "Unavailable / Do Not Flash" 2 "Reserved" 1 "Fast Flash" 0 "Slow Flash" ;
VAL_ 2566834711 FailureModeIdentifier5 31 "Not available" 19 "Received network data in error" 18 "Below normal (moderatels severe)" 17 "Below normal (least severe)" 16 "Above normal (moderately severe)" 15 "Above normal (least severe)" 14 "Special intstructions" 13 "Out of calibration" 12 "Bad intelligent device" 11 "Root cause not known" 10 "Abnormal rate of change" 9 "Abnormal update rate" 8 "Abnormal frequency" 7 "Mechanical system not responding" 6 "Current above normal" 5 "Current below normal" 4 "Voltage below normal" 3 "Voltage above normal" 2 "Data erratic" 1 "Below normal (most severe)" 0 "Above normal (most severe)" ;
VAL_ 2566834711 FailureModeIdentifier4 31 "Not available" 19 "Received network data in error" 18 "Below normal (moderatels severe)" 17 "Below normal (least severe)" 16 "Above normal (moderately severe)" 15 "Above normal (least severe)" 14 "Special intstructions" 13 "Out of calibration" 12 "Bad intelligent device" 11 "Root cause not known" 10 "Abnormal rate of change" 9 "Abnormal update rate" 8 "Abnormal frequency" 7 "Mechanical system not responding" 6 "Current above normal" 5 "Current below normal" 4 "Voltage below normal" 3 "Voltage above normal" 2 "Data erratic" 1 "Below normal (most severe)" 0 "Above normal (most severe)" ;
VAL_ 2566834711 FailureModeIdentifier3 31 "Not available" 19 "Received network data in error" 18 "Below normal (moderatels severe)" 17 "Below normal (least severe)" 16 "Above normal (moderately severe)" 15 "Above normal (least severe)" 14 "Special intstructions" 13 "Out of calibration" 12 "Bad intelligent device" 11 "Root cause not known" 10 "Abnormal rate of change" 9 "Abnormal update rate" 8 "Abnormal frequency" 7 "Mechanical system not responding" 6 "Current above normal" 5 "Current below normal" 4 "Voltage below normal" 3 "Voltage above normal" 2 "Data erratic" 1 "Below normal (most severe)" 0 "Above normal (most severe)" ;
VAL_ 2566834711 FailureModeIdentifier2 31 "Not available" 19 "Received network data in error" 18 "Below normal (moderatels severe)" 17 "Below normal (least severe)" 16 "Above normal (moderately severe)" 15 "Above normal (least severe)" 14 "Special intstructions" 13 "Out of calibration" 12 "Bad intelligent device" 11 "Root cause not known" 10 "Abnormal rate of change" 9 "Abnormal update rate" 8 "Abnormal frequency" 7 "Mechanical system not responding" 6 "Current above normal" 5 "Current below normal" 4 "Voltage below normal" 3 "Voltage above normal" 2 "Data erratic" 1 "Below normal (most severe)" 0 "Above normal (most severe)" ;
VAL_ 2566834711 FailureModeIdentifier1 31 "Not available" 19 "Received network data in error" 18 "Below normal (moderatels severe)" 17 "Below normal (least severe)" 16 "Above normal (moderately severe)" 15 "Above normal (least severe)" 14 "Special intstructions" 13 "Out of calibration" 12 "Bad intelligent device" 11 "Root cause not known" 10 "Abnormal rate of change" 9 "Abnormal update rate" 8 "Abnormal frequency" 7 "Mechanical system not responding" 6 "Current above normal" 5 "Current below normal" 4 "Voltage below normal" 3 "Voltage above normal" 2 "Data erratic" 1 "Below normal (most severe)" 0 "Above normal (most severe)" ;
VAL_ 2566834711 RedStopLampStatus 3 "Not available" 2 "Reserved" 1 "Lamp on" 0 "Lamp off" ;
VAL_ 2566834711 ProtectLampStatus 3 "Not available" 2 "Reserved" 1 "Lamp on" 0 "Lamp off" ;
VAL_ 2566834711 AmberWarningLampStatus 3 "Not available" 2 "Reserved" 1 "Lamp on" 0 "Lamp off" ;
VAL_ 2566834711 MalfunctionIndicatorLampStatus 3 "Not available" 2 "Reserved" 1 "Lamp on" 0 "Lamp off" ;
VAL_ 2566834711 FlashRedStopLamp 3 "Unavailable / Do Not Flash" 2 "Reserved" 1 "Fast Flash" 0 "Slow Flash" ;
VAL_ 2566834711 FlashProtectLamp 3 "Unavailable / Do Not Flash" 2 "Reserved" 1 "Fast Flash" 0 "Slow Flash" ;
VAL_ 2566834711 FlashMalfuncIndicatorLamp 3 "Unavailable / Do Not Flash" 2 "Reserved" 1 "Fast Flash" 0 "Slow Flash" ;
VAL_ 2566834711 FlashAmberWarningLamp 3 "Unavailable / Do Not Flash" 2 "Reserved" 1 "Fast Flash" 0 "Slow Flash" ;
VAL_ 2564816640 HoldSignal 15 "Not available" 1 "Devices whose broadcast state ha" 0 "All devices" ;
VAL_ 2564816640 J1939Network3 3 "Don't care" 2 "Reserved" 1 "Start broadcast" 0 "Stop broadcast" ;
VAL_ 2564816640 J1939Network2 3 "Don't care" 2 "Reserved" 1 "Start broadcast" 0 "Stop broadcast" ;
VAL_ 2564816640 ISO9141 3 "Don't care" 2 "Reserved" 1 "Start broadcast" 0 "Stop broadcast" ;
VAL_ 2564816640 SAE_J1850 3 "Don't care" 2 "Reserved" 1 "Start broadcast" 0 "Stop broadcast" ;
VAL_ 2564816640 ManufacturerSpecificPort 3 "Don't care" 2 "Reserved" 1 "Start broadcast" 0 "Stop broadcast" ;
VAL_ 2564816640 CurrentDataLink 3 "Don't care" 2 "Reserved" 1 "Start broadcast" 0 "Stop broadcast" ;
VAL_ 2564816640 SAE_J1587 3 "Don't care" 2 "Reserved" 1 "Start broadcast" 0 "Stop broadcast" ;
VAL_ 2564816640 SAE_J1922 3 "Don't care" 2 "Reserved" 1 "Start broadcast" 0 "Stop broadcast" ;
VAL_ 2564816640 J1939Network1 3 "Don't care" 2 "Reserved" 1 "Start broadcast" 0 "Stop broadcast" ;
VAL_ 2564816640 SuspendSignal 15 "NotAvailable" 14 "ResumingNormalBroadcastPattern" 3 "TemporarySuspensionOfSomeMessage" 2 "TemporarySuspensionOfAllBroadcas" 1 "IndefiniteSuspensionOfSomeMessag" 0 "IndefiniteSuspensionOfAllBroadca" ;
VAL_ 2566844705 EngIdleIncrementSwitch 3 "NotAvailable" 2 "Error" 1 "On" 0 "Off" ;
VAL_ 2566844705 EngIdleDecrementSwitch 3 "NotAvailable" 2 "Error" 1 "On" 0 "Off" ;
VAL_ 2566844705 EngShutdownOverrideSwitch 3 "NotAvailable" 2 "Error" 1 "On" 0 "Off" ;
VAL_ 2566844705 EngTestModeSwitch 3 "NotAvailable" 2 "Error" 1 "On" 0 "Off" ;
VAL_ 2566844705 CruiseCtrlAccelerateSwitch 3 "NotAvailable" 2 "Error" 1 "CrsCtrlActivatorInPosAccelerate" 0 "CrsCtrlActvtrNotInPosAccelerate" ;
VAL_ 2566844705 CruiseCtrlResumeSwitch 3 "NotAvailable" 2 "Error" 1 "CruiseCtrlActivatorInPosResume" 0 "CrseCtrlActivatorNotInPosResume" ;
VAL_ 2566844705 CruiseCtrlCoastSwitch 3 "NotAvailable" 2 "Error" 1 "CruiseCtrlActivatorInPosCoast" 0 "CriseCtrlActivatorNotInPosCoast" ;
VAL_ 2566844705 CruiseCtrlSetSwitch 3 "NotAvailable" 2 "Error" 1 "CruiseCtrlActivatorInPosSet" 0 "CruiseCtrlActivatorNotInPosSet" ;
VAL_ 2566844705 ClutchSwitch 3 "NotAvailable" 2 "Error" 1 "ClutchPedalDepressed" 0 "ClutchPedalReleased" ;
VAL_ 2566844705 BrakeSwitch 3 "NotAvailable" 2 "Error" 1 "BrakePedalDepressed" 0 "BrakePedalReleased" ;
VAL_ 2566844705 CruiseCtrlEnableSwitch 3 "NotAvailable" 2 "Error" 1 "CruiseCtrlEnabled" 0 "CruiseCtrlDisabled" ;
VAL_ 2566844705 CruiseCtrlActive 3 "NotAvailable" 2 "Error" 1 "CruiseCtrlSwitchedOn" 0 "CruiseCtrlSwitchedOff" ;
VAL_ 2566844705 CruiseCtrlPauseSwitch 3 "TakeNoAction" 2 "ErrorIndicator" 1 "On" 0 "Off" ;
VAL_ 2566844705 ParkingBrakeSwitch 3 "NotAvailable" 2 "Error" 1 "ParkingBrakeSet" 0 "ParkingBrakeNotSet" ;
VAL_ 2566844705 TwoSpeedAxleSwitch 3 "NotAvailable" 2 "Error" 1 "HighSpeedRange" 0 "LowSpeedRange" ;
VAL_ 2565347072 ControlByte 24 "EAbort" 23 "EEoMACK" 22 "EDPO" 21 "ECTS" 20 "ERTS" 3 "CannotRespond" 2 "AccessDenied" 1 "NACK" 0 "ACK" 255 "Abort" 32 "BAM" 19 "EoMA" 17 "CTS" 16 "RTS" ;
VAL_ 2566750208 FailureModeIdentifier5 31 "Not available" 19 "Received network data in error" 18 "Below normal (moderatels severe)" 17 "Below normal (least severe)" 16 "Above normal (moderately severe)" 15 "Above normal (least severe)" 14 "Special intstructions" 13 "Out of calibration" 12 "Bad intelligent device" 11 "Root cause not known" 10 "Abnormal rate of change" 9 "Abnormal update rate" 8 "Abnormal frequency" 7 "Mechanical system not responding" 6 "Current above normal" 5 "Current below normal" 4 "Voltage below normal" 3 "Voltage above normal" 2 "Data erratic" 1 "Below normal (most severe)" 0 "Above normal (most severe)" ;
VAL_ 2566750208 FailureModeIdentifier4 31 "Not available" 19 "Received network data in error" 18 "Below normal (moderatels severe)" 17 "Below normal (least severe)" 16 "Above normal (moderately severe)" 15 "Above normal (least severe)" 14 "Special intstructions" 13 "Out of calibration" 12 "Bad intelligent device" 11 "Root cause not known" 10 "Abnormal rate of change" 9 "Abnormal update rate" 8 "Abnormal frequency" 7 "Mechanical system not responding" 6 "Current above normal" 5 "Current below normal" 4 "Voltage below normal" 3 "Voltage above normal" 2 "Data erratic" 1 "Below normal (most severe)" 0 "Above normal (most severe)" ;
VAL_ 2566750208 FailureModeIdentifier3 31 "Not available" 19 "Received network data in error" 18 "Below normal (moderatels severe)" 17 "Below normal (least severe)" 16 "Above normal (moderately severe)" 15 "Above normal (least severe)" 14 "Special intstructions" 13 "Out of calibration" 12 "Bad intelligent device" 11 "Root cause not known" 10 "Abnormal rate of change" 9 "Abnormal update rate" 8 "Abnormal frequency" 7 "Mechanical system not responding" 6 "Current above normal" 5 "Current below normal" 4 "Voltage below normal" 3 "Voltage above normal" 2 "Data erratic" 1 "Below normal (most severe)" 0 "Above normal (most severe)" ;
VAL_ 2566750208 FailureModeIdentifier2 31 "Not available" 19 "Received network data in error" 18 "Below normal (moderatels severe)" 17 "Below normal (least severe)" 16 "Above normal (moderately severe)" 15 "Above normal (least severe)" 14 "Special intstructions" 13 "Out of calibration" 12 "Bad intelligent device" 11 "Root cause not known" 10 "Abnormal rate of change" 9 "Abnormal update rate" 8 "Abnormal frequency" 7 "Mechanical system not responding" 6 "Current above normal" 5 "Current below normal" 4 "Voltage below normal" 3 "Voltage above normal" 2 "Data erratic" 1 "Below normal (most severe)" 0 "Above normal (most severe)" ;
VAL_ 2566750208 FailureModeIdentifier1 31 "Not available" 19 "Received network data in error" 18 "Below normal (moderatels severe)" 17 "Below normal (least severe)" 16 "Above normal (moderately severe)" 15 "Above normal (least severe)" 14 "Special intstructions" 13 "Out of calibration" 12 "Bad intelligent device" 11 "Root cause not known" 10 "Abnormal rate of change" 9 "Abnormal update rate" 8 "Abnormal frequency" 7 "Mechanical system not responding" 6 "Current above normal" 5 "Current below normal" 4 "Voltage below normal" 3 "Voltage above normal" 2 "Data erratic" 1 "Below normal (most severe)" 0 "Above normal (most severe)" ;
VAL_ 2566750208 FlashRedStopLamp 3 "Unavailable / Do Not Flash" 2 "Reserved" 1 "Fast Flash" 0 "Slow Flash" ;
VAL_ 2566750208 FlashProtectLamp 3 "Unavailable / Do Not Flash" 2 "Reserved" 1 "Fast Flash" 0 "Slow Flash" ;
VAL_ 2566750208 FlashMalfuncIndicatorLamp 3 "Unavailable / Do Not Flash" 2 "Reserved" 1 "Fast Flash" 0 "Slow Flash" ;
VAL_ 2566750208 FlashAmberWarningLamp 3 "Unavailable / Do Not Flash" 2 "Reserved" 1 "Fast Flash" 0 "Slow Flash" ;
VAL_ 2566750208 RedStopLampStatus 3 "Not available" 2 "Reserved" 1 "Lamp on" 0 "Lamp off" ;
VAL_ 2566750208 ProtectLampStatus 3 "Not available" 2 "Reserved" 1 "Lamp on" 0 "Lamp off" ;
VAL_ 2566750208 AmberWarningLampStatus 3 "Not available" 2 "Reserved" 1 "Lamp on" 0 "Lamp off" ;
VAL_ 2566750208 MalfunctionIndicatorLampStatus 3 "Not available" 2 "Reserved" 1 "Lamp on" 0 "Lamp off" ;
VAL_ 2566750720 FailureModeIdentifier5 31 "Not available" 19 "Received network data in error" 18 "Below normal (moderatels severe)" 17 "Below normal (least severe)" 16 "Above normal (moderately severe)" 15 "Above normal (least severe)" 14 "Special intstructions" 13 "Out of calibration" 12 "Bad intelligent device" 11 "Root cause not known" 10 "Abnormal rate of change" 9 "Abnormal update rate" 8 "Abnormal frequency" 7 "Mechanical system not responding" 6 "Current above normal" 5 "Current below normal" 4 "Voltage below normal" 3 "Voltage above normal" 2 "Data erratic" 1 "Below normal (most severe)" 0 "Above normal (most severe)" ;
VAL_ 2566750720 FailureModeIdentifier4 31 "Not available" 19 "Received network data in error" 18 "Below normal (moderatels severe)" 17 "Below normal (least severe)" 16 "Above normal (moderately severe)" 15 "Above normal (least severe)" 14 "Special intstructions" 13 "Out of calibration" 12 "Bad intelligent device" 11 "Root cause not known" 10 "Abnormal rate of change" 9 "Abnormal update rate" 8 "Abnormal frequency" 7 "Mechanical system not responding" 6 "Current above normal" 5 "Current below normal" 4 "Voltage below normal" 3 "Voltage above normal" 2 "Data erratic" 1 "Below normal (most severe)" 0 "Above normal (most severe)" ;
VAL_ 2566750720 FailureModeIdentifier3 31 "Not available" 19 "Received network data in error" 18 "Below normal (moderatels severe)" 17 "Below normal (least severe)" 16 "Above normal (moderately severe)" 15 "Above normal (least severe)" 14 "Special intstructions" 13 "Out of calibration" 12 "Bad intelligent device" 11 "Root cause not known" 10 "Abnormal rate of change" 9 "Abnormal update rate" 8 "Abnormal frequency" 7 "Mechanical system not responding" 6 "Current above normal" 5 "Current below normal" 4 "Voltage below normal" 3 "Voltage above normal" 2 "Data erratic" 1 "Below normal (most severe)" 0 "Above normal (most severe)" ;
VAL_ 2566750720 FailureModeIdentifier2 31 "Not available" 19 "Received network data in error" 18 "Below normal (moderatels severe)" 17 "Below normal (least severe)" 16 "Above normal (moderately severe)" 15 "Above normal (least severe)" 14 "Special intstructions" 13 "Out of calibration" 12 "Bad intelligent device" 11 "Root cause not known" 10 "Abnormal rate of change" 9 "Abnormal update rate" 8 "Abnormal frequency" 7 "Mechanical system not responding" 6 "Current above normal" 5 "Current below normal" 4 "Voltage below normal" 3 "Voltage above normal" 2 "Data erratic" 1 "Below normal (most severe)" 0 "Above normal (most severe)" ;
VAL_ 2566750720 FailureModeIdentifier1 31 "Not available" 19 "Received network data in error" 18 "Below normal (moderatels severe)" 17 "Below normal (least severe)" 16 "Above normal (moderately severe)" 15 "Above normal (least severe)" 14 "Special intstructions" 13 "Out of calibration" 12 "Bad intelligent device" 11 "Root cause not known" 10 "Abnormal rate of change" 9 "Abnormal update rate" 8 "Abnormal frequency" 7 "Mechanical system not responding" 6 "Current above normal" 5 "Current below normal" 4 "Voltage below normal" 3 "Voltage above normal" 2 "Data erratic" 1 "Below normal (most severe)" 0 "Above normal (most severe)" ;
VAL_ 2566750720 FlashRedStopLamp 3 "Unavailable / Do Not Flash" 2 "Reserved" 1 "Fast Flash" 0 "Slow Flash" ;
VAL_ 2566750720 FlashProtectLamp 3 "Unavailable / Do Not Flash" 2 "Reserved" 1 "Fast Flash" 0 "Slow Flash" ;
VAL_ 2566750720 FlashMalfuncIndicatorLamp 3 "Unavailable / Do Not Flash" 2 "Reserved" 1 "Fast Flash" 0 "Slow Flash" ;
VAL_ 2566750720 FlashAmberWarningLamp 3 "Unavailable / Do Not Flash" 2 "Reserved" 1 "Fast Flash" 0 "Slow Flash" ;
VAL_ 2566750720 RedStopLampStatus 3 "Not available" 2 "Reserved" 1 "Lamp on" 0 "Lamp off" ;
VAL_ 2566750720 ProtectLampStatus 3 "Not available" 2 "Reserved" 1 "Lamp on" 0 "Lamp off" ;
VAL_ 2566750720 AmberWarningLampStatus 3 "Not available" 2 "Reserved" 1 "Lamp on" 0 "Lamp off" ;
VAL_ 2566750720 MalfunctionIndicatorLampStatus 3 "Not available" 2 "Reserved" 1 "Lamp on" 0 "Lamp off" ;
VAL_ 2565869056 Aftertreatment1IntSensHtrCtl 3 "Heater off" 2 "Preheat 1" 1 "Preheat 2" 0 "Automatic" ;
VAL_ 2566888192 RetarderInhibitEBSSwitch2Status 3 "Not available" 2 "Error" 1 "Active" 0 "Inactive" ;
VAL_ 2566888192 TransferCaseSwitchStatus 3 "Not available" 2 "Reserved" 1 "On" 0 "Off" ;
VAL_ 2566888192 AirConditionerDemandStatus 3 "not available" 2 "error" 1 "active" 0 "inactive" ;
VAL_ 2566888192 RetarderInhibitEBSSwitchStatus 3 "Not available" 2 "Error" 1 "Active" 0 "Inactive" ;
VAL_ 2566888192 ChangeOilLampStatus 3 "not available" 2 "error" 1 "active" 0 "inactive" ;
VAL_ 2566888192 ElectronicFanControlStatus 3 "not available" 2 "error" 1 "active" 0 "inactive" ;
VAL_ 2566888192 EngineRetarderStatus 2 "Exhaust Pressure Control" 1 "Torque Control" 0 "Brake Disabled" ;
VAL_ 2566887936 Comp_Brake_Status_2 3 "Not Available" 2 "Reserved" 1 "On" 0 "Off" ;
VAL_ 2566887936 Comp_Brake_Status_1 3 "Not Available" 2 "Reserved" 1 "On" 0 "Off" ;
VAL_ 2566888448 VEH_MOD_10 122 "z" 121 "y" 120 "x" 119 "w" 118 "v" 117 "u" 116 "t" 115 "s" 114 "r" 113 "q" 112 "p" 111 "o" 110 "n" 109 "m" 108 "l" 107 "k" 106 "j" 105 "i" 104 "h" 103 "g" 102 "f" 101 "e" 100 "d" 99 "c" 98 "b" 97 "a" 42 "*" 90 "Z" 89 "Y" 88 "X" 87 "W" 86 "V" 85 "U" 84 "T" 83 "S" 82 "R" 81 "Q" 80 "P" 79 "O" 78 "N" 77 "M" 76 "L" 75 "K" 74 "J" 73 "I" 72 "H" 71 "G" 70 "F" 69 "E" 68 "D" 67 "C" 66 "B" 65 "A" 57 "9" 56 "8" 55 "7" 54 "6" 53 "5" 52 "4" 51 "3" 50 "2" 49 "1" 48 "0" ;
VAL_ 2566888448 VEH_MOD_09 122 "z" 121 "y" 120 "x" 119 "w" 118 "v" 117 "u" 116 "t" 115 "s" 114 "r" 113 "q" 112 "p" 111 "o" 110 "n" 109 "m" 108 "l" 107 "k" 106 "j" 105 "i" 104 "h" 103 "g" 102 "f" 101 "e" 100 "d" 99 "c" 98 "b" 97 "a" 42 "*" 90 "Z" 89 "Y" 88 "X" 87 "W" 86 "V" 85 "U" 84 "T" 83 "S" 82 "R" 81 "Q" 80 "P" 79 "O" 78 "N" 77 "M" 76 "L" 75 "K" 74 "J" 73 "I" 72 "H" 71 "G" 70 "F" 69 "E" 68 "D" 67 "C" 66 "B" 65 "A" 57 "9" 56 "8" 55 "7" 54 "6" 53 "5" 52 "4" 51 "3" 50 "2" 49 "1" 48 "0" ;
VAL_ 2566888448 VEH_MOD_08 122 "z" 121 "y" 120 "x" 119 "w" 118 "v" 117 "u" 116 "t" 115 "s" 114 "r" 113 "q" 112 "p" 111 "o" 110 "n" 109 "m" 108 "l" 107 "k" 106 "j" 105 "i" 104 "h" 103 "g" 102 "f" 101 "e" 100 "d" 99 "c" 98 "b" 97 "a" 42 "*" 90 "Z" 89 "Y" 88 "X" 87 "W" 86 "V" 85 "U" 84 "T" 83 "S" 82 "R" 81 "Q" 80 "P" 79 "O" 78 "N" 77 "M" 76 "L" 75 "K" 74 "J" 73 "I" 72 "H" 71 "G" 70 "F" 69 "E" 68 "D" 67 "C" 66 "B" 65 "A" 57 "9" 56 "8" 55 "7" 54 "6" 53 "5" 52 "4" 51 "3" 50 "2" 49 "1" 48 "0" ;
VAL_ 2566888448 VEH_MOD_07 122 "z" 121 "y" 120 "x" 119 "w" 118 "v" 117 "u" 116 "t" 115 "s" 114 "r" 113 "q" 112 "p" 111 "o" 110 "n" 109 "m" 108 "l" 107 "k" 106 "j" 105 "i" 104 "h" 103 "g" 102 "f" 101 "e" 100 "d" 99 "c" 98 "b" 97 "a" 42 "*" 90 "Z" 89 "Y" 88 "X" 87 "W" 86 "V" 85 "U" 84 "T" 83 "S" 82 "R" 81 "Q" 80 "P" 79 "O" 78 "N" 77 "M" 76 "L" 75 "K" 74 "J" 73 "I" 72 "H" 71 "G" 70 "F" 69 "E" 68 "D" 67 "C" 66 "B" 65 "A" 57 "9" 56 "8" 55 "7" 54 "6" 53 "5" 52 "4" 51 "3" 50 "2" 49 "1" 48 "0" ;
VAL_ 2566888448 VEH_MOD_06 122 "z" 121 "y" 120 "x" 119 "w" 118 "v" 117 "u" 116 "t" 115 "s" 114 "r" 113 "q" 112 "p" 111 "o" 110 "n" 109 "m" 108 "l" 107 "k" 106 "j" 105 "i" 104 "h" 103 "g" 102 "f" 101 "e" 100 "d" 99 "c" 98 "b" 97 "a" 42 "*" 90 "Z" 89 "Y" 88 "X" 87 "W" 86 "V" 85 "U" 84 "T" 83 "S" 82 "R" 81 "Q" 80 "P" 79 "O" 78 "N" 77 "M" 76 "L" 75 "K" 74 "J" 73 "I" 72 "H" 71 "G" 70 "F" 69 "E" 68 "D" 67 "C" 66 "B" 65 "A" 57 "9" 56 "8" 55 "7" 54 "6" 53 "5" 52 "4" 51 "3" 50 "2" 49 "1" 48 "0" ;
VAL_ 2566888448 VEH_MOD_05 122 "z" 121 "y" 120 "x" 119 "w" 118 "v" 117 "u" 116 "t" 115 "s" 114 "r" 113 "q" 112 "p" 111 "o" 110 "n" 109 "m" 108 "l" 107 "k" 106 "j" 105 "i" 104 "h" 103 "g" 102 "f" 101 "e" 100 "d" 99 "c" 98 "b" 97 "a" 42 "*" 90 "Z" 89 "Y" 88 "X" 87 "W" 86 "V" 85 "U" 84 "T" 83 "S" 82 "R" 81 "Q" 80 "P" 79 "O" 78 "N" 77 "M" 76 "L" 75 "K" 74 "J" 73 "I" 72 "H" 71 "G" 70 "F" 69 "E" 68 "D" 67 "C" 66 "B" 65 "A" 57 "9" 56 "8" 55 "7" 54 "6" 53 "5" 52 "4" 51 "3" 50 "2" 49 "1" 48 "0" ;
VAL_ 2566888448 VEH_MOD_04 122 "z" 121 "y" 120 "x" 119 "w" 118 "v" 117 "u" 116 "t" 115 "s" 114 "r" 113 "q" 112 "p" 111 "o" 110 "n" 109 "m" 108 "l" 107 "k" 106 "j" 105 "i" 104 "h" 103 "g" 102 "f" 101 "e" 100 "d" 99 "c" 98 "b" 97 "a" 42 "*" 90 "Z" 89 "Y" 88 "X" 87 "W" 86 "V" 85 "U" 84 "T" 83 "S" 82 "R" 81 "Q" 80 "P" 79 "O" 78 "N" 77 "M" 76 "L" 75 "K" 74 "J" 73 "I" 72 "H" 71 "G" 70 "F" 69 "E" 68 "D" 67 "C" 66 "B" 65 "A" 57 "9" 56 "8" 55 "7" 54 "6" 53 "5" 52 "4" 51 "3" 50 "2" 49 "1" 48 "0" ;
VAL_ 2566888448 VEH_MOD_03 122 "z" 121 "y" 120 "x" 119 "w" 118 "v" 117 "u" 116 "t" 115 "s" 114 "r" 113 "q" 112 "p" 111 "o" 110 "n" 109 "m" 108 "l" 107 "k" 106 "j" 105 "i" 104 "h" 103 "g" 102 "f" 101 "e" 100 "d" 99 "c" 98 "b" 97 "a" 42 "*" 90 "Z" 89 "Y" 88 "X" 87 "W" 86 "V" 85 "U" 84 "T" 83 "S" 82 "R" 81 "Q" 80 "P" 79 "O" 78 "N" 77 "M" 76 "L" 75 "K" 74 "J" 73 "I" 72 "H" 71 "G" 70 "F" 69 "E" 68 "D" 67 "C" 66 "B" 65 "A" 57 "9" 56 "8" 55 "7" 54 "6" 53 "5" 52 "4" 51 "3" 50 "2" 49 "1" 48 "0" ;
VAL_ 2566888448 VEH_MOD_02 122 "z" 121 "y" 120 "x" 119 "w" 118 "v" 117 "u" 116 "t" 115 "s" 114 "r" 113 "q" 112 "p" 111 "o" 110 "n" 109 "m" 108 "l" 107 "k" 106 "j" 105 "i" 104 "h" 103 "g" 102 "f" 101 "e" 100 "d" 99 "c" 98 "b" 97 "a" 42 "*" 90 "Z" 89 "Y" 88 "X" 87 "W" 86 "V" 85 "U" 84 "T" 83 "S" 82 "R" 81 "Q" 80 "P" 79 "O" 78 "N" 77 "M" 76 "L" 75 "K" 74 "J" 73 "I" 72 "H" 71 "G" 70 "F" 69 "E" 68 "D" 67 "C" 66 "B" 65 "A" 57 "9" 56 "8" 55 "7" 54 "6" 53 "5" 52 "4" 51 "3" 50 "2" 49 "1" 48 "0" ;
VAL_ 2566888448 VEH_MOD_01 122 "z" 121 "y" 120 "x" 119 "w" 118 "v" 117 "u" 116 "t" 115 "s" 114 "r" 113 "q" 112 "p" 111 "o" 110 "n" 109 "m" 108 "l" 107 "k" 106 "j" 105 "i" 104 "h" 103 "g" 102 "f" 101 "e" 100 "d" 99 "c" 98 "b" 97 "a" 42 "*" 90 "Z" 89 "Y" 88 "X" 87 "W" 86 "V" 85 "U" 84 "T" 83 "S" 82 "R" 81 "Q" 80 "P" 79 "O" 78 "N" 77 "M" 76 "L" 75 "K" 74 "J" 73 "I" 72 "H" 71 "G" 70 "F" 69 "E" 68 "D" 67 "C" 66 "B" 65 "A" 57 "9" 56 "8" 55 "7" 54 "6" 53 "5" 52 "4" 51 "3" 50 "2" 49 "1" 48 "0" ;
VAL_ 2566888448 ENG_TYPE_ID_20 122 "z" 121 "y" 120 "x" 119 "w" 118 "v" 117 "u" 116 "t" 115 "s" 114 "r" 113 "q" 112 "p" 111 "o" 110 "n" 109 "m" 108 "l" 107 "k" 106 "j" 105 "i" 104 "h" 103 "g" 102 "f" 101 "e" 100 "d" 99 "c" 98 "b" 97 "a" 42 "*" 90 "Z" 89 "Y" 88 "X" 87 "W" 86 "V" 85 "U" 84 "T" 83 "S" 82 "R" 81 "Q" 80 "P" 79 "O" 78 "N" 77 "M" 76 "L" 75 "K" 74 "J" 73 "I" 72 "H" 71 "G" 70 "F" 69 "E" 68 "D" 67 "C" 66 "B" 65 "A" 57 "9" 56 "8" 55 "7" 54 "6" 53 "5" 52 "4" 51 "3" 50 "2" 49 "1" 48 "0" ;
VAL_ 2566888448 ENG_TYPE_ID_19 122 "z" 121 "y" 120 "x" 119 "w" 118 "v" 117 "u" 116 "t" 115 "s" 114 "r" 113 "q" 112 "p" 111 "o" 110 "n" 109 "m" 108 "l" 107 "k" 106 "j" 105 "i" 104 "h" 103 "g" 102 "f" 101 "e" 100 "d" 99 "c" 98 "b" 97 "a" 42 "*" 90 "Z" 89 "Y" 88 "X" 87 "W" 86 "V" 85 "U" 84 "T" 83 "S" 82 "R" 81 "Q" 80 "P" 79 "O" 78 "N" 77 "M" 76 "L" 75 "K" 74 "J" 73 "I" 72 "H" 71 "G" 70 "F" 69 "E" 68 "D" 67 "C" 66 "B" 65 "A" 57 "9" 56 "8" 55 "7" 54 "6" 53 "5" 52 "4" 51 "3" 50 "2" 49 "1" 48 "0" ;
VAL_ 2566888448 ENG_TYPE_ID_18 122 "z" 121 "y" 120 "x" 119 "w" 118 "v" 117 "u" 116 "t" 115 "s" 114 "r" 113 "q" 112 "p" 111 "o" 110 "n" 109 "m" 108 "l" 107 "k" 106 "j" 105 "i" 104 "h" 103 "g" 102 "f" 101 "e" 100 "d" 99 "c" 98 "b" 97 "a" 42 "*" 90 "Z" 89 "Y" 88 "X" 87 "W" 86 "V" 85 "U" 84 "T" 83 "S" 82 "R" 81 "Q" 80 "P" 79 "O" 78 "N" 77 "M" 76 "L" 75 "K" 74 "J" 73 "I" 72 "H" 71 "G" 70 "F" 69 "E" 68 "D" 67 "C" 66 "B" 65 "A" 57 "9" 56 "8" 55 "7" 54 "6" 53 "5" 52 "4" 51 "3" 50 "2" 49 "1" 48 "0" ;
VAL_ 2566888448 ENG_TYPE_ID_17 122 "z" 121 "y" 120 "x" 119 "w" 118 "v" 117 "u" 116 "t" 115 "s" 114 "r" 113 "q" 112 "p" 111 "o" 110 "n" 109 "m" 108 "l" 107 "k" 106 "j" 105 "i" 104 "h" 103 "g" 102 "f" 101 "e" 100 "d" 99 "c" 98 "b" 97 "a" 42 "*" 90 "Z" 89 "Y" 88 "X" 87 "W" 86 "V" 85 "U" 84 "T" 83 "S" 82 "R" 81 "Q" 80 "P" 79 "O" 78 "N" 77 "M" 76 "L" 75 "K" 74 "J" 73 "I" 72 "H" 71 "G" 70 "F" 69 "E" 68 "D" 67 "C" 66 "B" 65 "A" 57 "9" 56 "8" 55 "7" 54 "6" 53 "5" 52 "4" 51 "3" 50 "2" 49 "1" 48 "0" ;
VAL_ 2566888448 ENG_TYPE_ID_16 122 "z" 121 "y" 120 "x" 119 "w" 118 "v" 117 "u" 116 "t" 115 "s" 114 "r" 113 "q" 112 "p" 111 "o" 110 "n" 109 "m" 108 "l" 107 "k" 106 "j" 105 "i" 104 "h" 103 "g" 102 "f" 101 "e" 100 "d" 99 "c" 98 "b" 97 "a" 42 "*" 90 "Z" 89 "Y" 88 "X" 87 "W" 86 "V" 85 "U" 84 "T" 83 "S" 82 "R" 81 "Q" 80 "P" 79 "O" 78 "N" 77 "M" 76 "L" 75 "K" 74 "J" 73 "I" 72 "H" 71 "G" 70 "F" 69 "E" 68 "D" 67 "C" 66 "B" 65 "A" 57 "9" 56 "8" 55 "7" 54 "6" 53 "5" 52 "4" 51 "3" 50 "2" 49 "1" 48 "0" ;
VAL_ 2566888448 ENG_TYPE_ID_15 122 "z" 121 "y" 120 "x" 119 "w" 118 "v" 117 "u" 116 "t" 115 "s" 114 "r" 113 "q" 112 "p" 111 "o" 110 "n" 109 "m" 108 "l" 107 "k" 106 "j" 105 "i" 104 "h" 103 "g" 102 "f" 101 "e" 100 "d" 99 "c" 98 "b" 97 "a" 42 "*" 90 "Z" 89 "Y" 88 "X" 87 "W" 86 "V" 85 "U" 84 "T" 83 "S" 82 "R" 81 "Q" 80 "P" 79 "O" 78 "N" 77 "M" 76 "L" 75 "K" 74 "J" 73 "I" 72 "H" 71 "G" 70 "F" 69 "E" 68 "D" 67 "C" 66 "B" 65 "A" 57 "9" 56 "8" 55 "7" 54 "6" 53 "5" 52 "4" 51 "3" 50 "2" 49 "1" 48 "0" ;
VAL_ 2566888448 ENG_TYPE_ID_14 122 "z" 121 "y" 120 "x" 119 "w" 118 "v" 117 "u" 116 "t" 115 "s" 114 "r" 113 "q" 112 "p" 111 "o" 110 "n" 109 "m" 108 "l" 107 "k" 106 "j" 105 "i" 104 "h" 103 "g" 102 "f" 101 "e" 100 "d" 99 "c" 98 "b" 97 "a" 42 "*" 90 "Z" 89 "Y" 88 "X" 87 "W" 86 "V" 85 "U" 84 "T" 83 "S" 82 "R" 81 "Q" 80 "P" 79 "O" 78 "N" 77 "M" 76 "L" 75 "K" 74 "J" 73 "I" 72 "H" 71 "G" 70 "F" 69 "E" 68 "D" 67 "C" 66 "B" 65 "A" 57 "9" 56 "8" 55 "7" 54 "6" 53 "5" 52 "4" 51 "3" 50 "2" 49 "1" 48 "0" ;
VAL_ 2566888448 ENG_TYPE_ID_13 122 "z" 121 "y" 120 "x" 119 "w" 118 "v" 117 "u" 116 "t" 115 "s" 114 "r" 113 "q" 112 "p" 111 "o" 110 "n" 109 "m" 108 "l" 107 "k" 106 "j" 105 "i" 104 "h" 103 "g" 102 "f" 101 "e" 100 "d" 99 "c" 98 "b" 97 "a" 42 "*" 90 "Z" 89 "Y" 88 "X" 87 "W" 86 "V" 85 "U" 84 "T" 83 "S" 82 "R" 81 "Q" 80 "P" 79 "O" 78 "N" 77 "M" 76 "L" 75 "K" 74 "J" 73 "I" 72 "H" 71 "G" 70 "F" 69 "E" 68 "D" 67 "C" 66 "B" 65 "A" 57 "9" 56 "8" 55 "7" 54 "6" 53 "5" 52 "4" 51 "3" 50 "2" 49 "1" 48 "0" ;
VAL_ 2566888448 ENG_TYPE_ID_12 122 "z" 121 "y" 120 "x" 119 "w" 118 "v" 117 "u" 116 "t" 115 "s" 114 "r" 113 "q" 112 "p" 111 "o" 110 "n" 109 "m" 108 "l" 107 "k" 106 "j" 105 "i" 104 "h" 103 "g" 102 "f" 101 "e" 100 "d" 99 "c" 98 "b" 97 "a" 42 "*" 90 "Z" 89 "Y" 88 "X" 87 "W" 86 "V" 85 "U" 84 "T" 83 "S" 82 "R" 81 "Q" 80 "P" 79 "O" 78 "N" 77 "M" 76 "L" 75 "K" 74 "J" 73 "I" 72 "H" 71 "G" 70 "F" 69 "E" 68 "D" 67 "C" 66 "B" 65 "A" 57 "9" 56 "8" 55 "7" 54 "6" 53 "5" 52 "4" 51 "3" 50 "2" 49 "1" 48 "0" ;
VAL_ 2566888448 ENG_TYPE_ID_11 122 "z" 121 "y" 120 "x" 119 "w" 118 "v" 117 "u" 116 "t" 115 "s" 114 "r" 113 "q" 112 "p" 111 "o" 110 "n" 109 "m" 108 "l" 107 "k" 106 "j" 105 "i" 104 "h" 103 "g" 102 "f" 101 "e" 100 "d" 99 "c" 98 "b" 97 "a" 42 "*" 90 "Z" 89 "Y" 88 "X" 87 "W" 86 "V" 85 "U" 84 "T" 83 "S" 82 "R" 81 "Q" 80 "P" 79 "O" 78 "N" 77 "M" 76 "L" 75 "K" 74 "J" 73 "I" 72 "H" 71 "G" 70 "F" 69 "E" 68 "D" 67 "C" 66 "B" 65 "A" 57 "9" 56 "8" 55 "7" 54 "6" 53 "5" 52 "4" 51 "3" 50 "2" 49 "1" 48 "0" ;
VAL_ 2566888448 ENG_TYPE_ID_10 122 "z" 121 "y" 120 "x" 119 "w" 118 "v" 117 "u" 116 "t" 115 "s" 114 "r" 113 "q" 112 "p" 111 "o" 110 "n" 109 "m" 108 "l" 107 "k" 106 "j" 105 "i" 104 "h" 103 "g" 102 "f" 101 "e" 100 "d" 99 "c" 98 "b" 97 "a" 42 "*" 90 "Z" 89 "Y" 88 "X" 87 "W" 86 "V" 85 "U" 84 "T" 83 "S" 82 "R" 81 "Q" 80 "P" 79 "O" 78 "N" 77 "M" 76 "L" 75 "K" 74 "J" 73 "I" 72 "H" 71 "G" 70 "F" 69 "E" 68 "D" 67 "C" 66 "B" 65 "A" 57 "9" 56 "8" 55 "7" 54 "6" 53 "5" 52 "4" 51 "3" 50 "2" 49 "1" 48 "0" ;
VAL_ 2566888448 ENG_TYPE_ID_09 122 "z" 121 "y" 120 "x" 119 "w" 118 "v" 117 "u" 116 "t" 115 "s" 114 "r" 113 "q" 112 "p" 111 "o" 110 "n" 109 "m" 108 "l" 107 "k" 106 "j" 105 "i" 104 "h" 103 "g" 102 "f" 101 "e" 100 "d" 99 "c" 98 "b" 97 "a" 42 "*" 90 "Z" 89 "Y" 88 "X" 87 "W" 86 "V" 85 "U" 84 "T" 83 "S" 82 "R" 81 "Q" 80 "P" 79 "O" 78 "N" 77 "M" 76 "L" 75 "K" 74 "J" 73 "I" 72 "H" 71 "G" 70 "F" 69 "E" 68 "D" 67 "C" 66 "B" 65 "A" 57 "9" 56 "8" 55 "7" 54 "6" 53 "5" 52 "4" 51 "3" 50 "2" 49 "1" 48 "0" ;
VAL_ 2566888448 ENG_TYPE_ID_08 122 "z" 121 "y" 120 "x" 119 "w" 118 "v" 117 "u" 116 "t" 115 "s" 114 "r" 113 "q" 112 "p" 111 "o" 110 "n" 109 "m" 108 "l" 107 "k" 106 "j" 105 "i" 104 "h" 103 "g" 102 "f" 101 "e" 100 "d" 99 "c" 98 "b" 97 "a" 42 "*" 90 "Z" 89 "Y" 88 "X" 87 "W" 86 "V" 85 "U" 84 "T" 83 "S" 82 "R" 81 "Q" 80 "P" 79 "O" 78 "N" 77 "M" 76 "L" 75 "K" 74 "J" 73 "I" 72 "H" 71 "G" 70 "F" 69 "E" 68 "D" 67 "C" 66 "B" 65 "A" 57 "9" 56 "8" 55 "7" 54 "6" 53 "5" 52 "4" 51 "3" 50 "2" 49 "1" 48 "0" ;
VAL_ 2566888448 ENG_TYPE_ID_07 122 "z" 121 "y" 120 "x" 119 "w" 118 "v" 117 "u" 116 "t" 115 "s" 114 "r" 113 "q" 112 "p" 111 "o" 110 "n" 109 "m" 108 "l" 107 "k" 106 "j" 105 "i" 104 "h" 103 "g" 102 "f" 101 "e" 100 "d" 99 "c" 98 "b" 97 "a" 42 "*" 90 "Z" 89 "Y" 88 "X" 87 "W" 86 "V" 85 "U" 84 "T" 83 "S" 82 "R" 81 "Q" 80 "P" 79 "O" 78 "N" 77 "M" 76 "L" 75 "K" 74 "J" 73 "I" 72 "H" 71 "G" 70 "F" 69 "E" 68 "D" 67 "C" 66 "B" 65 "A" 57 "9" 56 "8" 55 "7" 54 "6" 53 "5" 52 "4" 51 "3" 50 "2" 49 "1" 48 "0" ;
VAL_ 2566888448 ENG_TYPE_ID_06 122 "z" 121 "y" 120 "x" 119 "w" 118 "v" 117 "u" 116 "t" 115 "s" 114 "r" 113 "q" 112 "p" 111 "o" 110 "n" 109 "m" 108 "l" 107 "k" 106 "j" 105 "i" 104 "h" 103 "g" 102 "f" 101 "e" 100 "d" 99 "c" 98 "b" 97 "a" 42 "*" 90 "Z" 89 "Y" 88 "X" 87 "W" 86 "V" 85 "U" 84 "T" 83 "S" 82 "R" 81 "Q" 80 "P" 79 "O" 78 "N" 77 "M" 76 "L" 75 "K" 74 "J" 73 "I" 72 "H" 71 "G" 70 "F" 69 "E" 68 "D" 67 "C" 66 "B" 65 "A" 57 "9" 56 "8" 55 "7" 54 "6" 53 "5" 52 "4" 51 "3" 50 "2" 49 "1" 48 "0" ;
VAL_ 2566888448 ENG_TYPE_ID_05 122 "z" 121 "y" 120 "x" 119 "w" 118 "v" 117 "u" 116 "t" 115 "s" 114 "r" 113 "q" 112 "p" 111 "o" 110 "n" 109 "m" 108 "l" 107 "k" 106 "j" 105 "i" 104 "h" 103 "g" 102 "f" 101 "e" 100 "d" 99 "c" 98 "b" 97 "a" 42 "*" 90 "Z" 89 "Y" 88 "X" 87 "W" 86 "V" 85 "U" 84 "T" 83 "S" 82 "R" 81 "Q" 80 "P" 79 "O" 78 "N" 77 "M" 76 "L" 75 "K" 74 "J" 73 "I" 72 "H" 71 "G" 70 "F" 69 "E" 68 "D" 67 "C" 66 "B" 65 "A" 57 "9" 56 "8" 55 "7" 54 "6" 53 "5" 52 "4" 51 "3" 50 "2" 49 "1" 48 "0" ;
VAL_ 2566888448 ENG_TYPE_ID_04 122 "z" 121 "y" 120 "x" 119 "w" 118 "v" 117 "u" 116 "t" 115 "s" 114 "r" 113 "q" 112 "p" 111 "o" 110 "n" 109 "m" 108 "l" 107 "k" 106 "j" 105 "i" 104 "h" 103 "g" 102 "f" 101 "e" 100 "d" 99 "c" 98 "b" 97 "a" 42 "*" 90 "Z" 89 "Y" 88 "X" 87 "W" 86 "V" 85 "U" 84 "T" 83 "S" 82 "R" 81 "Q" 80 "P" 79 "O" 78 "N" 77 "M" 76 "L" 75 "K" 74 "J" 73 "I" 72 "H" 71 "G" 70 "F" 69 "E" 68 "D" 67 "C" 66 "B" 65 "A" 57 "9" 56 "8" 55 "7" 54 "6" 53 "5" 52 "4" 51 "3" 50 "2" 49 "1" 48 "0" ;
VAL_ 2566888448 ENG_TYPE_ID_03 122 "z" 121 "y" 120 "x" 119 "w" 118 "v" 117 "u" 116 "t" 115 "s" 114 "r" 113 "q" 112 "p" 111 "o" 110 "n" 109 "m" 108 "l" 107 "k" 106 "j" 105 "i" 104 "h" 103 "g" 102 "f" 101 "e" 100 "d" 99 "c" 98 "b" 97 "a" 42 "*" 90 "Z" 89 "Y" 88 "X" 87 "W" 86 "V" 85 "U" 84 "T" 83 "S" 82 "R" 81 "Q" 80 "P" 79 "O" 78 "N" 77 "M" 76 "L" 75 "K" 74 "J" 73 "I" 72 "H" 71 "G" 70 "F" 69 "E" 68 "D" 67 "C" 66 "B" 65 "A" 57 "9" 56 "8" 55 "7" 54 "6" 53 "5" 52 "4" 51 "3" 50 "2" 49 "1" 48 "0" ;
VAL_ 2566888448 ENG_TYPE_ID_02 122 "z" 121 "y" 120 "x" 119 "w" 118 "v" 117 "u" 116 "t" 115 "s" 114 "r" 113 "q" 112 "p" 111 "o" 110 "n" 109 "m" 108 "l" 107 "k" 106 "j" 105 "i" 104 "h" 103 "g" 102 "f" 101 "e" 100 "d" 99 "c" 98 "b" 97 "a" 42 "*" 90 "Z" 89 "Y" 88 "X" 87 "W" 86 "V" 85 "U" 84 "T" 83 "S" 82 "R" 81 "Q" 80 "P" 79 "O" 78 "N" 77 "M" 76 "L" 75 "K" 74 "J" 73 "I" 72 "H" 71 "G" 70 "F" 69 "E" 68 "D" 67 "C" 66 "B" 65 "A" 57 "9" 56 "8" 55 "7" 54 "6" 53 "5" 52 "4" 51 "3" 50 "2" 49 "1" 48 "0" ;
VAL_ 2566888448 ENG_TYPE_ID_01 122 "z" 121 "y" 120 "x" 119 "w" 118 "v" 117 "u" 116 "t" 115 "s" 114 "r" 113 "q" 112 "p" 111 "o" 110 "n" 109 "m" 108 "l" 107 "k" 106 "j" 105 "i" 104 "h" 103 "g" 102 "f" 101 "e" 100 "d" 99 "c" 98 "b" 97 "a" 42 "*" 90 "Z" 89 "Y" 88 "X" 87 "W" 86 "V" 85 "U" 84 "T" 83 "S" 82 "R" 81 "Q" 80 "P" 79 "O" 78 "N" 77 "M" 76 "L" 75 "K" 74 "J" 73 "I" 72 "H" 71 "G" 70 "F" 69 "E" 68 "D" 67 "C" 66 "B" 65 "A" 57 "9" 56 "8" 55 "7" 54 "6" 53 "5" 52 "4" 51 "3" 50 "2" 49 "1" 48 "0" ;
VAL_ 2566888448 NRATED_APPL_ID_20 122 "z" 121 "y" 120 "x" 119 "w" 118 "v" 117 "u" 116 "t" 115 "s" 114 "r" 113 "q" 112 "p" 111 "o" 110 "n" 109 "m" 108 "l" 107 "k" 106 "j" 105 "i" 104 "h" 103 "g" 102 "f" 101 "e" 100 "d" 99 "c" 98 "b" 97 "a" 42 "*" 90 "Z" 89 "Y" 88 "X" 87 "W" 86 "V" 85 "U" 84 "T" 83 "S" 82 "R" 81 "Q" 80 "P" 79 "O" 78 "N" 77 "M" 76 "L" 75 "K" 74 "J" 73 "I" 72 "H" 71 "G" 70 "F" 69 "E" 68 "D" 67 "C" 66 "B" 65 "A" 57 "9" 56 "8" 55 "7" 54 "6" 53 "5" 52 "4" 51 "3" 50 "2" 49 "1" 48 "0" ;
VAL_ 2566888448 NRATED_APPL_ID_19 122 "z" 121 "y" 120 "x" 119 "w" 118 "v" 117 "u" 116 "t" 115 "s" 114 "r" 113 "q" 112 "p" 111 "o" 110 "n" 109 "m" 108 "l" 107 "k" 106 "j" 105 "i" 104 "h" 103 "g" 102 "f" 101 "e" 100 "d" 99 "c" 98 "b" 97 "a" 42 "*" 90 "Z" 89 "Y" 88 "X" 87 "W" 86 "V" 85 "U" 84 "T" 83 "S" 82 "R" 81 "Q" 80 "P" 79 "O" 78 "N" 77 "M" 76 "L" 75 "K" 74 "J" 73 "I" 72 "H" 71 "G" 70 "F" 69 "E" 68 "D" 67 "C" 66 "B" 65 "A" 57 "9" 56 "8" 55 "7" 54 "6" 53 "5" 52 "4" 51 "3" 50 "2" 49 "1" 48 "0" ;
VAL_ 2566888448 NRATED_APPL_ID_18 122 "z" 121 "y" 120 "x" 119 "w" 118 "v" 117 "u" 116 "t" 115 "s" 114 "r" 113 "q" 112 "p" 111 "o" 110 "n" 109 "m" 108 "l" 107 "k" 106 "j" 105 "i" 104 "h" 103 "g" 102 "f" 101 "e" 100 "d" 99 "c" 98 "b" 97 "a" 42 "*" 90 "Z" 89 "Y" 88 "X" 87 "W" 86 "V" 85 "U" 84 "T" 83 "S" 82 "R" 81 "Q" 80 "P" 79 "O" 78 "N" 77 "M" 76 "L" 75 "K" 74 "J" 73 "I" 72 "H" 71 "G" 70 "F" 69 "E" 68 "D" 67 "C" 66 "B" 65 "A" 57 "9" 56 "8" 55 "7" 54 "6" 53 "5" 52 "4" 51 "3" 50 "2" 49 "1" 48 "0" ;
VAL_ 2566888448 NRATED_APPL_ID_17 122 "z" 121 "y" 120 "x" 119 "w" 118 "v" 117 "u" 116 "t" 115 "s" 114 "r" 113 "q" 112 "p" 111 "o" 110 "n" 109 "m" 108 "l" 107 "k" 106 "j" 105 "i" 104 "h" 103 "g" 102 "f" 101 "e" 100 "d" 99 "c" 98 "b" 97 "a" 42 "*" 90 "Z" 89 "Y" 88 "X" 87 "W" 86 "V" 85 "U" 84 "T" 83 "S" 82 "R" 81 "Q" 80 "P" 79 "O" 78 "N" 77 "M" 76 "L" 75 "K" 74 "J" 73 "I" 72 "H" 71 "G" 70 "F" 69 "E" 68 "D" 67 "C" 66 "B" 65 "A" 57 "9" 56 "8" 55 "7" 54 "6" 53 "5" 52 "4" 51 "3" 50 "2" 49 "1" 48 "0" ;
VAL_ 2566888448 NRATED_APPL_ID_16 122 "z" 121 "y" 120 "x" 119 "w" 118 "v" 117 "u" 116 "t" 115 "s" 114 "r" 113 "q" 112 "p" 111 "o" 110 "n" 109 "m" 108 "l" 107 "k" 106 "j" 105 "i" 104 "h" 103 "g" 102 "f" 101 "e" 100 "d" 99 "c" 98 "b" 97 "a" 42 "*" 90 "Z" 89 "Y" 88 "X" 87 "W" 86 "V" 85 "U" 84 "T" 83 "S" 82 "R" 81 "Q" 80 "P" 79 "O" 78 "N" 77 "M" 76 "L" 75 "K" 74 "J" 73 "I" 72 "H" 71 "G" 70 "F" 69 "E" 68 "D" 67 "C" 66 "B" 65 "A" 57 "9" 56 "8" 55 "7" 54 "6" 53 "5" 52 "4" 51 "3" 50 "2" 49 "1" 48 "0" ;
VAL_ 2566888448 NRATED_APPL_ID_15 122 "z" 121 "y" 120 "x" 119 "w" 118 "v" 117 "u" 116 "t" 115 "s" 114 "r" 113 "q" 112 "p" 111 "o" 110 "n" 109 "m" 108 "l" 107 "k" 106 "j" 105 "i" 104 "h" 103 "g" 102 "f" 101 "e" 100 "d" 99 "c" 98 "b" 97 "a" 42 "*" 90 "Z" 89 "Y" 88 "X" 87 "W" 86 "V" 85 "U" 84 "T" 83 "S" 82 "R" 81 "Q" 80 "P" 79 "O" 78 "N" 77 "M" 76 "L" 75 "K" 74 "J" 73 "I" 72 "H" 71 "G" 70 "F" 69 "E" 68 "D" 67 "C" 66 "B" 65 "A" 57 "9" 56 "8" 55 "7" 54 "6" 53 "5" 52 "4" 51 "3" 50 "2" 49 "1" 48 "0" ;
VAL_ 2566888448 NRATED_APPL_ID_14 122 "z" 121 "y" 120 "x" 119 "w" 118 "v" 117 "u" 116 "t" 115 "s" 114 "r" 113 "q" 112 "p" 111 "o" 110 "n" 109 "m" 108 "l" 107 "k" 106 "j" 105 "i" 104 "h" 103 "g" 102 "f" 101 "e" 100 "d" 99 "c" 98 "b" 97 "a" 42 "*" 90 "Z" 89 "Y" 88 "X" 87 "W" 86 "V" 85 "U" 84 "T" 83 "S" 82 "R" 81 "Q" 80 "P" 79 "O" 78 "N" 77 "M" 76 "L" 75 "K" 74 "J" 73 "I" 72 "H" 71 "G" 70 "F" 69 "E" 68 "D" 67 "C" 66 "B" 65 "A" 57 "9" 56 "8" 55 "7" 54 "6" 53 "5" 52 "4" 51 "3" 50 "2" 49 "1" 48 "0" ;
VAL_ 2566888448 NRATED_APPL_ID_13 122 "z" 121 "y" 120 "x" 119 "w" 118 "v" 117 "u" 116 "t" 115 "s" 114 "r" 113 "q" 112 "p" 111 "o" 110 "n" 109 "m" 108 "l" 107 "k" 106 "j" 105 "i" 104 "h" 103 "g" 102 "f" 101 "e" 100 "d" 99 "c" 98 "b" 97 "a" 42 "*" 90 "Z" 89 "Y" 88 "X" 87 "W" 86 "V" 85 "U" 84 "T" 83 "S" 82 "R" 81 "Q" 80 "P" 79 "O" 78 "N" 77 "M" 76 "L" 75 "K" 74 "J" 73 "I" 72 "H" 71 "G" 70 "F" 69 "E" 68 "D" 67 "C" 66 "B" 65 "A" 57 "9" 56 "8" 55 "7" 54 "6" 53 "5" 52 "4" 51 "3" 50 "2" 49 "1" 48 "0" ;
VAL_ 2566888448 NRATED_APPL_ID_12 122 "z" 121 "y" 120 "x" 119 "w" 118 "v" 117 "u" 116 "t" 115 "s" 114 "r" 113 "q" 112 "p" 111 "o" 110 "n" 109 "m" 108 "l" 107 "k" 106 "j" 105 "i" 104 "h" 103 "g" 102 "f" 101 "e" 100 "d" 99 "c" 98 "b" 97 "a" 42 "*" 90 "Z" 89 "Y" 88 "X" 87 "W" 86 "V" 85 "U" 84 "T" 83 "S" 82 "R" 81 "Q" 80 "P" 79 "O" 78 "N" 77 "M" 76 "L" 75 "K" 74 "J" 73 "I" 72 "H" 71 "G" 70 "F" 69 "E" 68 "D" 67 "C" 66 "B" 65 "A" 57 "9" 56 "8" 55 "7" 54 "6" 53 "5" 52 "4" 51 "3" 50 "2" 49 "1" 48 "0" ;
VAL_ 2566888448 NRATED_APPL_ID_11 122 "z" 121 "y" 120 "x" 119 "w" 118 "v" 117 "u" 116 "t" 115 "s" 114 "r" 113 "q" 112 "p" 111 "o" 110 "n" 109 "m" 108 "l" 107 "k" 106 "j" 105 "i" 104 "h" 103 "g" 102 "f" 101 "e" 100 "d" 99 "c" 98 "b" 97 "a" 42 "*" 90 "Z" 89 "Y" 88 "X" 87 "W" 86 "V" 85 "U" 84 "T" 83 "S" 82 "R" 81 "Q" 80 "P" 79 "O" 78 "N" 77 "M" 76 "L" 75 "K" 74 "J" 73 "I" 72 "H" 71 "G" 70 "F" 69 "E" 68 "D" 67 "C" 66 "B" 65 "A" 57 "9" 56 "8" 55 "7" 54 "6" 53 "5" 52 "4" 51 "3" 50 "2" 49 "1" 48 "0" ;
VAL_ 2566888448 NRATED_APPL_ID_10 122 "z" 121 "y" 120 "x" 119 "w" 118 "v" 117 "u" 116 "t" 115 "s" 114 "r" 113 "q" 112 "p" 111 "o" 110 "n" 109 "m" 108 "l" 107 "k" 106 "j" 105 "i" 104 "h" 103 "g" 102 "f" 101 "e" 100 "d" 99 "c" 98 "b" 97 "a" 42 "*" 90 "Z" 89 "Y" 88 "X" 87 "W" 86 "V" 85 "U" 84 "T" 83 "S" 82 "R" 81 "Q" 80 "P" 79 "O" 78 "N" 77 "M" 76 "L" 75 "K" 74 "J" 73 "I" 72 "H" 71 "G" 70 "F" 69 "E" 68 "D" 67 "C" 66 "B" 65 "A" 57 "9" 56 "8" 55 "7" 54 "6" 53 "5" 52 "4" 51 "3" 50 "2" 49 "1" 48 "0" ;
VAL_ 2566888448 NRATED_APPL_ID_09 122 "z" 121 "y" 120 "x" 119 "w" 118 "v" 117 "u" 116 "t" 115 "s" 114 "r" 113 "q" 112 "p" 111 "o" 110 "n" 109 "m" 108 "l" 107 "k" 106 "j" 105 "i" 104 "h" 103 "g" 102 "f" 101 "e" 100 "d" 99 "c" 98 "b" 97 "a" 42 "*" 90 "Z" 89 "Y" 88 "X" 87 "W" 86 "V" 85 "U" 84 "T" 83 "S" 82 "R" 81 "Q" 80 "P" 79 "O" 78 "N" 77 "M" 76 "L" 75 "K" 74 "J" 73 "I" 72 "H" 71 "G" 70 "F" 69 "E" 68 "D" 67 "C" 66 "B" 65 "A" 57 "9" 56 "8" 55 "7" 54 "6" 53 "5" 52 "4" 51 "3" 50 "2" 49 "1" 48 "0" ;
VAL_ 2566888448 NRATED_APPL_ID_08 122 "z" 121 "y" 120 "x" 119 "w" 118 "v" 117 "u" 116 "t" 115 "s" 114 "r" 113 "q" 112 "p" 111 "o" 110 "n" 109 "m" 108 "l" 107 "k" 106 "j" 105 "i" 104 "h" 103 "g" 102 "f" 101 "e" 100 "d" 99 "c" 98 "b" 97 "a" 42 "*" 90 "Z" 89 "Y" 88 "X" 87 "W" 86 "V" 85 "U" 84 "T" 83 "S" 82 "R" 81 "Q" 80 "P" 79 "O" 78 "N" 77 "M" 76 "L" 75 "K" 74 "J" 73 "I" 72 "H" 71 "G" 70 "F" 69 "E" 68 "D" 67 "C" 66 "B" 65 "A" 57 "9" 56 "8" 55 "7" 54 "6" 53 "5" 52 "4" 51 "3" 50 "2" 49 "1" 48 "0" ;
VAL_ 2566888448 NRATED_APPL_ID_07 122 "z" 121 "y" 120 "x" 119 "w" 118 "v" 117 "u" 116 "t" 115 "s" 114 "r" 113 "q" 112 "p" 111 "o" 110 "n" 109 "m" 108 "l" 107 "k" 106 "j" 105 "i" 104 "h" 103 "g" 102 "f" 101 "e" 100 "d" 99 "c" 98 "b" 97 "a" 42 "*" 90 "Z" 89 "Y" 88 "X" 87 "W" 86 "V" 85 "U" 84 "T" 83 "S" 82 "R" 81 "Q" 80 "P" 79 "O" 78 "N" 77 "M" 76 "L" 75 "K" 74 "J" 73 "I" 72 "H" 71 "G" 70 "F" 69 "E" 68 "D" 67 "C" 66 "B" 65 "A" 57 "9" 56 "8" 55 "7" 54 "6" 53 "5" 52 "4" 51 "3" 50 "2" 49 "1" 48 "0" ;
VAL_ 2566888448 NRATED_APPL_ID_06 122 "z" 121 "y" 120 "x" 119 "w" 118 "v" 117 "u" 116 "t" 115 "s" 114 "r" 113 "q" 112 "p" 111 "o" 110 "n" 109 "m" 108 "l" 107 "k" 106 "j" 105 "i" 104 "h" 103 "g" 102 "f" 101 "e" 100 "d" 99 "c" 98 "b" 97 "a" 42 "*" 90 "Z" 89 "Y" 88 "X" 87 "W" 86 "V" 85 "U" 84 "T" 83 "S" 82 "R" 81 "Q" 80 "P" 79 "O" 78 "N" 77 "M" 76 "L" 75 "K" 74 "J" 73 "I" 72 "H" 71 "G" 70 "F" 69 "E" 68 "D" 67 "C" 66 "B" 65 "A" 57 "9" 56 "8" 55 "7" 54 "6" 53 "5" 52 "4" 51 "3" 50 "2" 49 "1" 48 "0" ;
VAL_ 2566888448 NRATED_APPL_ID_05 122 "z" 121 "y" 120 "x" 119 "w" 118 "v" 117 "u" 116 "t" 115 "s" 114 "r" 113 "q" 112 "p" 111 "o" 110 "n" 109 "m" 108 "l" 107 "k" 106 "j" 105 "i" 104 "h" 103 "g" 102 "f" 101 "e" 100 "d" 99 "c" 98 "b" 97 "a" 42 "*" 90 "Z" 89 "Y" 88 "X" 87 "W" 86 "V" 85 "U" 84 "T" 83 "S" 82 "R" 81 "Q" 80 "P" 79 "O" 78 "N" 77 "M" 76 "L" 75 "K" 74 "J" 73 "I" 72 "H" 71 "G" 70 "F" 69 "E" 68 "D" 67 "C" 66 "B" 65 "A" 57 "9" 56 "8" 55 "7" 54 "6" 53 "5" 52 "4" 51 "3" 50 "2" 49 "1" 48 "0" ;
VAL_ 2566888448 NRATED_APPL_ID_04 122 "z" 121 "y" 120 "x" 119 "w" 118 "v" 117 "u" 116 "t" 115 "s" 114 "r" 113 "q" 112 "p" 111 "o" 110 "n" 109 "m" 108 "l" 107 "k" 106 "j" 105 "i" 104 "h" 103 "g" 102 "f" 101 "e" 100 "d" 99 "c" 98 "b" 97 "a" 42 "*" 90 "Z" 89 "Y" 88 "X" 87 "W" 86 "V" 85 "U" 84 "T" 83 "S" 82 "R" 81 "Q" 80 "P" 79 "O" 78 "N" 77 "M" 76 "L" 75 "K" 74 "J" 73 "I" 72 "H" 71 "G" 70 "F" 69 "E" 68 "D" 67 "C" 66 "B" 65 "A" 57 "9" 56 "8" 55 "7" 54 "6" 53 "5" 52 "4" 51 "3" 50 "2" 49 "1" 48 "0" ;
VAL_ 2566888448 NRATED_APPL_ID_03 122 "z" 121 "y" 120 "x" 119 "w" 118 "v" 117 "u" 116 "t" 115 "s" 114 "r" 113 "q" 112 "p" 111 "o" 110 "n" 109 "m" 108 "l" 107 "k" 106 "j" 105 "i" 104 "h" 103 "g" 102 "f" 101 "e" 100 "d" 99 "c" 98 "b" 97 "a" 42 "*" 90 "Z" 89 "Y" 88 "X" 87 "W" 86 "V" 85 "U" 84 "T" 83 "S" 82 "R" 81 "Q" 80 "P" 79 "O" 78 "N" 77 "M" 76 "L" 75 "K" 74 "J" 73 "I" 72 "H" 71 "G" 70 "F" 69 "E" 68 "D" 67 "C" 66 "B" 65 "A" 57 "9" 56 "8" 55 "7" 54 "6" 53 "5" 52 "4" 51 "3" 50 "2" 49 "1" 48 "0" ;
VAL_ 2566888448 NRATED_APPL_ID_02 122 "z" 121 "y" 120 "x" 119 "w" 118 "v" 117 "u" 116 "t" 115 "s" 114 "r" 113 "q" 112 "p" 111 "o" 110 "n" 109 "m" 108 "l" 107 "k" 106 "j" 105 "i" 104 "h" 103 "g" 102 "f" 101 "e" 100 "d" 99 "c" 98 "b" 97 "a" 42 "*" 90 "Z" 89 "Y" 88 "X" 87 "W" 86 "V" 85 "U" 84 "T" 83 "S" 82 "R" 81 "Q" 80 "P" 79 "O" 78 "N" 77 "M" 76 "L" 75 "K" 74 "J" 73 "I" 72 "H" 71 "G" 70 "F" 69 "E" 68 "D" 67 "C" 66 "B" 65 "A" 57 "9" 56 "8" 55 "7" 54 "6" 53 "5" 52 "4" 51 "3" 50 "2" 49 "1" 48 "0" ;
VAL_ 2566888448 NRATED_APPL_ID_01 122 "z" 121 "y" 120 "x" 119 "w" 118 "v" 117 "u" 116 "t" 115 "s" 114 "r" 113 "q" 112 "p" 111 "o" 110 "n" 109 "m" 108 "l" 107 "k" 106 "j" 105 "i" 104 "h" 103 "g" 102 "f" 101 "e" 100 "d" 99 "c" 98 "b" 97 "a" 42 "*" 90 "Z" 89 "Y" 88 "X" 87 "W" 86 "V" 85 "U" 84 "T" 83 "S" 82 "R" 81 "Q" 80 "P" 79 "O" 78 "N" 77 "M" 76 "L" 75 "K" 74 "J" 73 "I" 72 "H" 71 "G" 70 "F" 69 "E" 68 "D" 67 "C" 66 "B" 65 "A" 57 "9" 56 "8" 55 "7" 54 "6" 53 "5" 52 "4" 51 "3" 50 "2" 49 "1" 48 "0" ;
VAL_ 2566888448 RATING_ID_20 122 "z" 121 "y" 120 "x" 119 "w" 118 "v" 117 "u" 116 "t" 115 "s" 114 "r" 113 "q" 112 "p" 111 "o" 110 "n" 109 "m" 108 "l" 107 "k" 106 "j" 105 "i" 104 "h" 103 "g" 102 "f" 101 "e" 100 "d" 99 "c" 98 "b" 97 "a" 42 "*" 90 "Z" 89 "Y" 88 "X" 87 "W" 86 "V" 85 "U" 84 "T" 83 "S" 82 "R" 81 "Q" 80 "P" 79 "O" 78 "N" 77 "M" 76 "L" 75 "K" 74 "J" 73 "I" 72 "H" 71 "G" 70 "F" 69 "E" 68 "D" 67 "C" 66 "B" 65 "A" 57 "9" 56 "8" 55 "7" 54 "6" 53 "5" 52 "4" 51 "3" 50 "2" 49 "1" 48 "0" ;
VAL_ 2566888448 RATING_ID_19 122 "z" 121 "y" 120 "x" 119 "w" 118 "v" 117 "u" 116 "t" 115 "s" 114 "r" 113 "q" 112 "p" 111 "o" 110 "n" 109 "m" 108 "l" 107 "k" 106 "j" 105 "i" 104 "h" 103 "g" 102 "f" 101 "e" 100 "d" 99 "c" 98 "b" 97 "a" 42 "*" 90 "Z" 89 "Y" 88 "X" 87 "W" 86 "V" 85 "U" 84 "T" 83 "S" 82 "R" 81 "Q" 80 "P" 79 "O" 78 "N" 77 "M" 76 "L" 75 "K" 74 "J" 73 "I" 72 "H" 71 "G" 70 "F" 69 "E" 68 "D" 67 "C" 66 "B" 65 "A" 57 "9" 56 "8" 55 "7" 54 "6" 53 "5" 52 "4" 51 "3" 50 "2" 49 "1" 48 "0" ;
VAL_ 2566888448 RATING_ID_18 122 "z" 121 "y" 120 "x" 119 "w" 118 "v" 117 "u" 116 "t" 115 "s" 114 "r" 113 "q" 112 "p" 111 "o" 110 "n" 109 "m" 108 "l" 107 "k" 106 "j" 105 "i" 104 "h" 103 "g" 102 "f" 101 "e" 100 "d" 99 "c" 98 "b" 97 "a" 42 "*" 90 "Z" 89 "Y" 88 "X" 87 "W" 86 "V" 85 "U" 84 "T" 83 "S" 82 "R" 81 "Q" 80 "P" 79 "O" 78 "N" 77 "M" 76 "L" 75 "K" 74 "J" 73 "I" 72 "H" 71 "G" 70 "F" 69 "E" 68 "D" 67 "C" 66 "B" 65 "A" 57 "9" 56 "8" 55 "7" 54 "6" 53 "5" 52 "4" 51 "3" 50 "2" 49 "1" 48 "0" ;
VAL_ 2566888448 RATING_ID_17 122 "z" 121 "y" 120 "x" 119 "w" 118 "v" 117 "u" 116 "t" 115 "s" 114 "r" 113 "q" 112 "p" 111 "o" 110 "n" 109 "m" 108 "l" 107 "k" 106 "j" 105 "i" 104 "h" 103 "g" 102 "f" 101 "e" 100 "d" 99 "c" 98 "b" 97 "a" 42 "*" 90 "Z" 89 "Y" 88 "X" 87 "W" 86 "V" 85 "U" 84 "T" 83 "S" 82 "R" 81 "Q" 80 "P" 79 "O" 78 "N" 77 "M" 76 "L" 75 "K" 74 "J" 73 "I" 72 "H" 71 "G" 70 "F" 69 "E" 68 "D" 67 "C" 66 "B" 65 "A" 57 "9" 56 "8" 55 "7" 54 "6" 53 "5" 52 "4" 51 "3" 50 "2" 49 "1" 48 "0" ;
VAL_ 2566888448 RATING_ID_16 122 "z" 121 "y" 120 "x" 119 "w" 118 "v" 117 "u" 116 "t" 115 "s" 114 "r" 113 "q" 112 "p" 111 "o" 110 "n" 109 "m" 108 "l" 107 "k" 106 "j" 105 "i" 104 "h" 103 "g" 102 "f" 101 "e" 100 "d" 99 "c" 98 "b" 97 "a" 42 "*" 90 "Z" 89 "Y" 88 "X" 87 "W" 86 "V" 85 "U" 84 "T" 83 "S" 82 "R" 81 "Q" 80 "P" 79 "O" 78 "N" 77 "M" 76 "L" 75 "K" 74 "J" 73 "I" 72 "H" 71 "G" 70 "F" 69 "E" 68 "D" 67 "C" 66 "B" 65 "A" 57 "9" 56 "8" 55 "7" 54 "6" 53 "5" 52 "4" 51 "3" 50 "2" 49 "1" 48 "0" ;
VAL_ 2566888448 RATING_ID_15 122 "z" 121 "y" 120 "x" 119 "w" 118 "v" 117 "u" 116 "t" 115 "s" 114 "r" 113 "q" 112 "p" 111 "o" 110 "n" 109 "m" 108 "l" 107 "k" 106 "j" 105 "i" 104 "h" 103 "g" 102 "f" 101 "e" 100 "d" 99 "c" 98 "b" 97 "a" 42 "*" 90 "Z" 89 "Y" 88 "X" 87 "W" 86 "V" 85 "U" 84 "T" 83 "S" 82 "R" 81 "Q" 80 "P" 79 "O" 78 "N" 77 "M" 76 "L" 75 "K" 74 "J" 73 "I" 72 "H" 71 "G" 70 "F" 69 "E" 68 "D" 67 "C" 66 "B" 65 "A" 57 "9" 56 "8" 55 "7" 54 "6" 53 "5" 52 "4" 51 "3" 50 "2" 49 "1" 48 "0" ;
VAL_ 2566888448 RATING_ID_14 122 "z" 121 "y" 120 "x" 119 "w" 118 "v" 117 "u" 116 "t" 115 "s" 114 "r" 113 "q" 112 "p" 111 "o" 110 "n" 109 "m" 108 "l" 107 "k" 106 "j" 105 "i" 104 "h" 103 "g" 102 "f" 101 "e" 100 "d" 99 "c" 98 "b" 97 "a" 42 "*" 90 "Z" 89 "Y" 88 "X" 87 "W" 86 "V" 85 "U" 84 "T" 83 "S" 82 "R" 81 "Q" 80 "P" 79 "O" 78 "N" 77 "M" 76 "L" 75 "K" 74 "J" 73 "I" 72 "H" 71 "G" 70 "F" 69 "E" 68 "D" 67 "C" 66 "B" 65 "A" 57 "9" 56 "8" 55 "7" 54 "6" 53 "5" 52 "4" 51 "3" 50 "2" 49 "1" 48 "0" ;
VAL_ 2566888448 RATING_ID_13 122 "z" 121 "y" 120 "x" 119 "w" 118 "v" 117 "u" 116 "t" 115 "s" 114 "r" 113 "q" 112 "p" 111 "o" 110 "n" 109 "m" 108 "l" 107 "k" 106 "j" 105 "i" 104 "h" 103 "g" 102 "f" 101 "e" 100 "d" 99 "c" 98 "b" 97 "a" 42 "*" 90 "Z" 89 "Y" 88 "X" 87 "W" 86 "V" 85 "U" 84 "T" 83 "S" 82 "R" 81 "Q" 80 "P" 79 "O" 78 "N" 77 "M" 76 "L" 75 "K" 74 "J" 73 "I" 72 "H" 71 "G" 70 "F" 69 "E" 68 "D" 67 "C" 66 "B" 65 "A" 57 "9" 56 "8" 55 "7" 54 "6" 53 "5" 52 "4" 51 "3" 50 "2" 49 "1" 48 "0" ;
VAL_ 2566888448 RATING_ID_12 122 "z" 121 "y" 120 "x" 119 "w" 118 "v" 117 "u" 116 "t" 115 "s" 114 "r" 113 "q" 112 "p" 111 "o" 110 "n" 109 "m" 108 "l" 107 "k" 106 "j" 105 "i" 104 "h" 103 "g" 102 "f" 101 "e" 100 "d" 99 "c" 98 "b" 97 "a" 42 "*" 90 "Z" 89 "Y" 88 "X" 87 "W" 86 "V" 85 "U" 84 "T" 83 "S" 82 "R" 81 "Q" 80 "P" 79 "O" 78 "N" 77 "M" 76 "L" 75 "K" 74 "J" 73 "I" 72 "H" 71 "G" 70 "F" 69 "E" 68 "D" 67 "C" 66 "B" 65 "A" 57 "9" 56 "8" 55 "7" 54 "6" 53 "5" 52 "4" 51 "3" 50 "2" 49 "1" 48 "0" ;
VAL_ 2566888448 RATING_ID_11 122 "z" 121 "y" 120 "x" 119 "w" 118 "v" 117 "u" 116 "t" 115 "s" 114 "r" 113 "q" 112 "p" 111 "o" 110 "n" 109 "m" 108 "l" 107 "k" 106 "j" 105 "i" 104 "h" 103 "g" 102 "f" 101 "e" 100 "d" 99 "c" 98 "b" 97 "a" 42 "*" 90 "Z" 89 "Y" 88 "X" 87 "W" 86 "V" 85 "U" 84 "T" 83 "S" 82 "R" 81 "Q" 80 "P" 79 "O" 78 "N" 77 "M" 76 "L" 75 "K" 74 "J" 73 "I" 72 "H" 71 "G" 70 "F" 69 "E" 68 "D" 67 "C" 66 "B" 65 "A" 57 "9" 56 "8" 55 "7" 54 "6" 53 "5" 52 "4" 51 "3" 50 "2" 49 "1" 48 "0" ;
VAL_ 2566888448 RATING_ID_10 122 "z" 121 "y" 120 "x" 119 "w" 118 "v" 117 "u" 116 "t" 115 "s" 114 "r" 113 "q" 112 "p" 111 "o" 110 "n" 109 "m" 108 "l" 107 "k" 106 "j" 105 "i" 104 "h" 103 "g" 102 "f" 101 "e" 100 "d" 99 "c" 98 "b" 97 "a" 42 "*" 90 "Z" 89 "Y" 88 "X" 87 "W" 86 "V" 85 "U" 84 "T" 83 "S" 82 "R" 81 "Q" 80 "P" 79 "O" 78 "N" 77 "M" 76 "L" 75 "K" 74 "J" 73 "I" 72 "H" 71 "G" 70 "F" 69 "E" 68 "D" 67 "C" 66 "B" 65 "A" 57 "9" 56 "8" 55 "7" 54 "6" 53 "5" 52 "4" 51 "3" 50 "2" 49 "1" 48 "0" ;
VAL_ 2566888448 RATING_ID_09 122 "z" 121 "y" 120 "x" 119 "w" 118 "v" 117 "u" 116 "t" 115 "s" 114 "r" 113 "q" 112 "p" 111 "o" 110 "n" 109 "m" 108 "l" 107 "k" 106 "j" 105 "i" 104 "h" 103 "g" 102 "f" 101 "e" 100 "d" 99 "c" 98 "b" 97 "a" 42 "*" 90 "Z" 89 "Y" 88 "X" 87 "W" 86 "V" 85 "U" 84 "T" 83 "S" 82 "R" 81 "Q" 80 "P" 79 "O" 78 "N" 77 "M" 76 "L" 75 "K" 74 "J" 73 "I" 72 "H" 71 "G" 70 "F" 69 "E" 68 "D" 67 "C" 66 "B" 65 "A" 57 "9" 56 "8" 55 "7" 54 "6" 53 "5" 52 "4" 51 "3" 50 "2" 49 "1" 48 "0" ;
VAL_ 2566888448 RATING_ID_08 122 "z" 121 "y" 120 "x" 119 "w" 118 "v" 117 "u" 116 "t" 115 "s" 114 "r" 113 "q" 112 "p" 111 "o" 110 "n" 109 "m" 108 "l" 107 "k" 106 "j" 105 "i" 104 "h" 103 "g" 102 "f" 101 "e" 100 "d" 99 "c" 98 "b" 97 "a" 42 "*" 90 "Z" 89 "Y" 88 "X" 87 "W" 86 "V" 85 "U" 84 "T" 83 "S" 82 "R" 81 "Q" 80 "P" 79 "O" 78 "N" 77 "M" 76 "L" 75 "K" 74 "J" 73 "I" 72 "H" 71 "G" 70 "F" 69 "E" 68 "D" 67 "C" 66 "B" 65 "A" 57 "9" 56 "8" 55 "7" 54 "6" 53 "5" 52 "4" 51 "3" 50 "2" 49 "1" 48 "0" ;
VAL_ 2566888448 RATING_ID_07 122 "z" 121 "y" 120 "x" 119 "w" 118 "v" 117 "u" 116 "t" 115 "s" 114 "r" 113 "q" 112 "p" 111 "o" 110 "n" 109 "m" 108 "l" 107 "k" 106 "j" 105 "i" 104 "h" 103 "g" 102 "f" 101 "e" 100 "d" 99 "c" 98 "b" 97 "a" 42 "*" 90 "Z" 89 "Y" 88 "X" 87 "W" 86 "V" 85 "U" 84 "T" 83 "S" 82 "R" 81 "Q" 80 "P" 79 "O" 78 "N" 77 "M" 76 "L" 75 "K" 74 "J" 73 "I" 72 "H" 71 "G" 70 "F" 69 "E" 68 "D" 67 "C" 66 "B" 65 "A" 57 "9" 56 "8" 55 "7" 54 "6" 53 "5" 52 "4" 51 "3" 50 "2" 49 "1" 48 "0" ;
VAL_ 2566888448 RATING_ID_06 122 "z" 121 "y" 120 "x" 119 "w" 118 "v" 117 "u" 116 "t" 115 "s" 114 "r" 113 "q" 112 "p" 111 "o" 110 "n" 109 "m" 108 "l" 107 "k" 106 "j" 105 "i" 104 "h" 103 "g" 102 "f" 101 "e" 100 "d" 99 "c" 98 "b" 97 "a" 42 "*" 90 "Z" 89 "Y" 88 "X" 87 "W" 86 "V" 85 "U" 84 "T" 83 "S" 82 "R" 81 "Q" 80 "P" 79 "O" 78 "N" 77 "M" 76 "L" 75 "K" 74 "J" 73 "I" 72 "H" 71 "G" 70 "F" 69 "E" 68 "D" 67 "C" 66 "B" 65 "A" 57 "9" 56 "8" 55 "7" 54 "6" 53 "5" 52 "4" 51 "3" 50 "2" 49 "1" 48 "0" ;
VAL_ 2566888448 RATING_ID_05 122 "z" 121 "y" 120 "x" 119 "w" 118 "v" 117 "u" 116 "t" 115 "s" 114 "r" 113 "q" 112 "p" 111 "o" 110 "n" 109 "m" 108 "l" 107 "k" 106 "j" 105 "i" 104 "h" 103 "g" 102 "f" 101 "e" 100 "d" 99 "c" 98 "b" 97 "a" 42 "*" 90 "Z" 89 "Y" 88 "X" 87 "W" 86 "V" 85 "U" 84 "T" 83 "S" 82 "R" 81 "Q" 80 "P" 79 "O" 78 "N" 77 "M" 76 "L" 75 "K" 74 "J" 73 "I" 72 "H" 71 "G" 70 "F" 69 "E" 68 "D" 67 "C" 66 "B" 65 "A" 57 "9" 56 "8" 55 "7" 54 "6" 53 "5" 52 "4" 51 "3" 50 "2" 49 "1" 48 "0" ;
VAL_ 2566888448 RATING_ID_04 122 "z" 121 "y" 120 "x" 119 "w" 118 "v" 117 "u" 116 "t" 115 "s" 114 "r" 113 "q" 112 "p" 111 "o" 110 "n" 109 "m" 108 "l" 107 "k" 106 "j" 105 "i" 104 "h" 103 "g" 102 "f" 101 "e" 100 "d" 99 "c" 98 "b" 97 "a" 42 "*" 90 "Z" 89 "Y" 88 "X" 87 "W" 86 "V" 85 "U" 84 "T" 83 "S" 82 "R" 81 "Q" 80 "P" 79 "O" 78 "N" 77 "M" 76 "L" 75 "K" 74 "J" 73 "I" 72 "H" 71 "G" 70 "F" 69 "E" 68 "D" 67 "C" 66 "B" 65 "A" 57 "9" 56 "8" 55 "7" 54 "6" 53 "5" 52 "4" 51 "3" 50 "2" 49 "1" 48 "0" ;
VAL_ 2566888448 RATING_ID_03 122 "z" 121 "y" 120 "x" 119 "w" 118 "v" 117 "u" 116 "t" 115 "s" 114 "r" 113 "q" 112 "p" 111 "o" 110 "n" 109 "m" 108 "l" 107 "k" 106 "j" 105 "i" 104 "h" 103 "g" 102 "f" 101 "e" 100 "d" 99 "c" 98 "b" 97 "a" 42 "*" 90 "Z" 89 "Y" 88 "X" 87 "W" 86 "V" 85 "U" 84 "T" 83 "S" 82 "R" 81 "Q" 80 "P" 79 "O" 78 "N" 77 "M" 76 "L" 75 "K" 74 "J" 73 "I" 72 "H" 71 "G" 70 "F" 69 "E" 68 "D" 67 "C" 66 "B" 65 "A" 57 "9" 56 "8" 55 "7" 54 "6" 53 "5" 52 "4" 51 "3" 50 "2" 49 "1" 48 "0" ;
VAL_ 2566888448 RATING_ID_02 122 "z" 121 "y" 120 "x" 119 "w" 118 "v" 117 "u" 116 "t" 115 "s" 114 "r" 113 "q" 112 "p" 111 "o" 110 "n" 109 "m" 108 "l" 107 "k" 106 "j" 105 "i" 104 "h" 103 "g" 102 "f" 101 "e" 100 "d" 99 "c" 98 "b" 97 "a" 42 "*" 90 "Z" 89 "Y" 88 "X" 87 "W" 86 "V" 85 "U" 84 "T" 83 "S" 82 "R" 81 "Q" 80 "P" 79 "O" 78 "N" 77 "M" 76 "L" 75 "K" 74 "J" 73 "I" 72 "H" 71 "G" 70 "F" 69 "E" 68 "D" 67 "C" 66 "B" 65 "A" 57 "9" 56 "8" 55 "7" 54 "6" 53 "5" 52 "4" 51 "3" 50 "2" 49 "1" 48 "0" ;
VAL_ 2566888448 RATING_ID_01 122 "z" 121 "y" 120 "x" 119 "w" 118 "v" 117 "u" 116 "t" 115 "s" 114 "r" 113 "q" 112 "p" 111 "o" 110 "n" 109 "m" 108 "l" 107 "k" 106 "j" 105 "i" 104 "h" 103 "g" 102 "f" 101 "e" 100 "d" 99 "c" 98 "b" 97 "a" 42 "*" 90 "Z" 89 "Y" 88 "X" 87 "W" 86 "V" 85 "U" 84 "T" 83 "S" 82 "R" 81 "Q" 80 "P" 79 "O" 78 "N" 77 "M" 76 "L" 75 "K" 74 "J" 73 "I" 72 "H" 71 "G" 70 "F" 69 "E" 68 "D" 67 "C" 66 "B" 65 "A" 57 "9" 56 "8" 55 "7" 54 "6" 53 "5" 52 "4" 51 "3" 50 "2" 49 "1" 48 "0" ;
